VERSION ""

NS_ :

BS_:

BU_: VMCU VGGSECUSystem TECU OBDScanT2 HMIIOM EMS ECUspare2 ECUspare1 DACU CIOM BBM

BO_ 2634019608 Debug17_TECU_BB2: 8 TECU
 SG_ Debug_17_TECU : 0|64@1+ (1,0) [0|0] "" Vector__XXX

BO_ 2634019352 Debug16_TECU_BB2: 8 TECU
 SG_ Debug_16_TECU : 0|64@1+ (1,0) [0|0] "" Vector__XXX

BO_ 2634018584 Debug15_TECU_BB2: 8 TECU
 SG_ Debug_15_TECU : 0|64@1+ (1,0) [0|0] "" Vector__XXX

BO_ 2634018328 Debug14_TECU_BB2: 8 TECU
 SG_ Debug_14_TECU : 0|64@1+ (1,0) [0|0] "" Vector__XXX

BO_ 2634018072 Debug13_TECU_BB2: 8 TECU
 SG_ Debug_13_TECU : 0|64@1+ (1,0) [0|0] "" Vector__XXX

BO_ 2634017816 Debug12_TECU_BB2: 8 TECU
 SG_ Debug_12_TECU : 0|64@1+ (1,0) [0|0] "" Vector__XXX

BO_ 2634017560 Debug11_TECU_BB2: 8 TECU
 SG_ Debug_11_TECU : 0|64@1+ (1,0) [0|0] "" Vector__XXX

BO_ 2634021712 Debug11_DACU_BB2: 8 DACU
 SG_ Debug_11_DACU : 0|64@1+ (1,0) [0|0] "" Vector__XXX

BO_ 2634017304 Debug10_TECU_BB2: 8 TECU
 SG_ Debug_10_TECU : 0|64@1+ (1,0) [0|0] "" Vector__XXX

BO_ 2634021456 Debug10_DACU_BB2: 8 DACU
 SG_ Debug_10_DACU : 0|64@1+ (1,0) [0|0] "" Vector__XXX

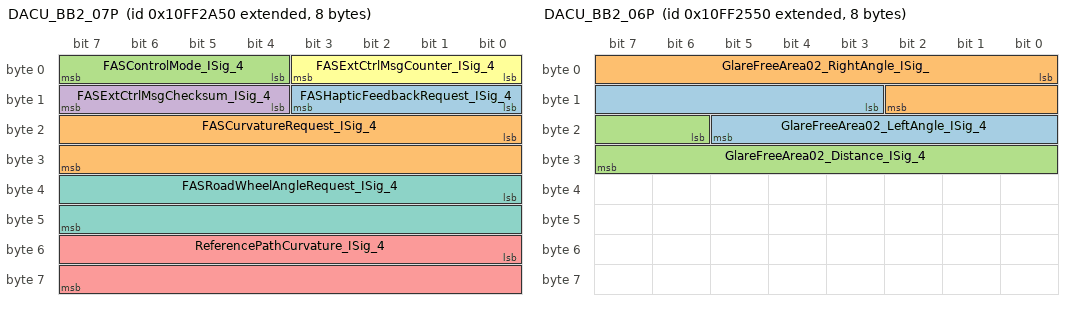
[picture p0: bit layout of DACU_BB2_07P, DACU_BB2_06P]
BO_ 2432641616 DACU_BB2_07P: 8 DACU
 SG_ FASHapticFeedbackRequest_ISig_4 : 8|4@1+ (1,0) [0|0] ""  VMCU
 SG_ FASCurvatureRequest_ISig_4 : 16|16@1+ (7.62939E-006,-0.2472) [-0.2472|0.25279207365] "per_meter"  VMCU
 SG_ FASControlMode_ISig_4 : 4|4@1+ (0.1,0) [0|1.5] ""  VMCU
 SG_ FASExtCtrlMsgChecksum_ISig_4 : 12|4@1+ (1,0) [0|0] ""  VMCU
 SG_ ReferencePathCurvature_ISig_4 : 48|16@1+ (7.62939E-006,-0.2472) [-0.2472|0.25279207365] "per_meter"  VMCU
 SG_ FASExtCtrlMsgCounter_ISig_4 : 0|4@1+ (1,0) [0|0] ""  VMCU
 SG_ FASRoadWheelAngleRequest_ISig_4 : 32|16@1+ (5E-005,-1.6) [-1.6|1.67675] "rad"  VMCU

BO_ 2432640336 DACU_BB2_06P: 8 DACU
 SG_ GlareFreeArea02_LeftAngle_ISig_4 : 11|11@1+ (0.0494,-31.65) [-31.65|69.4718] "deg"  VMCU
 SG_ GlareFreeArea02_RightAngle_ISig_ : 0|11@1+ (0.0494,-31.65) [-31.65|69.4718] "deg"  VMCU
 SG_ GlareFreeArea02_Distance_ISig_4 : 22|10@1+ (0.5,0) [0|511.5] "m"  VMCU

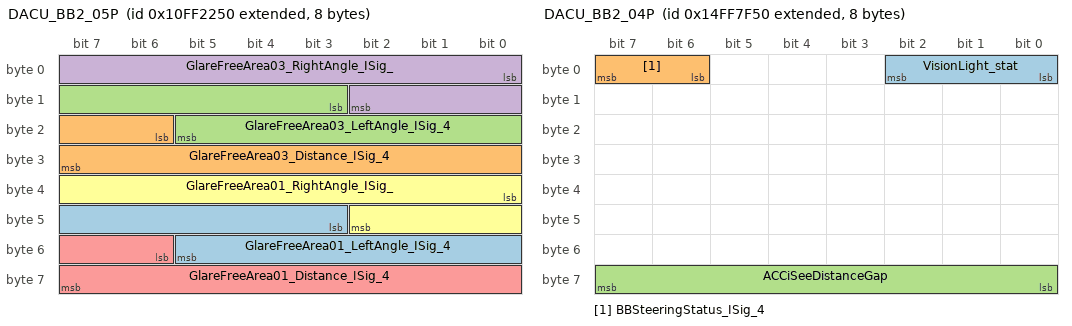
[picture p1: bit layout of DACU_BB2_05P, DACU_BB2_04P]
BO_ 2432639568 DACU_BB2_05P: 8 DACU
 SG_ GlareFreeArea01_LeftAngle_ISig_4 : 43|11@1+ (0.0494,-31.65) [-31.65|69.4718] "deg"  VMCU
 SG_ GlareFreeArea03_Distance_ISig_4 : 22|10@1+ (0.5,0) [0|511.5] "m"  VMCU
 SG_ GlareFreeArea03_LeftAngle_ISig_4 : 11|11@1+ (0.0494,-31.65) [-31.65|69.4718] "deg"  VMCU
 SG_ GlareFreeArea03_RightAngle_ISig_ : 0|11@1+ (0.0494,-31.65) [-31.65|69.4718] "deg"  VMCU
 SG_ GlareFreeArea01_Distance_ISig_4 : 54|10@1+ (0.5,0) [0|511.5] "m"  VMCU
 SG_ GlareFreeArea01_RightAngle_ISig_ : 32|11@1+ (0.0494,-31.65) [-31.65|69.4718] "deg"  VMCU

BO_ 2499772240 DACU_BB2_04P: 8 DACU
 SG_ VisionLight_stat : 0|3@1+ (1,0) [0|0] ""  VMCU
 SG_ BBSteeringStatus_ISig_4 : 6|2@1+ (1,0) [0|0] ""  BBM
 SG_ ACCiSeeDistanceGap : 56|8@1+ (1,-127) [-127|128] "m"  TECU

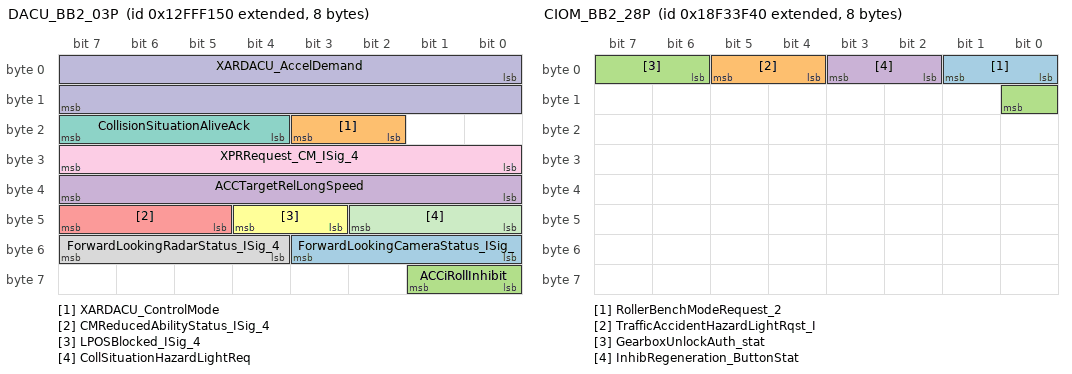
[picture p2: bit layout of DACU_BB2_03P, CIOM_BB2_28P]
BO_ 2466246992 DACU_BB2_03P: 8 DACU
 SG_ ForwardLookingCameraStatus_ISig_ : 48|4@1+ (1,0) [0|0] ""  HMIIOM
 SG_ XARDACU_ControlMode : 18|2@1+ (1,0) [0|0] ""  EMS,TECU
 SG_ ACCiRollInhibit : 56|2@1+ (1,0) [0|0] ""  TECU
 SG_ ACCTargetRelLongSpeed : 32|8@1+ (1,-125) [-125|130] "Km_per_h"  HMIIOM
 SG_ CMReducedAbilityStatus_ISig_4 : 45|3@1+ (1,0) [0|0] ""  HMIIOM
 SG_ LPOSBlocked_ISig_4 : 43|2@1+ (1,0) [0|0] ""  HMIIOM
 SG_ CollisionSituationAliveAck : 20|4@1+ (1,0) [0|15] "Count"  VMCU
 SG_ ForwardLookingRadarStatus_ISig_4 : 52|4@1+ (1,0) [0|0] ""  HMIIOM
 SG_ XPRRequest_CM_ISig_4 : 24|8@1+ (1,0) [0|255] "NotApplicable"  VMCU
 SG_ XARDACU_AccelDemand : 0|16@1+ (0.00048828125,-15.687) [-15.687|16.31251171875] "m_per_s_squared"  EMS,TECU
 SG_ CollSituationHazardLightReq : 40|3@1+ (1,0) [0|0] ""  VMCU

BO_ 2432690512 DACU_BB2_02P: 8 DACU
 SG_ PathDeviationDriverAlert_ISig_4 : 24|3@1+ (1,0) [0|0] ""  HMIIOM,VMCU
 SG_ CM_DisengageDrivelineRequest : 51|2@1+ (1,0) [0|0] ""  TECU
 SG_ ACCBrakeRequestStatus : 30|2@1+ (1,0) [0|0] ""  VMCU
 SG_ FrontalCollisionDriverAlert_ISig : 19|3@1+ (1,0) [0|0] ""  HMIIOM,VMCU
 SG_ ACCBrakeCapacityWarning_ISig_4 : 38|2@1+ (1,0) [0|0] ""  HMIIOM
 SG_ ACC_SGOFaultCondStat_SeatBelt_IS : 59|1@1+ (1,0) [0|0] ""  HMIIOM
 SG_ CM_Status_ISig_4 : 43|3@1+ (1,0) [0|0] ""  CIOM,VMCU,HMIIOM
 SG_ DASApplicationStatus_ISig_4 : 40|3@1+ (1,0) [0|0] ""  HMIIOM,VMCU,CIOM
 SG_ ACC_Status_ISig_4 : 16|3@1+ (1,0) [0|0] ""  VMCU,HMIIOM,TECU
 SG_ LKSApplicationStatus_ISig_4 : 27|3@1+ (1,0) [0|0] ""  CIOM,VMCU,HMIIOM
 SG_ LCSSystemStatus : 48|3@1+ (1,0) [0|0] ""  HMIIOM,CIOM
 SG_ ACC_SGOFaultCondStat_SigStat_ISi : 60|1@1+ (1,0) [0|0] ""  HMIIOM
 SG_ ACC_SGOFaultCondStat_Target_ISig : 58|1@1+ (1,0) [0|0] ""  HMIIOM
 SG_ FCW_Status_ISig_4 : 46|2@1+ (1,0) [0|0] ""  HMIIOM,CIOM,VMCU
 SG_ DriverImpairedDriverAlert_ISig_4 : 32|3@1+ (1,0) [0|0] ""  HMIIOM,VMCU
 SG_ DriverVigilanceLevel_ISig_4 : 35|3@1+ (1,0) [0|0] ""  HMIIOM,VMCU
 SG_ ACCForwardVehicleSpeed_ISig_4 : 8|8@1+ (1,0) [0|255] "Km_per_h"  TECU,HMIIOM
 SG_ ACC_SGOFaultCondStat_Door_ISig_4 : 57|1@1+ (1,0) [0|0] ""  HMIIOM
 SG_ ACCTargetDetected_ISig_4 : 22|2@1+ (1,0) [0|0] ""  HMIIOM
 SG_ ACCForwardVehicleDistance_ISig_4 : 0|8@1+ (1,0) [0|255] "m"  TECU,HMIIOM
 SG_ LKSCorrectiveSteeringStatus : 61|3@1+ (1,0) [0|0] ""  CIOM,HMIIOM
 SG_ ACC_SGOFaultCondStat_Other_ISig_ : 55|1@1+ (1,0) [0|0] ""  HMIIOM
 SG_ LCSSoundSettingStatus : 53|2@1+ (1,0) [0|0] ""  HMIIOM
 SG_ ACC_SGOFaultCondStat_Speed_ISig_ : 56|1@1+ (1,0) [0|0] ""  HMIIOM

BO_ 2499750528 CIOM_BB2_30S_FCM: 8 TECU
 SG_ CIOM_BB2_30S_FCS : 0|64@1+ (1,0) [0|0] ""  CIOM

BO_ 2499750527 CIOM_BB2_30S: 16 CIOM
 SG_ EncryptedGBUnlockAuth_stat : 0|128@1+ (1,0) [0|0] ""  TECU

BO_ 2432685120 CIOM_BB2_29P: 8 CIOM
 SG_ LKSCSEnableSwitch_rqst : 0|2@1+ (1,0) [0|0] ""  DACU

BO_ 2566078272 CIOM_BB2_28P: 8 CIOM
 SG_ RollerBenchModeRequest_2 : 0|2@1+ (1,0) [0|0] ""  HMIIOM
 SG_ TrafficAccidentHazardLightRqst_I : 4|2@1+ (1,0) [0|0] ""  VMCU
 SG_ GearboxUnlockAuth_stat : 6|3@1+ (1,0) [0|0] ""  TECU
 SG_ InhibRegeneration_ButtonStat : 2|2@1+ (1,0) [0|0] ""  HMIIOM

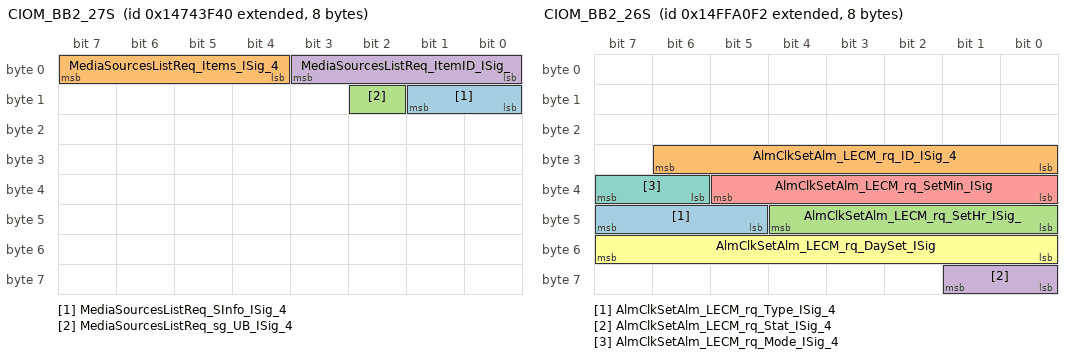
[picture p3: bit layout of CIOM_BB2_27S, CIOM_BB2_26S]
BO_ 2490646336 CIOM_BB2_27S: 8 CIOM
 SG_ MediaSourcesListReq_SInfo_ISig_4 : 8|2@1+ (1,0) [0|0] ""  HMIIOM
 SG_ MediaSourcesListReq_Items_ISig_4 : 4|4@1+ (1,0) [0|0] ""  HMIIOM
 SG_ MediaSourcesListReq_sg_UB_ISig_4 : 10|1@1+ (1,0) [0|0] ""  HMIIOM
 SG_ MediaSourcesListReq_ItemID_ISig_ : 0|4@1+ (1,0) [0|0] ""  HMIIOM

BO_ 2499780850 CIOM_BB2_26S: 8 CIOM
 SG_ AlmClkSetAlm_LECM_rq_Type_ISig_4 : 45|3@1+ (1,0) [0|0] ""  HMIIOM
 SG_ AlmClkSetAlm_LECM_rq_ID_ISig_4 : 24|7@1+ (1,0) [0|0] ""  HMIIOM
 SG_ AlmClkSetAlm_LECM_rq_SetHr_ISig_ : 40|5@1+ (1,0) [0|31] "h"  HMIIOM
 SG_ AlmClkSetAlm_LECM_rq_Stat_ISig_4 : 56|2@1+ (1,0) [0|0] ""  HMIIOM
 SG_ AlmClkSetAlm_LECM_rq_SetMin_ISig : 32|6@1+ (1,0) [0|63] "min"  HMIIOM
 SG_ AlmClkSetAlm_LECM_rq_DaySet_ISig : 48|8@1+ (1,0) [0|255] ""  HMIIOM
 SG_ AlmClkSetAlm_LECM_rq_Mode_ISig_4 : 38|2@1+ (1,0) [0|0] ""  HMIIOM

BO_ 2482978624 CIOM_BB2_25P: 8 CIOM
 SG_ TipperTailGateRequest_UB_ISig_4 : 23|1@1+ (1,0) [0|0] ""  BBM
 SG_ LoadDistributionRequested_UB_ISi : 36|1@1+ (1,0) [0|0] ""  VMCU
 SG_ TipperUpDownRequest_ISig_4 : 17|3@1+ (1,0) [0|0] ""  BBM
 SG_ TipperTarpaulinRequest_UB_ISig_4 : 27|1@1+ (1,0) [0|0] ""  BBM
 SG_ LoadDistributionRequested_ISig_4 : 28|4@1+ (1,0) [0|0] ""  VMCU
 SG_ TipperShakerRequest_UB_ISig_4 : 21|1@1+ (1,0) [0|0] ""  BBM
 SG_ TailLiftMotionRequest_UB_ISig_4 : 20|1@1+ (1,0) [0|0] ""  BBM
 SG_ TipperTailGateRequest_ISig_4 : 8|3@1+ (1,0) [0|0] ""  BBM
 SG_ TipperTippingBodySelection_ISig_ : 6|2@1+ (1,0) [0|0] ""  BBM
 SG_ TipperEmergencyStop_ISig_4 : 0|2@1+ (1,0) [0|0] ""  BBM
 SG_ TipperTippingBodySelection_UB_IS : 26|1@1+ (1,0) [0|0] ""  BBM
 SG_ ExtraBbWrcWatchdog_ISig_4 : 2|2@1+ (1,0) [0|0] ""  BBM
 SG_ TipperEmergencyStop_UB_ISig_4 : 25|1@1+ (1,0) [0|0] ""  BBM
 SG_ AutoFrontWheelDriveDrvReq : 37|2@1+ (1,0) [0|0] ""  VMCU
 SG_ FrontalCollisionAccidentStatus_I : 39|2@1+ (1,0) [0|0] ""  DACU
 SG_ ShortStopHeater_cmd_ISig_4 : 34|2@1+ (1,0) [0|0] ""  VMCU
 SG_ TipperUpDownRequest_UB_ISig_4 : 24|1@1+ (1,0) [0|0] ""  BBM
 SG_ TailLiftMotionRequest_ISig_4 : 14|3@1+ (1,0) [0|0] ""  BBM
 SG_ TipperShakerRequest_ISig_4 : 4|2@1+ (1,0) [0|0] ""  BBM
 SG_ TipperTarpaulinRequest_ISig_4 : 11|3@1+ (1,0) [0|0] ""  BBM
 SG_ ExtraHeating_status_ISig_4 : 32|2@1+ (1,0) [0|0] ""  HMIIOM
 SG_ ExtraBbWrcWatchdog_UB_ISig_4 : 22|1@1+ (1,0) [0|0] ""  BBM

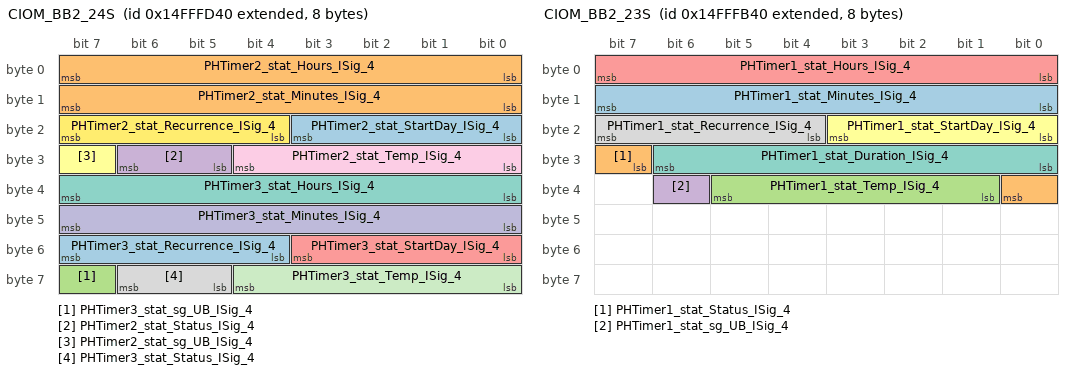
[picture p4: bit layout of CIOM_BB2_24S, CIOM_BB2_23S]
BO_ 2499804480 CIOM_BB2_24S: 8 CIOM
 SG_ PHTimer3_stat_Recurrence_ISig_4 : 52|4@1+ (1,0) [0|0] ""  HMIIOM
 SG_ PHTimer2_stat_Hours_ISig_4 : 0|8@1+ (1,0) [0|255] "h"  HMIIOM
 SG_ PHTimer3_stat_sg_UB_ISig_4 : 63|1@1+ (1,0) [0|0] ""  HMIIOM
 SG_ PHTimer2_stat_Status_ISig_4 : 29|2@1+ (1,0) [0|0] ""  HMIIOM
 SG_ PHTimer3_stat_StartDay_ISig_4 : 48|4@1+ (1,0) [0|0] ""  HMIIOM
 SG_ PHTimer2_stat_sg_UB_ISig_4 : 31|1@1+ (1,0) [0|0] ""  HMIIOM
 SG_ PHTimer3_stat_Hours_ISig_4 : 32|8@1+ (1,0) [0|255] "h"  HMIIOM
 SG_ PHTimer3_stat_Status_ISig_4 : 61|2@1+ (1,0) [0|0] ""  HMIIOM
 SG_ PHTimer2_stat_Temp_ISig_4 : 24|5@1+ (1,0) [0|0] ""  HMIIOM
 SG_ PHTimer3_stat_Minutes_ISig_4 : 40|8@1+ (1,0) [0|255] "min"  HMIIOM
 SG_ PHTimer3_stat_Temp_ISig_4 : 56|5@1+ (1,0) [0|0] ""  HMIIOM
 SG_ PHTimer2_stat_Recurrence_ISig_4 : 20|4@1+ (1,0) [0|0] ""  HMIIOM
 SG_ PHTimer2_stat_StartDay_ISig_4 : 16|4@1+ (1,0) [0|0] ""  HMIIOM
 SG_ PHTimer2_stat_Minutes_ISig_4 : 8|8@1+ (1,0) [0|255] "min"  HMIIOM

BO_ 2499803968 CIOM_BB2_23S: 8 CIOM
 SG_ PHTimer1_stat_Minutes_ISig_4 : 8|8@1+ (1,0) [0|255] "min"  HMIIOM
 SG_ PHTimer1_stat_Status_ISig_4 : 31|2@1+ (1,0) [0|0] ""  HMIIOM
 SG_ PHTimer1_stat_Temp_ISig_4 : 33|5@1+ (1,0) [0|0] ""  HMIIOM
 SG_ PHTimer1_stat_sg_UB_ISig_4 : 38|1@1+ (1,0) [0|0] ""  HMIIOM
 SG_ PHTimer1_stat_Hours_ISig_4 : 0|8@1+ (1,0) [0|255] "h"  HMIIOM
 SG_ PHTimer1_stat_StartDay_ISig_4 : 16|4@1+ (1,0) [0|0] ""  HMIIOM
 SG_ PHTimer1_stat_Duration_ISig_4 : 24|7@1+ (1,0) [0|127] "min"  HMIIOM
 SG_ PHTimer1_stat_Recurrence_ISig_4 : 20|4@1+ (1,0) [0|0] ""  HMIIOM

BO_ 2499801342 CIOM_BB2_22S_FCM: 8 HMIIOM
 SG_ CIOM_BB2_22S_FCS : 0|64@1+ (1,0) [0|1] ""  CIOM

BO_ 2499801341 CIOM_BB2_22S: 10 CIOM
 SG_ EngineTimer_stat_Timer3StartDay_ : 20|4@1+ (1,0) [0|0] ""  HMIIOM
 SG_ EngineTimer_stat_Timer3_Status_I : 76|2@1+ (1,0) [0|0] ""  HMIIOM
 SG_ EngineTimer_stat_Timer3Minutes_I : 56|8@1+ (1,0) [0|255] "min"  HMIIOM
 SG_ EngineTimer_stat_Timer3Hours_ISi : 32|8@1+ (1,0) [0|255] "h"  HMIIOM
 SG_ EngineTimer_stat_Timer3Recurr_IS : 8|4@1+ (1,0) [0|0] ""  HMIIOM
 SG_ EngineTimer_stat_Timer1Hours_ISi : 40|8@1+ (1,0) [0|255] "h"  HMIIOM
 SG_ EngineTimer_stat_Timer2Hours_ISi : 48|8@1+ (1,0) [0|255] "h"  HMIIOM
 SG_ EngineTimer_stat_sg_UB_ISig_4 : 78|1@1+ (1,0) [0|0] ""  HMIIOM
 SG_ EngineTimer_stat_Timer2StartDay_ : 16|4@1+ (1,0) [0|0] ""  HMIIOM
 SG_ EngineTimer_stat_Timer1Recurr_IS : 0|4@1+ (1,0) [0|0] ""  HMIIOM
 SG_ EngineTimer_stat_Timer2Recurr_IS : 4|4@1+ (1,0) [0|0] ""  HMIIOM
 SG_ EngineTimer_stat_Timer1Minutes_I : 24|8@1+ (1,0) [0|255] "min"  HMIIOM
 SG_ EngineTimer_stat_Timer1StartDay_ : 12|4@1+ (1,0) [0|0] ""  HMIIOM
 SG_ EngineTimer_stat_Timer2_Status_I : 74|2@1+ (1,0) [0|0] ""  HMIIOM
 SG_ EngineTimer_stat_Timer2Minutes_I : 64|8@1+ (1,0) [0|255] "min"  HMIIOM
 SG_ EngineTimer_stat_Timer1_Status_I : 72|2@1+ (1,0) [0|0] ""  HMIIOM

BO_ 2516513011 CIOM_BB2_21S: 8 CIOM
 SG_ DynamicCode_value : 0|32@1+ (1,0) [0|4294967295] "NotApplicable"  HMIIOM

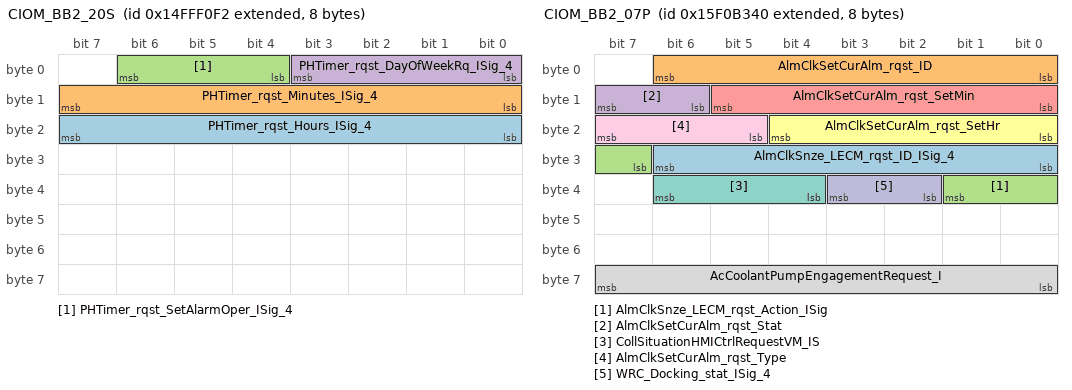
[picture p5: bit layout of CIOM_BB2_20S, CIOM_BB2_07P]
BO_ 2499801330 CIOM_BB2_20S: 8 CIOM
 SG_ PHTimer_rqst_Hours_ISig_4 : 16|8@1+ (1,0) [0|255] "h"  HMIIOM
 SG_ PHTimer_rqst_Minutes_ISig_4 : 8|8@1+ (1,0) [0|255] "min"  HMIIOM
 SG_ PHTimer_rqst_SetAlarmOper_ISig_4 : 4|3@1+ (1,0) [0|0] ""  HMIIOM
 SG_ PHTimer_rqst_DayOfWeekRq_ISig_4 : 0|4@1+ (1,0) [0|0] ""  HMIIOM

BO_ 2499764033 CIOM_BB2_13S_FCM: 8 EMS
 SG_ CIOM_BB2_13S_FCS : 0|64@1+ (1,0) [0|0] ""  CIOM

BO_ 2499764032 CIOM_BB2_13S: 16 CIOM
 SG_ EngineStartAuth_stat : 0|128@1+ (1,0) [0|0] ""  EMS

BO_ 2499747649 CIOM_BB2_12S_FCM: 8 VMCU
 SG_ CIOM_BB2_12S_FCS : 0|64@1+ (1,0) [0|0] ""  CIOM

BO_ 2499747648 CIOM_BB2_12S: 16 CIOM
 SG_ KeyAuthEncrypted_stat : 0|128@1+ (1,0) [0|0] ""  VMCU

BO_ 2498741568 CIOM_BB2_11P: 8 CIOM
 SG_ WindscreenDefrostInd_cmd_ISig_4 : 0|1@1+ (1,0) [0|0] ""  HMIIOM
 SG_ ACCoolingFanSpeedRequest : 32|16@1+ (1,0) [0|65535] "rpm"  EMS
 SG_ AutoMode_IndicationCmd_ISig_4 : 1|1@1+ (1,0) [0|0] ""  HMIIOM
 SG_ CabTilt_rqst : 4|2@1+ (1,0) [0|0] ""  VMCU
 SG_ ACdisplayIndication_Cmd_ISig_4 : 53|3@1+ (1,0) [0|0] ""  HMIIOM
 SG_ TemperatureRqstIndication_cmd_IS : 48|5@1+ (1,0) [0|0] ""  HMIIOM
 SG_ Pto3CabRequest : 6|2@1+ (1,0) [0|0] ""  BBM,VMCU
 SG_ Pto4CabRequest : 16|2@1+ (1,0) [0|0] ""  VMCU,BBM
 SG_ ACCoolingFanSpeedRequest_UB : 61|1@1+ (1,0) [0|0] ""  EMS
 SG_ SRSAirbagStatus_ISig_4 : 8|2@1+ (1,0) [0|0] ""  HMIIOM,VMCU
 SG_ Area_9level_Indication_cmd_ISig_ : 18|4@1+ (1,0) [0|0] ""  HMIIOM
 SG_ AutoDefogIndication_Cmd_ISig_4 : 27|3@1+ (1,0) [0|0] ""  HMIIOM
 SG_ FrontLidAjar_Stat : 30|2@1+ (1,0) [0|0] ""  VMCU
 SG_ ParkingHeaterCleaning_Rqst_ISig_ : 22|2@1+ (1,0) [0|0] ""  HMIIOM
 SG_ Pto2CabRequest : 12|2@1+ (1,0) [0|0] ""  BBM,VMCU
 SG_ AutoBlowerLevelIndication_Cmd_IS : 24|3@1+ (1,0) [0|0] ""  HMIIOM
 SG_ SeatSwivelWarning_rqst : 14|2@1+ (1,0) [0|0] ""  HMIIOM
 SG_ AQSmodeIndication_Cmd_ISig_4 : 2|2@1+ (1,0) [0|0] ""  HMIIOM
 SG_ TemporaryRSLDriverRequest : 59|2@1+ (1,0) [0|0] ""  VMCU
 SG_ Pto1CabRequest : 10|2@1+ (1,0) [0|0] ""  VMCU,BBM

BO_ 2483023936 CIOM_BB2_10P: 8 CIOM
 SG_ LCS_EnableSwitch_rqst : 40|2@1+ (1,0) [0|0] ""  DACU
 SG_ PH_Activation_cmd_ISig_4 : 33|3@1+ (1,0) [0|0] ""  HMIIOM
 SG_ EscCrossCountryActivation_rqst : 52|2@1+ (1,0) [0|0] ""  VMCU
 SG_ StaticCornerLightMode : 54|2@1+ (1,0) [0|0] ""  VMCU
 SG_ SplitBoxDifflockActvnDrvrRqst_IS : 48|2@1+ (1,0) [0|0] ""  HMIIOM,EMS,VMCU,TECU
 SG_ ConstructionSwitch_stat : 50|2@1+ (1,0) [0|0] ""  TECU,HMIIOM
 SG_ ATCFrontWheelDriveRequest : 61|2@1+ (1,0) [0|0] ""  HMIIOM
 SG_ EscCabActionRequest : 8|3@1+ (1,0) [0|0] ""  VMCU
 SG_ AdjustRequestForIdle : 58|3@1+ (1,0) [0|0] ""  VMCU
 SG_ SCL_LogicPowerOutput_stat : 36|2@1+ (1,0) [0|0] ""  VMCU
 SG_ PinCode_validity_time : 0|8@1+ (1,1) [1|256] "h"  HMIIOM
 SG_ StatTrailerBrakeSwitchStatus : 14|2@1+ (1,0) [0|0] ""  VMCU
 SG_ SplitBoxDifflockActvnDrvrRqst_UB : 32|1@1+ (1,0) [0|0] ""  EMS,TECU,VMCU,HMIIOM
 SG_ RoofHatch_HMI_rqst : 16|3@1+ (1,0) [0|0] ""  VMCU
 SG_ EscCabEnable : 38|2@1+ (1,0) [0|0] ""  HMIIOM,VMCU
 SG_ ExtraSideMarkers_Rqst : 19|2@1+ (1,0) [0|0] ""  VMCU
 SG_ LevelingThumbwheel_stat : 24|5@1+ (1,0) [0|0] ""  VMCU
 SG_ MemoDisplayIndication_Cmd_ISig_4 : 11|3@1+ (1,0) [0|0] ""  HMIIOM
 SG_ FCW_Enable : 42|2@1+ (1,0) [0|0] ""  DACU
 SG_ DASActivation_rqst : 44|2@1+ (1,0) [0|0] ""  DACU
 SG_ DriverSeatBeltSwitch_ISig_4 : 22|2@1+ (1,0) [0|0] ""  VMCU,DACU,BBM,HMIIOM
 SG_ PinCode_stat : 29|3@1+ (1,0) [0|0] ""  HMIIOM
 SG_ WarmUp_Request : 56|2@1+ (1,0) [0|0] ""  EMS
 SG_ LKSEnableSwitch_rqst : 46|2@1+ (1,0) [0|0] ""  DACU

BO_ 2515579712 CIOM_BB2_07P: 8 CIOM
 SG_ AlmClkSnze_LECM_rqst_ID_ISig_4 : 24|7@1+ (1,0) [0|0] ""  HMIIOM
 SG_ AlmClkSetCurAlm_rqst_ID : 0|7@1+ (1,0) [0|0] ""  HMIIOM
 SG_ AlmClkSnze_LECM_rqst_Action_ISig : 31|3@1+ (1,0) [0|0] ""  HMIIOM
 SG_ AlmClkSetCurAlm_rqst_Stat : 14|2@1+ (1,0) [0|0] ""  HMIIOM
 SG_ AlmClkSetCurAlm_rqst_SetMin : 8|6@1+ (1,0) [0|63] "min"  HMIIOM
 SG_ AlmClkSetCurAlm_rqst_SetHr : 16|5@1+ (1,0) [0|31] "h"  HMIIOM
 SG_ CollSituationHMICtrlRequestVM_IS : 36|3@1+ (1,0) [0|0] ""  HMIIOM
 SG_ AcCoolantPumpEngagementRequest_I : 56|8@1+ (0.4,0) [0|102] "Percent"  EMS
 SG_ AlmClkSetCurAlm_rqst_Type : 21|3@1+ (1,0) [0|0] ""  HMIIOM
 SG_ WRC_Docking_stat_ISig_4 : 34|2@1+ (1,0) [0|0] ""  HMIIOM

BO_ 2482995008 CIOM_BB2_06P: 8 CIOM
 SG_ LiftAxle1DirectControl_UB_ISig_4 : 59|1@1+ (1,0) [0|0] ""  VMCU
 SG_ Regeneration2PosSwitchStatus : 54|2@1+ (1,0) [0|0] ""  HMIIOM
 SG_ WRCEngineStopRequest_ISig_4 : 38|2@1+ (1,0) [0|0] ""  BBM
 SG_ LiftAxle1DirectControl_ISig_4 : 56|3@1+ (1,0) [0|0] ""  VMCU
 SG_ PanicAlarmFromKeyfob_rqst : 2|2@1+ (1,0) [0|0] ""  VMCU
 SG_ InhibRegenerationSwitch_stat : 42|2@1+ (1,0) [0|0] ""  HMIIOM
 SG_ ParkingClimate_IndicationCmd_ISi : 51|3@1+ (1,0) [0|0] ""  HMIIOM
 SG_ DriverDoorAjar_stat_ISig_4 : 27|3@1+ (1,0) [0|0] ""  HMIIOM
 SG_ WRCEngineStartRequest_ISig_4 : 36|2@1+ (1,0) [0|0] ""  BBM
 SG_ RegenerationPushButtonStatus_ISi : 60|2@1+ (1,0) [0|0] ""  HMIIOM
 SG_ RegenerationSwitchStatus_ISig_4 : 48|3@1+ (1,0) [0|0] ""  HMIIOM
 SG_ DoorLock_stat_ISig_4 : 8|4@1+ (1,0) [0|0] ""  BBM,HMIIOM
 SG_ WRCEngineStartRequest_UB_ISig_4 : 40|1@1+ (1,0) [0|0] ""  BBM
 SG_ LuggageAjar_stat_ISig_4 : 32|3@1+ (1,0) [0|0] ""  HMIIOM
 SG_ AlarmStatus_stat_ISig_4 : 44|4@1+ (1,0) [0|0] ""  HMIIOM
 SG_ AlarmTriggeringCause_stat_ISig_4 : 12|4@1+ (1,0) [0|0] ""  HMIIOM
 SG_ DoorsAjar_stat_UB_ISig_4 : 35|1@1+ (1,0) [0|0] ""  DACU,VMCU,HMIIOM,BBM
 SG_ DoorsAjar_stat_ISig_4 : 16|3@1+ (1,0) [0|0] ""  HMIIOM,VMCU,DACU,BBM
 SG_ WRCEngineStopRequest_UB_ISig_4 : 41|1@1+ (1,0) [0|0] ""  BBM
 SG_ DoorAutoFunction_rqst : 22|2@1+ (1,0) [0|0] ""  VMCU

CM_ SG_ 2466246992 XARDACU_AccelDemand "65024 - 65279 Error ; 65280 - 65535 Not available";
CM_ SG_ 2432690512 ACCForwardVehicleSpeed_ISig_4 "254 Error ; 255 Not available";
CM_ SG_ 2432690512 ACCForwardVehicleDistance_ISig_4 "254 Error ; 255 Not Available";
CM_ SG_ 2499780850 AlmClkSetAlm_LECM_rq_SetHr_ISig_ "30 Error ; 31 Not Available";
CM_ SG_ 2499780850 AlmClkSetAlm_LECM_rq_SetMin_ISig "62 Error ; 63 Not Available";
CM_ SG_ 2499804480 PHTimer2_stat_Hours_ISig_4 "254 Error ; 255 Not available";
CM_ SG_ 2499804480 PHTimer3_stat_Hours_ISig_4 "254 Error ; 255 Not available";
CM_ SG_ 2499804480 PHTimer3_stat_Minutes_ISig_4 "254 Error ; 255 Not available";
CM_ SG_ 2499804480 PHTimer2_stat_Minutes_ISig_4 "254 Error ; 255 Not available";
CM_ SG_ 2499803968 PHTimer1_stat_Minutes_ISig_4 "254 Error ; 255 Not available";
CM_ SG_ 2499803968 PHTimer1_stat_Hours_ISig_4 "254 Error ; 255 Not available";
CM_ SG_ 2499803968 PHTimer1_stat_Duration_ISig_4 "126 Error ; 127 Not available";
CM_ SG_ 2499801341 EngineTimer_stat_Timer3Minutes_I "254 Error ; 255 Not available";
CM_ SG_ 2499801341 EngineTimer_stat_Timer3Hours_ISi "254 Error ; 255 Not available";
CM_ SG_ 2499801341 EngineTimer_stat_Timer1Hours_ISi "254 Error ; 255 Not available";
CM_ SG_ 2499801341 EngineTimer_stat_Timer2Hours_ISi "254 Error ; 255 Not available";
CM_ SG_ 2499801341 EngineTimer_stat_Timer1Minutes_I "254 Error ; 255 Not available";
CM_ SG_ 2499801341 EngineTimer_stat_Timer2Minutes_I "254 Error ; 255 Not available";
CM_ SG_ 2499801330 PHTimer_rqst_Hours_ISig_4 "254 Error ; 255 Not available";
CM_ SG_ 2499801330 PHTimer_rqst_Minutes_ISig_4 "254 Error ; 255 Not available";
CM_ SG_ 2498741568 ACCoolingFanSpeedRequest "65024 - 65279 Error ; 65280 - 65535 Not available";
BA_DEF_ BO_  "GenMsgStartDelayTime" INT 0 0;
BA_DEF_ BO_  "GenMsgDelayTime" INT 0 0;
BA_DEF_ BO_  "GenMsgCycleTime" INT 0 0;
BA_DEF_ BO_  "GenMsgSendType" ENUM  "Cyclic","NotUsed","NotUsed","NotUsed","NotUsed","NotUsed","NotUsed","IfActive","NoMsgSendType","NotUsed";
BA_DEF_ SG_  "GenSigStartValue" INT 0 0;
BA_DEF_ SG_  "GenSigCycleTimeActive" INT 0 0;
BA_DEF_ SG_  "GenSigCycleTime" INT 0 0;
BA_DEF_ SG_  "GenSigSendType" ENUM  "Cyclic","OnWrite","OnWriteWithRepetition","OnChange","OnChangeWithRepetition","IfActive","IfActiveWithRepetition","NoSigSendType","NotUsed","NotUsed","NotUsed","NotUsed","NotUsed";
BA_DEF_ BO_  "VFrameFormat" ENUM  "StandardCAN","ExtendedCAN","reserved","J1939PG";
BA_DEF_ SG_  "SigType" ENUM  "Default","Range","RangeSigned","ASCII","Discrete","Control","ReferencePGN","DTC","StringDelimiter","StringLength","StringLengthControl";
BA_DEF_ SG_  "SeToolVersion_SIGNAL" STRING ;
BA_DEF_ SG_  "SeToolUniqueID_SIGNAL" STRING ;
BA_DEF_ SG_  "SeToolOwnerSigGroup_SIGNAL" STRING ;
BA_DEF_ SG_  "SeToolOwnerSigGroupID_SIGNAL" STRING ;
BA_DEF_ SG_  "SeToolName_SIGNAL" STRING ;
BA_DEF_ SG_  "SeToolItemID_SIGNAL" STRING ;
BA_DEF_ SG_  "SeToolAncestorID_SIGNAL" STRING ;
BA_DEF_ SG_  "Platform_VMCU1_Sig" ENUM  "No","Yes";
BA_DEF_ BO_  "NmAsrMessage" ENUM  "No","Yes";
BA_DEF_ SG_  "NeedsUpdateBit" ENUM  "No","Yes";
BA_DEF_ SG_  "MmAnSignal" ENUM  "No","Yes";
BA_DEF_ SG_  "GenSigMaxLatency" INT 0 65535;
BA_DEF_ SG_  "GenSigILSupport" ENUM  "Yes","No";
BA_DEF_ BO_  "GenMsgRequestable" INT 0 1;
BA_DEF_ BO_  "GenMsgILSupport" ENUM  "No","Yes";
BA_DEF_ BO_  "DiagUUDTResponse" ENUM  "No","Yes";
BA_DEF_ BO_  "DiagState" ENUM  "No","Yes";
BA_DEF_ BO_  "DiagResponse" ENUM  "No","Yes";
BA_DEF_ BO_  "DiagRequest" ENUM  "No","Yes";
BA_DEF_ BO_  "DiagConnection" HEX 0 65535;
BA_DEF_ BO_  "CanTpSTmin" INT 0 255;
BA_DEF_ BO_  "CanTpFcFrameId" HEX 0 2147483647;
BA_DEF_ BO_  "CanTpBs" INT 0 255;
BA_DEF_ SG_  "SystemSignalLongSymbol" STRING ;
BA_DEF_REL_ BU_SG_REL_  "GenSigTimeoutTime" INT 0 65535;
BA_DEF_REL_ BU_SG_REL_  "GenSigFirstTimeoutTime" INT 0 65535;
BA_DEF_DEF_  "GenMsgStartDelayTime" 0;
BA_DEF_DEF_  "GenMsgDelayTime" 0;
BA_DEF_DEF_  "GenMsgCycleTime" 0;
BA_DEF_DEF_  "GenMsgSendType" "Cyclic";
BA_DEF_DEF_  "GenSigStartValue" 0;
BA_DEF_DEF_  "GenSigCycleTimeActive" 0;
BA_DEF_DEF_  "GenSigCycleTime" 0;
BA_DEF_DEF_  "GenSigSendType" "Cyclic";
BA_DEF_DEF_  "VFrameFormat" "ExtendedCAN";
BA_DEF_DEF_  "SigType" "Default";
BA_DEF_DEF_  "SeToolVersion_SIGNAL" "";
BA_DEF_DEF_  "SeToolUniqueID_SIGNAL" "";
BA_DEF_DEF_  "SeToolOwnerSigGroup_SIGNAL" "";
BA_DEF_DEF_  "SeToolOwnerSigGroupID_SIGNAL" "";
BA_DEF_DEF_  "SeToolName_SIGNAL" "";
BA_DEF_DEF_  "SeToolItemID_SIGNAL" "";
BA_DEF_DEF_  "SeToolAncestorID_SIGNAL" "";
BA_DEF_DEF_  "Platform_VMCU1_Sig" "No";
BA_DEF_DEF_  "NmAsrMessage" "No";
BA_DEF_DEF_  "NeedsUpdateBit" "No";
BA_DEF_DEF_  "MmAnSignal" "No";
BA_DEF_DEF_  "GenSigMaxLatency" 0;
BA_DEF_DEF_  "GenSigILSupport" "Yes";
BA_DEF_DEF_  "GenMsgRequestable" 1;
BA_DEF_DEF_  "GenMsgILSupport" "Yes";
BA_DEF_DEF_  "DiagUUDTResponse" "No";
BA_DEF_DEF_  "DiagState" "No";
BA_DEF_DEF_  "DiagResponse" "No";
BA_DEF_DEF_  "DiagRequest" "No";
BA_DEF_DEF_  "DiagConnection" 0;
BA_DEF_DEF_  "CanTpSTmin" 0;
BA_DEF_DEF_  "CanTpFcFrameId" 2147483647;
BA_DEF_DEF_  "CanTpBs" 255;
BA_DEF_DEF_REL_ "GenSigTimeoutTime" 0;
BA_DEF_DEF_REL_ "GenSigFirstTimeoutTime" 0;
BA_DEF_DEF_  "SystemSignalLongSymbol" "";
BA_ "GenMsgSendType" BO_ 2634019608 8;
BA_ "GenMsgDelayTime" BO_ 2634019608 195;
BA_ "GenMsgStartDelayTime" BO_ 2634019608 50;
BA_ "GenMsgSendType" BO_ 2634019352 8;
BA_ "GenMsgDelayTime" BO_ 2634019352 195;
BA_ "GenMsgStartDelayTime" BO_ 2634019352 50;
BA_ "GenMsgSendType" BO_ 2634018584 8;
BA_ "GenMsgDelayTime" BO_ 2634018584 195;
BA_ "GenMsgStartDelayTime" BO_ 2634018584 50;
BA_ "GenMsgSendType" BO_ 2634018328 8;
BA_ "GenMsgDelayTime" BO_ 2634018328 195;
BA_ "GenMsgStartDelayTime" BO_ 2634018328 50;
BA_ "GenMsgSendType" BO_ 2634018072 8;
BA_ "GenMsgDelayTime" BO_ 2634018072 195;
BA_ "GenMsgStartDelayTime" BO_ 2634018072 50;
BA_ "GenMsgSendType" BO_ 2634017816 8;
BA_ "GenMsgDelayTime" BO_ 2634017816 195;
BA_ "GenMsgStartDelayTime" BO_ 2634017816 50;
BA_ "GenMsgSendType" BO_ 2634017560 8;
BA_ "GenMsgDelayTime" BO_ 2634017560 195;
BA_ "GenMsgStartDelayTime" BO_ 2634017560 50;
BA_ "GenMsgSendType" BO_ 2634021712 8;
BA_ "GenMsgDelayTime" BO_ 2634021712 20;
BA_ "GenMsgStartDelayTime" BO_ 2634021712 50;
BA_ "GenMsgSendType" BO_ 2634017304 8;
BA_ "GenMsgDelayTime" BO_ 2634017304 15;
BA_ "GenMsgStartDelayTime" BO_ 2634017304 50;
BA_ "GenMsgSendType" BO_ 2634021456 8;
BA_ "GenMsgDelayTime" BO_ 2634021456 20;
BA_ "GenMsgStartDelayTime" BO_ 2634021456 50;
BA_ "GenMsgCycleTime" BO_ 2432641616 20;
BA_ "GenMsgStartDelayTime" BO_ 2432641616 50;
BA_ "GenMsgCycleTime" BO_ 2432640336 20;
BA_ "GenMsgStartDelayTime" BO_ 2432640336 10;
BA_ "GenMsgCycleTime" BO_ 2432639568 20;
BA_ "GenMsgStartDelayTime" BO_ 2432639568 10;
BA_ "GenMsgCycleTime" BO_ 2499772240 100;
BA_ "GenMsgStartDelayTime" BO_ 2499772240 15;
BA_ "GenMsgCycleTime" BO_ 2466246992 40;
BA_ "GenMsgStartDelayTime" BO_ 2466246992 5;
BA_ "GenMsgCycleTime" BO_ 2432690512 20;
BA_ "GenMsgILSupport" BO_ 2499750528 0;
BA_ "GenMsgSendType" BO_ 2499750528 8;
BA_ "CanTpFcFrameId" BO_ 2499750527 352266880;
BA_ "GenMsgSendType" BO_ 2499750527 8;
BA_ "GenMsgDelayTime" BO_ 2499750527 20;
BA_ "GenMsgStartDelayTime" BO_ 2499750527 50;
BA_ "GenMsgCycleTime" BO_ 2432685120 40;
BA_ "GenMsgStartDelayTime" BO_ 2432685120 50;
BA_ "GenMsgCycleTime" BO_ 2566078272 100;
BA_ "GenMsgStartDelayTime" BO_ 2566078272 50;
BA_ "GenMsgSendType" BO_ 2490646336 8;
BA_ "GenMsgDelayTime" BO_ 2490646336 50;
BA_ "GenMsgSendType" BO_ 2499780850 8;
BA_ "GenMsgDelayTime" BO_ 2499780850 75;
BA_ "GenMsgCycleTime" BO_ 2482978624 50;
BA_ "GenMsgStartDelayTime" BO_ 2482978624 50;
BA_ "GenMsgSendType" BO_ 2499804480 8;
BA_ "GenMsgDelayTime" BO_ 2499804480 50;
BA_ "GenMsgSendType" BO_ 2499803968 8;
BA_ "GenMsgDelayTime" BO_ 2499803968 50;
BA_ "GenMsgILSupport" BO_ 2499801342 0;
BA_ "GenMsgSendType" BO_ 2499801342 8;
BA_ "CanTpFcFrameId" BO_ 2499801341 352317694;
BA_ "GenMsgSendType" BO_ 2499801341 8;
BA_ "GenMsgDelayTime" BO_ 2499801341 50;
BA_ "GenMsgSendType" BO_ 2516513011 8;
BA_ "GenMsgDelayTime" BO_ 2516513011 100;
BA_ "GenMsgStartDelayTime" BO_ 2516513011 15;
BA_ "GenMsgSendType" BO_ 2499801330 8;
BA_ "GenMsgDelayTime" BO_ 2499801330 75;
BA_ "GenMsgILSupport" BO_ 2499764033 0;
BA_ "GenMsgSendType" BO_ 2499764033 8;
BA_ "CanTpFcFrameId" BO_ 2499764032 352280385;
BA_ "GenMsgSendType" BO_ 2499764032 8;
BA_ "GenMsgDelayTime" BO_ 2499764032 20;
BA_ "GenMsgILSupport" BO_ 2499747649 0;
BA_ "GenMsgSendType" BO_ 2499747649 8;
BA_ "CanTpFcFrameId" BO_ 2499747648 352264001;
BA_ "GenMsgSendType" BO_ 2499747648 8;
BA_ "GenMsgDelayTime" BO_ 2499747648 20;
BA_ "GenMsgCycleTime" BO_ 2498741568 95;
BA_ "GenMsgStartDelayTime" BO_ 2498741568 40;
BA_ "GenMsgCycleTime" BO_ 2483023936 55;
BA_ "GenMsgStartDelayTime" BO_ 2483023936 10;
BA_ "GenMsgCycleTime" BO_ 2515579712 100;
BA_ "GenMsgStartDelayTime" BO_ 2515579712 15;
BA_ "GenMsgCycleTime" BO_ 2482995008 50;
BA_ "GenMsgStartDelayTime" BO_ 2482995008 25;
BA_ "GenSigSendType" SG_ 2634019608 Debug_17_TECU 1;
BA_ "Platform_VMCU1_Sig" SG_ 2634019608 Debug_17_TECU 1;
BA_ "GenSigSendType" SG_ 2634019352 Debug_16_TECU 1;
BA_ "Platform_VMCU1_Sig" SG_ 2634019352 Debug_16_TECU 1;
BA_ "GenSigSendType" SG_ 2634018584 Debug_15_TECU 1;
BA_ "Platform_VMCU1_Sig" SG_ 2634018584 Debug_15_TECU 1;
BA_ "GenSigSendType" SG_ 2634018328 Debug_14_TECU 1;
BA_ "Platform_VMCU1_Sig" SG_ 2634018328 Debug_14_TECU 1;
BA_ "GenSigSendType" SG_ 2634018072 Debug_13_TECU 1;
BA_ "GenSigMaxLatency" SG_ 2634018072 Debug_13_TECU 55;
BA_ "Platform_VMCU1_Sig" SG_ 2634018072 Debug_13_TECU 1;
BA_ "GenSigSendType" SG_ 2634017816 Debug_12_TECU 1;
BA_ "GenSigMaxLatency" SG_ 2634017816 Debug_12_TECU 55;
BA_ "Platform_VMCU1_Sig" SG_ 2634017816 Debug_12_TECU 1;
BA_ "GenSigSendType" SG_ 2634017560 Debug_11_TECU 1;
BA_ "GenSigMaxLatency" SG_ 2634017560 Debug_11_TECU 55;
BA_ "Platform_VMCU1_Sig" SG_ 2634017560 Debug_11_TECU 1;
BA_ "GenSigSendType" SG_ 2634021712 Debug_11_DACU 1;
BA_ "GenSigCycleTime" SG_ 2634021712 Debug_11_DACU 100;
BA_ "GenSigCycleTimeActive" SG_ 2634021712 Debug_11_DACU 100;
BA_ "Platform_VMCU1_Sig" SG_ 2634021712 Debug_11_DACU 1;
BA_ "GenSigSendType" SG_ 2634017304 Debug_10_TECU 1;
BA_ "GenSigMaxLatency" SG_ 2634017304 Debug_10_TECU 55;
BA_ "Platform_VMCU1_Sig" SG_ 2634017304 Debug_10_TECU 1;
BA_ "GenSigSendType" SG_ 2634021456 Debug_10_DACU 1;
BA_ "GenSigMaxLatency" SG_ 2634021456 Debug_10_DACU 25;
BA_ "Platform_VMCU1_Sig" SG_ 2634021456 Debug_10_DACU 1;
BA_ "GenSigCycleTime" SG_ 2432641616 FASHapticFeedbackRequest_ISig_4 100;
BA_ "GenSigCycleTimeActive" SG_ 2432641616 FASHapticFeedbackRequest_ISig_4 100;
BA_ "GenSigStartValue" SG_ 2432641616 FASHapticFeedbackRequest_ISig_4 15;
BA_ "GenSigMaxLatency" SG_ 2432641616 FASHapticFeedbackRequest_ISig_4 25;
BA_ "GenSigCycleTime" SG_ 2432641616 FASCurvatureRequest_ISig_4 100;
BA_ "GenSigCycleTimeActive" SG_ 2432641616 FASCurvatureRequest_ISig_4 100;
BA_ "GenSigStartValue" SG_ 2432641616 FASCurvatureRequest_ISig_4 65535;
BA_ "GenSigMaxLatency" SG_ 2432641616 FASCurvatureRequest_ISig_4 25;
BA_ "GenSigCycleTime" SG_ 2432641616 FASControlMode_ISig_4 100;
BA_ "GenSigCycleTimeActive" SG_ 2432641616 FASControlMode_ISig_4 100;
BA_ "GenSigStartValue" SG_ 2432641616 FASControlMode_ISig_4 15;
BA_ "GenSigMaxLatency" SG_ 2432641616 FASControlMode_ISig_4 25;
BA_ "GenSigCycleTime" SG_ 2432641616 FASExtCtrlMsgChecksum_ISig_4 100;
BA_ "GenSigCycleTimeActive" SG_ 2432641616 FASExtCtrlMsgChecksum_ISig_4 100;
BA_ "GenSigMaxLatency" SG_ 2432641616 FASExtCtrlMsgChecksum_ISig_4 25;
BA_ "GenSigCycleTime" SG_ 2432641616 ReferencePathCurvature_ISig_4 100;
BA_ "GenSigCycleTimeActive" SG_ 2432641616 ReferencePathCurvature_ISig_4 100;
BA_ "GenSigStartValue" SG_ 2432641616 ReferencePathCurvature_ISig_4 65535;
BA_ "GenSigMaxLatency" SG_ 2432641616 ReferencePathCurvature_ISig_4 25;
BA_ "GenSigCycleTime" SG_ 2432641616 FASExtCtrlMsgCounter_ISig_4 100;
BA_ "GenSigCycleTimeActive" SG_ 2432641616 FASExtCtrlMsgCounter_ISig_4 100;
BA_ "GenSigMaxLatency" SG_ 2432641616 FASExtCtrlMsgCounter_ISig_4 25;
BA_ "GenSigCycleTime" SG_ 2432641616 FASRoadWheelAngleRequest_ISig_4 100;
BA_ "GenSigCycleTimeActive" SG_ 2432641616 FASRoadWheelAngleRequest_ISig_4 100;
BA_ "GenSigStartValue" SG_ 2432641616 FASRoadWheelAngleRequest_ISig_4 65535;
BA_ "GenSigMaxLatency" SG_ 2432641616 FASRoadWheelAngleRequest_ISig_4 25;
BA_ "GenSigCycleTime" SG_ 2432640336 GlareFreeArea02_LeftAngle_ISig_4 100;
BA_ "GenSigCycleTimeActive" SG_ 2432640336 GlareFreeArea02_LeftAngle_ISig_4 100;
BA_ "GenSigStartValue" SG_ 2432640336 GlareFreeArea02_LeftAngle_ISig_4 2047;
BA_ "GenSigMaxLatency" SG_ 2432640336 GlareFreeArea02_LeftAngle_ISig_4 26;
BA_ "Platform_VMCU1_Sig" SG_ 2432640336 GlareFreeArea02_LeftAngle_ISig_4 1;
BA_ "GenSigCycleTime" SG_ 2432640336 GlareFreeArea02_RightAngle_ISig_ 100;
BA_ "GenSigCycleTimeActive" SG_ 2432640336 GlareFreeArea02_RightAngle_ISig_ 100;
BA_ "GenSigStartValue" SG_ 2432640336 GlareFreeArea02_RightAngle_ISig_ 2047;
BA_ "GenSigMaxLatency" SG_ 2432640336 GlareFreeArea02_RightAngle_ISig_ 26;
BA_ "Platform_VMCU1_Sig" SG_ 2432640336 GlareFreeArea02_RightAngle_ISig_ 1;
BA_ "SystemSignalLongSymbol" SG_ 2432640336 GlareFreeArea02_RightAngle_ISig_ "GlareFreeArea02_RightAngle_ISig_4";
BA_ "GenSigCycleTime" SG_ 2432640336 GlareFreeArea02_Distance_ISig_4 100;
BA_ "GenSigCycleTimeActive" SG_ 2432640336 GlareFreeArea02_Distance_ISig_4 100;
BA_ "GenSigStartValue" SG_ 2432640336 GlareFreeArea02_Distance_ISig_4 1023;
BA_ "GenSigMaxLatency" SG_ 2432640336 GlareFreeArea02_Distance_ISig_4 26;
BA_ "Platform_VMCU1_Sig" SG_ 2432640336 GlareFreeArea02_Distance_ISig_4 1;
BA_ "GenSigCycleTime" SG_ 2432639568 GlareFreeArea01_LeftAngle_ISig_4 100;
BA_ "GenSigCycleTimeActive" SG_ 2432639568 GlareFreeArea01_LeftAngle_ISig_4 100;
BA_ "GenSigStartValue" SG_ 2432639568 GlareFreeArea01_LeftAngle_ISig_4 2047;
BA_ "GenSigMaxLatency" SG_ 2432639568 GlareFreeArea01_LeftAngle_ISig_4 25;
BA_ "Platform_VMCU1_Sig" SG_ 2432639568 GlareFreeArea01_LeftAngle_ISig_4 1;
BA_ "GenSigCycleTime" SG_ 2432639568 GlareFreeArea03_Distance_ISig_4 100;
BA_ "GenSigCycleTimeActive" SG_ 2432639568 GlareFreeArea03_Distance_ISig_4 100;
BA_ "GenSigStartValue" SG_ 2432639568 GlareFreeArea03_Distance_ISig_4 1023;
BA_ "GenSigMaxLatency" SG_ 2432639568 GlareFreeArea03_Distance_ISig_4 25;
BA_ "Platform_VMCU1_Sig" SG_ 2432639568 GlareFreeArea03_Distance_ISig_4 1;
BA_ "GenSigCycleTime" SG_ 2432639568 GlareFreeArea03_LeftAngle_ISig_4 100;
BA_ "GenSigCycleTimeActive" SG_ 2432639568 GlareFreeArea03_LeftAngle_ISig_4 100;
BA_ "GenSigStartValue" SG_ 2432639568 GlareFreeArea03_LeftAngle_ISig_4 2047;
BA_ "GenSigMaxLatency" SG_ 2432639568 GlareFreeArea03_LeftAngle_ISig_4 25;
BA_ "Platform_VMCU1_Sig" SG_ 2432639568 GlareFreeArea03_LeftAngle_ISig_4 1;
BA_ "GenSigCycleTime" SG_ 2432639568 GlareFreeArea03_RightAngle_ISig_ 100;
BA_ "GenSigCycleTimeActive" SG_ 2432639568 GlareFreeArea03_RightAngle_ISig_ 100;
BA_ "GenSigStartValue" SG_ 2432639568 GlareFreeArea03_RightAngle_ISig_ 2047;
BA_ "GenSigMaxLatency" SG_ 2432639568 GlareFreeArea03_RightAngle_ISig_ 25;
BA_ "Platform_VMCU1_Sig" SG_ 2432639568 GlareFreeArea03_RightAngle_ISig_ 1;
BA_ "SystemSignalLongSymbol" SG_ 2432639568 GlareFreeArea03_RightAngle_ISig_ "GlareFreeArea03_RightAngle_ISig_4";
BA_ "GenSigCycleTime" SG_ 2432639568 GlareFreeArea01_Distance_ISig_4 100;
BA_ "GenSigCycleTimeActive" SG_ 2432639568 GlareFreeArea01_Distance_ISig_4 100;
BA_ "GenSigStartValue" SG_ 2432639568 GlareFreeArea01_Distance_ISig_4 1023;
BA_ "GenSigMaxLatency" SG_ 2432639568 GlareFreeArea01_Distance_ISig_4 25;
BA_ "Platform_VMCU1_Sig" SG_ 2432639568 GlareFreeArea01_Distance_ISig_4 1;
BA_ "GenSigCycleTime" SG_ 2432639568 GlareFreeArea01_RightAngle_ISig_ 100;
BA_ "GenSigCycleTimeActive" SG_ 2432639568 GlareFreeArea01_RightAngle_ISig_ 100;
BA_ "GenSigStartValue" SG_ 2432639568 GlareFreeArea01_RightAngle_ISig_ 2047;
BA_ "GenSigMaxLatency" SG_ 2432639568 GlareFreeArea01_RightAngle_ISig_ 25;
BA_ "Platform_VMCU1_Sig" SG_ 2432639568 GlareFreeArea01_RightAngle_ISig_ 1;
BA_ "SystemSignalLongSymbol" SG_ 2432639568 GlareFreeArea01_RightAngle_ISig_ "GlareFreeArea01_RightAngle_ISig_4";
BA_ "GenSigCycleTime" SG_ 2499772240 VisionLight_stat 100;
BA_ "GenSigCycleTimeActive" SG_ 2499772240 VisionLight_stat 100;
BA_ "GenSigStartValue" SG_ 2499772240 VisionLight_stat 7;
BA_ "Platform_VMCU1_Sig" SG_ 2499772240 VisionLight_stat 1;
BA_ "GenSigCycleTime" SG_ 2499772240 BBSteeringStatus_ISig_4 100;
BA_ "GenSigCycleTimeActive" SG_ 2499772240 BBSteeringStatus_ISig_4 100;
BA_ "GenSigStartValue" SG_ 2499772240 BBSteeringStatus_ISig_4 3;
BA_ "GenSigCycleTime" SG_ 2499772240 ACCiSeeDistanceGap 100;
BA_ "GenSigCycleTimeActive" SG_ 2499772240 ACCiSeeDistanceGap 100;
BA_ "GenSigStartValue" SG_ 2499772240 ACCiSeeDistanceGap 255;
BA_ "Platform_VMCU1_Sig" SG_ 2499772240 ACCiSeeDistanceGap 1;
BA_ "GenSigCycleTime" SG_ 2466246992 ForwardLookingCameraStatus_ISig_ 100;
BA_ "GenSigCycleTimeActive" SG_ 2466246992 ForwardLookingCameraStatus_ISig_ 100;
BA_ "GenSigStartValue" SG_ 2466246992 ForwardLookingCameraStatus_ISig_ 15;
BA_ "GenSigMaxLatency" SG_ 2466246992 ForwardLookingCameraStatus_ISig_ 40;
BA_ "Platform_VMCU1_Sig" SG_ 2466246992 ForwardLookingCameraStatus_ISig_ 1;
BA_ "SystemSignalLongSymbol" SG_ 2466246992 ForwardLookingCameraStatus_ISig_ "ForwardLookingCameraStatus_ISig_4";
BA_ "GenSigCycleTime" SG_ 2466246992 XARDACU_ControlMode 100;
BA_ "GenSigCycleTimeActive" SG_ 2466246992 XARDACU_ControlMode 100;
BA_ "GenSigStartValue" SG_ 2466246992 XARDACU_ControlMode 3;
BA_ "GenSigMaxLatency" SG_ 2466246992 XARDACU_ControlMode 50;
BA_ "Platform_VMCU1_Sig" SG_ 2466246992 XARDACU_ControlMode 1;
BA_ "SeToolAncestorID_SIGNAL" SG_ 2466246992 XARDACU_ControlMode "x0000001D0425403E";
BA_ "SeToolItemID_SIGNAL" SG_ 2466246992 XARDACU_ControlMode "x0000001D0425403E";
BA_ "SeToolName_SIGNAL" SG_ 2466246992 XARDACU_ControlMode "ControlMode";
BA_ "SeToolOwnerSigGroupID_SIGNAL" SG_ 2466246992 XARDACU_ControlMode "x0000001D043FB722";
BA_ "SeToolOwnerSigGroup_SIGNAL" SG_ 2466246992 XARDACU_ControlMode "XARDACU";
BA_ "SeToolVersion_SIGNAL" SG_ 2466246992 XARDACU_ControlMode "1";
BA_ "GenSigCycleTime" SG_ 2466246992 ACCiRollInhibit 100;
BA_ "GenSigCycleTimeActive" SG_ 2466246992 ACCiRollInhibit 100;
BA_ "GenSigStartValue" SG_ 2466246992 ACCiRollInhibit 3;
BA_ "Platform_VMCU1_Sig" SG_ 2466246992 ACCiRollInhibit 1;
BA_ "GenSigCycleTime" SG_ 2466246992 ACCTargetRelLongSpeed 100;
BA_ "GenSigCycleTimeActive" SG_ 2466246992 ACCTargetRelLongSpeed 100;
BA_ "GenSigStartValue" SG_ 2466246992 ACCTargetRelLongSpeed 255;
BA_ "Platform_VMCU1_Sig" SG_ 2466246992 ACCTargetRelLongSpeed 1;
BA_ "GenSigCycleTime" SG_ 2466246992 CMReducedAbilityStatus_ISig_4 100;
BA_ "GenSigCycleTimeActive" SG_ 2466246992 CMReducedAbilityStatus_ISig_4 100;
BA_ "GenSigStartValue" SG_ 2466246992 CMReducedAbilityStatus_ISig_4 7;
BA_ "Platform_VMCU1_Sig" SG_ 2466246992 CMReducedAbilityStatus_ISig_4 1;
BA_ "GenSigCycleTime" SG_ 2466246992 LPOSBlocked_ISig_4 100;
BA_ "GenSigCycleTimeActive" SG_ 2466246992 LPOSBlocked_ISig_4 100;
BA_ "GenSigStartValue" SG_ 2466246992 LPOSBlocked_ISig_4 3;
BA_ "Platform_VMCU1_Sig" SG_ 2466246992 LPOSBlocked_ISig_4 1;
BA_ "GenSigCycleTime" SG_ 2466246992 CollisionSituationAliveAck 100;
BA_ "GenSigCycleTimeActive" SG_ 2466246992 CollisionSituationAliveAck 100;
BA_ "GenSigStartValue" SG_ 2466246992 CollisionSituationAliveAck 15;
BA_ "Platform_VMCU1_Sig" SG_ 2466246992 CollisionSituationAliveAck 1;
BA_ "GenSigCycleTime" SG_ 2466246992 ForwardLookingRadarStatus_ISig_4 100;
BA_ "GenSigCycleTimeActive" SG_ 2466246992 ForwardLookingRadarStatus_ISig_4 100;
BA_ "GenSigStartValue" SG_ 2466246992 ForwardLookingRadarStatus_ISig_4 15;
BA_ "GenSigMaxLatency" SG_ 2466246992 ForwardLookingRadarStatus_ISig_4 40;
BA_ "Platform_VMCU1_Sig" SG_ 2466246992 ForwardLookingRadarStatus_ISig_4 1;
BA_ "GenSigCycleTime" SG_ 2466246992 XPRRequest_CM_ISig_4 100;
BA_ "GenSigCycleTimeActive" SG_ 2466246992 XPRRequest_CM_ISig_4 100;
BA_ "GenSigStartValue" SG_ 2466246992 XPRRequest_CM_ISig_4 255;
BA_ "Platform_VMCU1_Sig" SG_ 2466246992 XPRRequest_CM_ISig_4 1;
BA_ "GenSigCycleTime" SG_ 2466246992 XARDACU_AccelDemand 100;
BA_ "GenSigCycleTimeActive" SG_ 2466246992 XARDACU_AccelDemand 100;
BA_ "GenSigStartValue" SG_ 2466246992 XARDACU_AccelDemand 65535;
BA_ "GenSigMaxLatency" SG_ 2466246992 XARDACU_AccelDemand 50;
BA_ "Platform_VMCU1_Sig" SG_ 2466246992 XARDACU_AccelDemand 1;
BA_ "SeToolAncestorID_SIGNAL" SG_ 2466246992 XARDACU_AccelDemand "x0000001D04254042";
BA_ "SeToolItemID_SIGNAL" SG_ 2466246992 XARDACU_AccelDemand "x0000001D04254042";
BA_ "SeToolName_SIGNAL" SG_ 2466246992 XARDACU_AccelDemand "AccelDemand";
BA_ "SeToolOwnerSigGroupID_SIGNAL" SG_ 2466246992 XARDACU_AccelDemand "x0000001D043FB722";
BA_ "SeToolOwnerSigGroup_SIGNAL" SG_ 2466246992 XARDACU_AccelDemand "XARDACU";
BA_ "SeToolVersion_SIGNAL" SG_ 2466246992 XARDACU_AccelDemand "1";
BA_ "GenSigCycleTime" SG_ 2466246992 CollSituationHazardLightReq 100;
BA_ "GenSigCycleTimeActive" SG_ 2466246992 CollSituationHazardLightReq 100;
BA_ "GenSigStartValue" SG_ 2466246992 CollSituationHazardLightReq 7;
BA_ "Platform_VMCU1_Sig" SG_ 2466246992 CollSituationHazardLightReq 1;
BA_ "GenSigCycleTime" SG_ 2432690512 PathDeviationDriverAlert_ISig_4 100;
BA_ "GenSigCycleTimeActive" SG_ 2432690512 PathDeviationDriverAlert_ISig_4 100;
BA_ "GenSigStartValue" SG_ 2432690512 PathDeviationDriverAlert_ISig_4 7;
BA_ "GenSigMaxLatency" SG_ 2432690512 PathDeviationDriverAlert_ISig_4 48;
BA_ "Platform_VMCU1_Sig" SG_ 2432690512 PathDeviationDriverAlert_ISig_4 1;
BA_ "SeToolAncestorID_SIGNAL" SG_ 2432690512 PathDeviationDriverAlert_ISig_4 "x0000001D04168B9E";
BA_ "SeToolItemID_SIGNAL" SG_ 2432690512 PathDeviationDriverAlert_ISig_4 "x0000001D043EF492";
BA_ "SeToolName_SIGNAL" SG_ 2432690512 PathDeviationDriverAlert_ISig_4 "LKSDepartureWarningStatus";
BA_ "SeToolVersion_SIGNAL" SG_ 2432690512 PathDeviationDriverAlert_ISig_4 "2";
BA_ "GenSigCycleTime" SG_ 2432690512 CM_DisengageDrivelineRequest 100;
BA_ "GenSigCycleTimeActive" SG_ 2432690512 CM_DisengageDrivelineRequest 100;
BA_ "GenSigStartValue" SG_ 2432690512 CM_DisengageDrivelineRequest 3;
BA_ "GenSigMaxLatency" SG_ 2432690512 CM_DisengageDrivelineRequest 48;
BA_ "Platform_VMCU1_Sig" SG_ 2432690512 CM_DisengageDrivelineRequest 1;
BA_ "SeToolAncestorID_SIGNAL" SG_ 2432690512 CM_DisengageDrivelineRequest "x0000001D0417E893";
BA_ "SeToolItemID_SIGNAL" SG_ 2432690512 CM_DisengageDrivelineRequest "x0000001D0435A0FF";
BA_ "SeToolName_SIGNAL" SG_ 2432690512 CM_DisengageDrivelineRequest "CM_DisengageDrivelineRequest";
BA_ "SeToolVersion_SIGNAL" SG_ 2432690512 CM_DisengageDrivelineRequest "2";
BA_ "GenSigCycleTime" SG_ 2432690512 ACCBrakeRequestStatus 100;
BA_ "GenSigCycleTimeActive" SG_ 2432690512 ACCBrakeRequestStatus 100;
BA_ "GenSigStartValue" SG_ 2432690512 ACCBrakeRequestStatus 3;
BA_ "GenSigMaxLatency" SG_ 2432690512 ACCBrakeRequestStatus 48;
BA_ "Platform_VMCU1_Sig" SG_ 2432690512 ACCBrakeRequestStatus 1;
BA_ "GenSigCycleTime" SG_ 2432690512 FrontalCollisionDriverAlert_ISig 100;
BA_ "GenSigCycleTimeActive" SG_ 2432690512 FrontalCollisionDriverAlert_ISig 100;
BA_ "GenSigStartValue" SG_ 2432690512 FrontalCollisionDriverAlert_ISig 7;
BA_ "GenSigMaxLatency" SG_ 2432690512 FrontalCollisionDriverAlert_ISig 48;
BA_ "Platform_VMCU1_Sig" SG_ 2432690512 FrontalCollisionDriverAlert_ISig 1;
BA_ "SeToolAncestorID_SIGNAL" SG_ 2432690512 FrontalCollisionDriverAlert_ISig "x0000001D0416642E";
BA_ "SeToolItemID_SIGNAL" SG_ 2432690512 FrontalCollisionDriverAlert_ISig "x0000001D0428BE70";
BA_ "SeToolName_SIGNAL" SG_ 2432690512 FrontalCollisionDriverAlert_ISig "FCW_Warning";
BA_ "SeToolVersion_SIGNAL" SG_ 2432690512 FrontalCollisionDriverAlert_ISig "2";
BA_ "SystemSignalLongSymbol" SG_ 2432690512 FrontalCollisionDriverAlert_ISig "FrontalCollisionDriverAlert_ISig_4";
BA_ "GenSigCycleTime" SG_ 2432690512 ACCBrakeCapacityWarning_ISig_4 100;
BA_ "GenSigCycleTimeActive" SG_ 2432690512 ACCBrakeCapacityWarning_ISig_4 100;
BA_ "GenSigStartValue" SG_ 2432690512 ACCBrakeCapacityWarning_ISig_4 3;
BA_ "GenSigMaxLatency" SG_ 2432690512 ACCBrakeCapacityWarning_ISig_4 48;
BA_ "Platform_VMCU1_Sig" SG_ 2432690512 ACCBrakeCapacityWarning_ISig_4 1;
BA_ "SeToolAncestorID_SIGNAL" SG_ 2432690512 ACCBrakeCapacityWarning_ISig_4 "x0000001D041471DD";
BA_ "SeToolItemID_SIGNAL" SG_ 2432690512 ACCBrakeCapacityWarning_ISig_4 "x0000001D041471DD";
BA_ "SeToolName_SIGNAL" SG_ 2432690512 ACCBrakeCapacityWarning_ISig_4 "ACCBrakeCapacityWarning";
BA_ "SeToolVersion_SIGNAL" SG_ 2432690512 ACCBrakeCapacityWarning_ISig_4 "1";
BA_ "GenSigCycleTime" SG_ 2432690512 ACC_SGOFaultCondStat_SeatBelt_IS 100;
BA_ "GenSigCycleTimeActive" SG_ 2432690512 ACC_SGOFaultCondStat_SeatBelt_IS 100;
BA_ "Platform_VMCU1_Sig" SG_ 2432690512 ACC_SGOFaultCondStat_SeatBelt_IS 1;
BA_ "SystemSignalLongSymbol" SG_ 2432690512 ACC_SGOFaultCondStat_SeatBelt_IS "ACC_SGOFaultCondStat_SeatBelt_ISig_4";
BA_ "GenSigCycleTime" SG_ 2432690512 CM_Status_ISig_4 100;
BA_ "GenSigCycleTimeActive" SG_ 2432690512 CM_Status_ISig_4 100;
BA_ "GenSigStartValue" SG_ 2432690512 CM_Status_ISig_4 7;
BA_ "GenSigMaxLatency" SG_ 2432690512 CM_Status_ISig_4 48;
BA_ "Platform_VMCU1_Sig" SG_ 2432690512 CM_Status_ISig_4 1;
BA_ "SeToolAncestorID_SIGNAL" SG_ 2432690512 CM_Status_ISig_4 "x0000001D0417D4DA";
BA_ "SeToolItemID_SIGNAL" SG_ 2432690512 CM_Status_ISig_4 "x0000001D0428BE35";
BA_ "SeToolName_SIGNAL" SG_ 2432690512 CM_Status_ISig_4 "CM_Status";
BA_ "SeToolVersion_SIGNAL" SG_ 2432690512 CM_Status_ISig_4 "2";
BA_ "GenSigCycleTime" SG_ 2432690512 DASApplicationStatus_ISig_4 100;
BA_ "GenSigCycleTimeActive" SG_ 2432690512 DASApplicationStatus_ISig_4 100;
BA_ "GenSigStartValue" SG_ 2432690512 DASApplicationStatus_ISig_4 7;
BA_ "GenSigMaxLatency" SG_ 2432690512 DASApplicationStatus_ISig_4 48;
BA_ "Platform_VMCU1_Sig" SG_ 2432690512 DASApplicationStatus_ISig_4 1;
BA_ "SeToolAncestorID_SIGNAL" SG_ 2432690512 DASApplicationStatus_ISig_4 "x0000001D04169A83";
BA_ "SeToolItemID_SIGNAL" SG_ 2432690512 DASApplicationStatus_ISig_4 "x0000001D04253A46";
BA_ "SeToolName_SIGNAL" SG_ 2432690512 DASApplicationStatus_ISig_4 "DASSystemStatus";
BA_ "SeToolVersion_SIGNAL" SG_ 2432690512 DASApplicationStatus_ISig_4 "2";
BA_ "GenSigCycleTime" SG_ 2432690512 ACC_Status_ISig_4 100;
BA_ "GenSigCycleTimeActive" SG_ 2432690512 ACC_Status_ISig_4 100;
BA_ "GenSigStartValue" SG_ 2432690512 ACC_Status_ISig_4 7;
BA_ "GenSigMaxLatency" SG_ 2432690512 ACC_Status_ISig_4 48;
BA_ "Platform_VMCU1_Sig" SG_ 2432690512 ACC_Status_ISig_4 1;
BA_ "SeToolAncestorID_SIGNAL" SG_ 2432690512 ACC_Status_ISig_4 "x0000001D041F8BDE";
BA_ "SeToolItemID_SIGNAL" SG_ 2432690512 ACC_Status_ISig_4 "x0000001D0427537B";
BA_ "SeToolName_SIGNAL" SG_ 2432690512 ACC_Status_ISig_4 "ACC_Status";
BA_ "SeToolVersion_SIGNAL" SG_ 2432690512 ACC_Status_ISig_4 "2";
BA_ "GenSigCycleTime" SG_ 2432690512 LKSApplicationStatus_ISig_4 100;
BA_ "GenSigCycleTimeActive" SG_ 2432690512 LKSApplicationStatus_ISig_4 100;
BA_ "GenSigStartValue" SG_ 2432690512 LKSApplicationStatus_ISig_4 7;
BA_ "GenSigMaxLatency" SG_ 2432690512 LKSApplicationStatus_ISig_4 48;
BA_ "Platform_VMCU1_Sig" SG_ 2432690512 LKSApplicationStatus_ISig_4 1;
BA_ "SeToolAncestorID_SIGNAL" SG_ 2432690512 LKSApplicationStatus_ISig_4 "x0000001D04168BAE";
BA_ "SeToolItemID_SIGNAL" SG_ 2432690512 LKSApplicationStatus_ISig_4 "x0000001D043BCC5C";
BA_ "SeToolName_SIGNAL" SG_ 2432690512 LKSApplicationStatus_ISig_4 "LKSStatus";
BA_ "SeToolVersion_SIGNAL" SG_ 2432690512 LKSApplicationStatus_ISig_4 "3";
BA_ "GenSigCycleTime" SG_ 2432690512 LCSSystemStatus 100;
BA_ "GenSigCycleTimeActive" SG_ 2432690512 LCSSystemStatus 100;
BA_ "GenSigStartValue" SG_ 2432690512 LCSSystemStatus 7;
BA_ "GenSigMaxLatency" SG_ 2432690512 LCSSystemStatus 48;
BA_ "Platform_VMCU1_Sig" SG_ 2432690512 LCSSystemStatus 1;
BA_ "SeToolAncestorID_SIGNAL" SG_ 2432690512 LCSSystemStatus "x0000001D043A89E4";
BA_ "SeToolItemID_SIGNAL" SG_ 2432690512 LCSSystemStatus "x0000001D043A89E4";
BA_ "SeToolName_SIGNAL" SG_ 2432690512 LCSSystemStatus "LCSSystemStatus";
BA_ "SeToolVersion_SIGNAL" SG_ 2432690512 LCSSystemStatus "1";
BA_ "GenSigCycleTime" SG_ 2432690512 ACC_SGOFaultCondStat_SigStat_ISi 100;
BA_ "GenSigCycleTimeActive" SG_ 2432690512 ACC_SGOFaultCondStat_SigStat_ISi 100;
BA_ "Platform_VMCU1_Sig" SG_ 2432690512 ACC_SGOFaultCondStat_SigStat_ISi 1;
BA_ "SystemSignalLongSymbol" SG_ 2432690512 ACC_SGOFaultCondStat_SigStat_ISi "ACC_SGOFaultCondStat_SigStat_ISig_4";
BA_ "GenSigCycleTime" SG_ 2432690512 ACC_SGOFaultCondStat_Target_ISig 100;
BA_ "GenSigCycleTimeActive" SG_ 2432690512 ACC_SGOFaultCondStat_Target_ISig 100;
BA_ "Platform_VMCU1_Sig" SG_ 2432690512 ACC_SGOFaultCondStat_Target_ISig 1;
BA_ "SystemSignalLongSymbol" SG_ 2432690512 ACC_SGOFaultCondStat_Target_ISig "ACC_SGOFaultCondStat_Target_ISig_4";
BA_ "GenSigCycleTime" SG_ 2432690512 FCW_Status_ISig_4 100;
BA_ "GenSigCycleTimeActive" SG_ 2432690512 FCW_Status_ISig_4 100;
BA_ "GenSigStartValue" SG_ 2432690512 FCW_Status_ISig_4 3;
BA_ "GenSigMaxLatency" SG_ 2432690512 FCW_Status_ISig_4 48;
BA_ "Platform_VMCU1_Sig" SG_ 2432690512 FCW_Status_ISig_4 1;
BA_ "SeToolAncestorID_SIGNAL" SG_ 2432690512 FCW_Status_ISig_4 "x0000001D04166451";
BA_ "SeToolItemID_SIGNAL" SG_ 2432690512 FCW_Status_ISig_4 "x0000001D04166451";
BA_ "SeToolName_SIGNAL" SG_ 2432690512 FCW_Status_ISig_4 "FCW_Status";
BA_ "SeToolVersion_SIGNAL" SG_ 2432690512 FCW_Status_ISig_4 "1";
BA_ "GenSigCycleTime" SG_ 2432690512 DriverImpairedDriverAlert_ISig_4 100;
BA_ "GenSigCycleTimeActive" SG_ 2432690512 DriverImpairedDriverAlert_ISig_4 100;
BA_ "GenSigStartValue" SG_ 2432690512 DriverImpairedDriverAlert_ISig_4 7;
BA_ "GenSigMaxLatency" SG_ 2432690512 DriverImpairedDriverAlert_ISig_4 48;
BA_ "Platform_VMCU1_Sig" SG_ 2432690512 DriverImpairedDriverAlert_ISig_4 1;
BA_ "SeToolAncestorID_SIGNAL" SG_ 2432690512 DriverImpairedDriverAlert_ISig_4 "x0000001D04169AB3";
BA_ "SeToolItemID_SIGNAL" SG_ 2432690512 DriverImpairedDriverAlert_ISig_4 "x0000001D04169AB3";
BA_ "SeToolName_SIGNAL" SG_ 2432690512 DriverImpairedDriverAlert_ISig_4 "DASImpairmentWarningStatus";
BA_ "SeToolVersion_SIGNAL" SG_ 2432690512 DriverImpairedDriverAlert_ISig_4 "1";
BA_ "GenSigCycleTime" SG_ 2432690512 DriverVigilanceLevel_ISig_4 100;
BA_ "GenSigCycleTimeActive" SG_ 2432690512 DriverVigilanceLevel_ISig_4 100;
BA_ "GenSigStartValue" SG_ 2432690512 DriverVigilanceLevel_ISig_4 7;
BA_ "GenSigMaxLatency" SG_ 2432690512 DriverVigilanceLevel_ISig_4 48;
BA_ "Platform_VMCU1_Sig" SG_ 2432690512 DriverVigilanceLevel_ISig_4 1;
BA_ "SeToolAncestorID_SIGNAL" SG_ 2432690512 DriverVigilanceLevel_ISig_4 "x0000001D04169ABA";
BA_ "SeToolItemID_SIGNAL" SG_ 2432690512 DriverVigilanceLevel_ISig_4 "x0000001D043EBF2F";
BA_ "SeToolName_SIGNAL" SG_ 2432690512 DriverVigilanceLevel_ISig_4 "DASVigilanceLevelStatus";
BA_ "SeToolVersion_SIGNAL" SG_ 2432690512 DriverVigilanceLevel_ISig_4 "2";
BA_ "GenSigCycleTime" SG_ 2432690512 ACCForwardVehicleSpeed_ISig_4 100;
BA_ "GenSigCycleTimeActive" SG_ 2432690512 ACCForwardVehicleSpeed_ISig_4 100;
BA_ "GenSigStartValue" SG_ 2432690512 ACCForwardVehicleSpeed_ISig_4 255;
BA_ "GenSigMaxLatency" SG_ 2432690512 ACCForwardVehicleSpeed_ISig_4 48;
BA_ "Platform_VMCU1_Sig" SG_ 2432690512 ACCForwardVehicleSpeed_ISig_4 1;
BA_ "SeToolAncestorID_SIGNAL" SG_ 2432690512 ACCForwardVehicleSpeed_ISig_4 "x0000001D04147192";
BA_ "SeToolItemID_SIGNAL" SG_ 2432690512 ACCForwardVehicleSpeed_ISig_4 "x0000001D04147192";
BA_ "SeToolName_SIGNAL" SG_ 2432690512 ACCForwardVehicleSpeed_ISig_4 "ACCForwardVehicleSpeed";
BA_ "SeToolVersion_SIGNAL" SG_ 2432690512 ACCForwardVehicleSpeed_ISig_4 "1";
BA_ "GenSigCycleTime" SG_ 2432690512 ACC_SGOFaultCondStat_Door_ISig_4 100;
BA_ "GenSigCycleTimeActive" SG_ 2432690512 ACC_SGOFaultCondStat_Door_ISig_4 100;
BA_ "Platform_VMCU1_Sig" SG_ 2432690512 ACC_SGOFaultCondStat_Door_ISig_4 1;
BA_ "GenSigCycleTime" SG_ 2432690512 ACCTargetDetected_ISig_4 100;
BA_ "GenSigCycleTimeActive" SG_ 2432690512 ACCTargetDetected_ISig_4 100;
BA_ "GenSigStartValue" SG_ 2432690512 ACCTargetDetected_ISig_4 3;
BA_ "GenSigMaxLatency" SG_ 2432690512 ACCTargetDetected_ISig_4 48;
BA_ "Platform_VMCU1_Sig" SG_ 2432690512 ACCTargetDetected_ISig_4 1;
BA_ "SeToolAncestorID_SIGNAL" SG_ 2432690512 ACCTargetDetected_ISig_4 "x0000001D04146FC9";
BA_ "SeToolItemID_SIGNAL" SG_ 2432690512 ACCTargetDetected_ISig_4 "x0000001D04146FC9";
BA_ "SeToolName_SIGNAL" SG_ 2432690512 ACCTargetDetected_ISig_4 "ACCTargetDetected";
BA_ "SeToolVersion_SIGNAL" SG_ 2432690512 ACCTargetDetected_ISig_4 "1";
BA_ "GenSigCycleTime" SG_ 2432690512 ACCForwardVehicleDistance_ISig_4 100;
BA_ "GenSigCycleTimeActive" SG_ 2432690512 ACCForwardVehicleDistance_ISig_4 100;
BA_ "GenSigStartValue" SG_ 2432690512 ACCForwardVehicleDistance_ISig_4 255;
BA_ "GenSigMaxLatency" SG_ 2432690512 ACCForwardVehicleDistance_ISig_4 48;
BA_ "Platform_VMCU1_Sig" SG_ 2432690512 ACCForwardVehicleDistance_ISig_4 1;
BA_ "SeToolAncestorID_SIGNAL" SG_ 2432690512 ACCForwardVehicleDistance_ISig_4 "x0000001D04147189";
BA_ "SeToolItemID_SIGNAL" SG_ 2432690512 ACCForwardVehicleDistance_ISig_4 "x0000001D04147189";
BA_ "SeToolName_SIGNAL" SG_ 2432690512 ACCForwardVehicleDistance_ISig_4 "ACCForwardVehicleDistance";
BA_ "SeToolVersion_SIGNAL" SG_ 2432690512 ACCForwardVehicleDistance_ISig_4 "1";
BA_ "GenSigCycleTime" SG_ 2432690512 LKSCorrectiveSteeringStatus 100;
BA_ "GenSigCycleTimeActive" SG_ 2432690512 LKSCorrectiveSteeringStatus 100;
BA_ "GenSigStartValue" SG_ 2432690512 LKSCorrectiveSteeringStatus 7;
BA_ "GenSigMaxLatency" SG_ 2432690512 LKSCorrectiveSteeringStatus 48;
BA_ "GenSigCycleTime" SG_ 2432690512 ACC_SGOFaultCondStat_Other_ISig_ 100;
BA_ "GenSigCycleTimeActive" SG_ 2432690512 ACC_SGOFaultCondStat_Other_ISig_ 100;
BA_ "Platform_VMCU1_Sig" SG_ 2432690512 ACC_SGOFaultCondStat_Other_ISig_ 1;
BA_ "SystemSignalLongSymbol" SG_ 2432690512 ACC_SGOFaultCondStat_Other_ISig_ "ACC_SGOFaultCondStat_Other_ISig_4";
BA_ "GenSigCycleTime" SG_ 2432690512 LCSSoundSettingStatus 100;
BA_ "GenSigCycleTimeActive" SG_ 2432690512 LCSSoundSettingStatus 100;
BA_ "GenSigStartValue" SG_ 2432690512 LCSSoundSettingStatus 3;
BA_ "Platform_VMCU1_Sig" SG_ 2432690512 LCSSoundSettingStatus 1;
BA_ "GenSigCycleTime" SG_ 2432690512 ACC_SGOFaultCondStat_Speed_ISig_ 100;
BA_ "GenSigCycleTimeActive" SG_ 2432690512 ACC_SGOFaultCondStat_Speed_ISig_ 100;
BA_ "Platform_VMCU1_Sig" SG_ 2432690512 ACC_SGOFaultCondStat_Speed_ISig_ 1;
BA_ "SystemSignalLongSymbol" SG_ 2432690512 ACC_SGOFaultCondStat_Speed_ISig_ "ACC_SGOFaultCondStat_Speed_ISig_4";
BA_ "GenSigSendType" SG_ 2499750528 CIOM_BB2_30S_FCS 7;
BA_ "GenSigSendType" SG_ 2499750527 EncryptedGBUnlockAuth_stat 1;
BA_ "GenSigMaxLatency" SG_ 2499750527 EncryptedGBUnlockAuth_stat 100;
BA_ "GenSigCycleTime" SG_ 2432685120 LKSCSEnableSwitch_rqst 100;
BA_ "GenSigCycleTimeActive" SG_ 2432685120 LKSCSEnableSwitch_rqst 100;
BA_ "GenSigStartValue" SG_ 2432685120 LKSCSEnableSwitch_rqst 3;
BA_ "GenSigMaxLatency" SG_ 2432685120 LKSCSEnableSwitch_rqst 48;
BA_ "GenSigCycleTime" SG_ 2566078272 RollerBenchModeRequest_2 100;
BA_ "GenSigCycleTimeActive" SG_ 2566078272 RollerBenchModeRequest_2 100;
BA_ "GenSigStartValue" SG_ 2566078272 RollerBenchModeRequest_2 3;
BA_ "GenSigMaxLatency" SG_ 2566078272 RollerBenchModeRequest_2 101;
BA_ "Platform_VMCU1_Sig" SG_ 2566078272 RollerBenchModeRequest_2 1;
BA_ "GenSigCycleTime" SG_ 2566078272 TrafficAccidentHazardLightRqst_I 100;
BA_ "GenSigCycleTimeActive" SG_ 2566078272 TrafficAccidentHazardLightRqst_I 100;
BA_ "GenSigStartValue" SG_ 2566078272 TrafficAccidentHazardLightRqst_I 3;
BA_ "SystemSignalLongSymbol" SG_ 2566078272 TrafficAccidentHazardLightRqst_I "TrafficAccidentHazardLightRqst_ISig_4";
BA_ "GenSigCycleTime" SG_ 2566078272 GearboxUnlockAuth_stat 100;
BA_ "GenSigCycleTimeActive" SG_ 2566078272 GearboxUnlockAuth_stat 100;
BA_ "GenSigStartValue" SG_ 2566078272 GearboxUnlockAuth_stat 7;
BA_ "GenSigCycleTime" SG_ 2566078272 InhibRegeneration_ButtonStat 100;
BA_ "GenSigCycleTimeActive" SG_ 2566078272 InhibRegeneration_ButtonStat 100;
BA_ "GenSigStartValue" SG_ 2566078272 InhibRegeneration_ButtonStat 3;
BA_ "GenSigMaxLatency" SG_ 2566078272 InhibRegeneration_ButtonStat 101;
BA_ "Platform_VMCU1_Sig" SG_ 2566078272 InhibRegeneration_ButtonStat 1;
BA_ "GenSigSendType" SG_ 2490646336 MediaSourcesListReq_SInfo_ISig_4 1;
BA_ "GenSigStartValue" SG_ 2490646336 MediaSourcesListReq_SInfo_ISig_4 3;
BA_ "GenSigMaxLatency" SG_ 2490646336 MediaSourcesListReq_SInfo_ISig_4 50;
BA_ "NeedsUpdateBit" SG_ 2490646336 MediaSourcesListReq_SInfo_ISig_4 1;
BA_ "Platform_VMCU1_Sig" SG_ 2490646336 MediaSourcesListReq_SInfo_ISig_4 1;
BA_ "GenSigSendType" SG_ 2490646336 MediaSourcesListReq_Items_ISig_4 1;
BA_ "GenSigMaxLatency" SG_ 2490646336 MediaSourcesListReq_Items_ISig_4 50;
BA_ "NeedsUpdateBit" SG_ 2490646336 MediaSourcesListReq_Items_ISig_4 1;
BA_ "Platform_VMCU1_Sig" SG_ 2490646336 MediaSourcesListReq_Items_ISig_4 1;
BA_ "GenSigSendType" SG_ 2490646336 MediaSourcesListReq_sg_UB_ISig_4 7;
BA_ "Platform_VMCU1_Sig" SG_ 2490646336 MediaSourcesListReq_sg_UB_ISig_4 1;
BA_ "GenSigSendType" SG_ 2490646336 MediaSourcesListReq_ItemID_ISig_ 1;
BA_ "GenSigMaxLatency" SG_ 2490646336 MediaSourcesListReq_ItemID_ISig_ 50;
BA_ "NeedsUpdateBit" SG_ 2490646336 MediaSourcesListReq_ItemID_ISig_ 1;
BA_ "Platform_VMCU1_Sig" SG_ 2490646336 MediaSourcesListReq_ItemID_ISig_ 1;
BA_ "SystemSignalLongSymbol" SG_ 2490646336 MediaSourcesListReq_ItemID_ISig_ "MediaSourcesListReq_ItemID_ISig_4";
BA_ "GenSigSendType" SG_ 2499780850 AlmClkSetAlm_LECM_rq_Type_ISig_4 1;
BA_ "GenSigStartValue" SG_ 2499780850 AlmClkSetAlm_LECM_rq_Type_ISig_4 7;
BA_ "GenSigMaxLatency" SG_ 2499780850 AlmClkSetAlm_LECM_rq_Type_ISig_4 126;
BA_ "Platform_VMCU1_Sig" SG_ 2499780850 AlmClkSetAlm_LECM_rq_Type_ISig_4 1;
BA_ "GenSigSendType" SG_ 2499780850 AlmClkSetAlm_LECM_rq_ID_ISig_4 1;
BA_ "GenSigStartValue" SG_ 2499780850 AlmClkSetAlm_LECM_rq_ID_ISig_4 127;
BA_ "GenSigMaxLatency" SG_ 2499780850 AlmClkSetAlm_LECM_rq_ID_ISig_4 126;
BA_ "Platform_VMCU1_Sig" SG_ 2499780850 AlmClkSetAlm_LECM_rq_ID_ISig_4 1;
BA_ "GenSigSendType" SG_ 2499780850 AlmClkSetAlm_LECM_rq_SetHr_ISig_ 1;
BA_ "GenSigStartValue" SG_ 2499780850 AlmClkSetAlm_LECM_rq_SetHr_ISig_ 31;
BA_ "GenSigMaxLatency" SG_ 2499780850 AlmClkSetAlm_LECM_rq_SetHr_ISig_ 126;
BA_ "Platform_VMCU1_Sig" SG_ 2499780850 AlmClkSetAlm_LECM_rq_SetHr_ISig_ 1;
BA_ "SystemSignalLongSymbol" SG_ 2499780850 AlmClkSetAlm_LECM_rq_SetHr_ISig_ "AlmClkSetAlm_LECM_rq_SetHr_ISig_4";
BA_ "GenSigSendType" SG_ 2499780850 AlmClkSetAlm_LECM_rq_Stat_ISig_4 1;
BA_ "GenSigMaxLatency" SG_ 2499780850 AlmClkSetAlm_LECM_rq_Stat_ISig_4 126;
BA_ "Platform_VMCU1_Sig" SG_ 2499780850 AlmClkSetAlm_LECM_rq_Stat_ISig_4 1;
BA_ "GenSigSendType" SG_ 2499780850 AlmClkSetAlm_LECM_rq_SetMin_ISig 1;
BA_ "GenSigStartValue" SG_ 2499780850 AlmClkSetAlm_LECM_rq_SetMin_ISig 63;
BA_ "GenSigMaxLatency" SG_ 2499780850 AlmClkSetAlm_LECM_rq_SetMin_ISig 126;
BA_ "Platform_VMCU1_Sig" SG_ 2499780850 AlmClkSetAlm_LECM_rq_SetMin_ISig 1;
BA_ "SystemSignalLongSymbol" SG_ 2499780850 AlmClkSetAlm_LECM_rq_SetMin_ISig "AlmClkSetAlm_LECM_rq_SetMin_ISig_4";
BA_ "GenSigSendType" SG_ 2499780850 AlmClkSetAlm_LECM_rq_DaySet_ISig 1;
BA_ "GenSigMaxLatency" SG_ 2499780850 AlmClkSetAlm_LECM_rq_DaySet_ISig 126;
BA_ "Platform_VMCU1_Sig" SG_ 2499780850 AlmClkSetAlm_LECM_rq_DaySet_ISig 1;
BA_ "SystemSignalLongSymbol" SG_ 2499780850 AlmClkSetAlm_LECM_rq_DaySet_ISig "AlmClkSetAlm_LECM_rq_DaySet_ISig_4";
BA_ "GenSigSendType" SG_ 2499780850 AlmClkSetAlm_LECM_rq_Mode_ISig_4 1;
BA_ "GenSigMaxLatency" SG_ 2499780850 AlmClkSetAlm_LECM_rq_Mode_ISig_4 126;
BA_ "Platform_VMCU1_Sig" SG_ 2499780850 AlmClkSetAlm_LECM_rq_Mode_ISig_4 1;
BA_ "GenSigSendType" SG_ 2482978624 TipperTailGateRequest_UB_ISig_4 7;
BA_ "Platform_VMCU1_Sig" SG_ 2482978624 TipperTailGateRequest_UB_ISig_4 1;
BA_ "GenSigSendType" SG_ 2482978624 LoadDistributionRequested_UB_ISi 7;
BA_ "Platform_VMCU1_Sig" SG_ 2482978624 LoadDistributionRequested_UB_ISi 1;
BA_ "SystemSignalLongSymbol" SG_ 2482978624 LoadDistributionRequested_UB_ISi "LoadDistributionRequested_UB_ISig_4";
BA_ "GenSigCycleTime" SG_ 2482978624 TipperUpDownRequest_ISig_4 100;
BA_ "GenSigCycleTimeActive" SG_ 2482978624 TipperUpDownRequest_ISig_4 100;
BA_ "GenSigStartValue" SG_ 2482978624 TipperUpDownRequest_ISig_4 7;
BA_ "GenSigMaxLatency" SG_ 2482978624 TipperUpDownRequest_ISig_4 75;
BA_ "NeedsUpdateBit" SG_ 2482978624 TipperUpDownRequest_ISig_4 1;
BA_ "Platform_VMCU1_Sig" SG_ 2482978624 TipperUpDownRequest_ISig_4 1;
BA_ "GenSigSendType" SG_ 2482978624 TipperTarpaulinRequest_UB_ISig_4 7;
BA_ "Platform_VMCU1_Sig" SG_ 2482978624 TipperTarpaulinRequest_UB_ISig_4 1;
BA_ "GenSigCycleTime" SG_ 2482978624 LoadDistributionRequested_ISig_4 100;
BA_ "GenSigCycleTimeActive" SG_ 2482978624 LoadDistributionRequested_ISig_4 100;
BA_ "GenSigStartValue" SG_ 2482978624 LoadDistributionRequested_ISig_4 15;
BA_ "NeedsUpdateBit" SG_ 2482978624 LoadDistributionRequested_ISig_4 1;
BA_ "Platform_VMCU1_Sig" SG_ 2482978624 LoadDistributionRequested_ISig_4 1;
BA_ "GenSigSendType" SG_ 2482978624 TipperShakerRequest_UB_ISig_4 7;
BA_ "Platform_VMCU1_Sig" SG_ 2482978624 TipperShakerRequest_UB_ISig_4 1;
BA_ "GenSigSendType" SG_ 2482978624 TailLiftMotionRequest_UB_ISig_4 7;
BA_ "Platform_VMCU1_Sig" SG_ 2482978624 TailLiftMotionRequest_UB_ISig_4 1;
BA_ "GenSigCycleTime" SG_ 2482978624 TipperTailGateRequest_ISig_4 100;
BA_ "GenSigCycleTimeActive" SG_ 2482978624 TipperTailGateRequest_ISig_4 100;
BA_ "GenSigStartValue" SG_ 2482978624 TipperTailGateRequest_ISig_4 7;
BA_ "GenSigMaxLatency" SG_ 2482978624 TipperTailGateRequest_ISig_4 75;
BA_ "NeedsUpdateBit" SG_ 2482978624 TipperTailGateRequest_ISig_4 1;
BA_ "Platform_VMCU1_Sig" SG_ 2482978624 TipperTailGateRequest_ISig_4 1;
BA_ "GenSigCycleTime" SG_ 2482978624 TipperTippingBodySelection_ISig_ 100;
BA_ "GenSigCycleTimeActive" SG_ 2482978624 TipperTippingBodySelection_ISig_ 100;
BA_ "GenSigStartValue" SG_ 2482978624 TipperTippingBodySelection_ISig_ 3;
BA_ "GenSigMaxLatency" SG_ 2482978624 TipperTippingBodySelection_ISig_ 75;
BA_ "NeedsUpdateBit" SG_ 2482978624 TipperTippingBodySelection_ISig_ 1;
BA_ "Platform_VMCU1_Sig" SG_ 2482978624 TipperTippingBodySelection_ISig_ 1;
BA_ "SystemSignalLongSymbol" SG_ 2482978624 TipperTippingBodySelection_ISig_ "TipperTippingBodySelection_ISig_4";
BA_ "GenSigCycleTime" SG_ 2482978624 TipperEmergencyStop_ISig_4 100;
BA_ "GenSigCycleTimeActive" SG_ 2482978624 TipperEmergencyStop_ISig_4 100;
BA_ "GenSigStartValue" SG_ 2482978624 TipperEmergencyStop_ISig_4 3;
BA_ "GenSigMaxLatency" SG_ 2482978624 TipperEmergencyStop_ISig_4 75;
BA_ "NeedsUpdateBit" SG_ 2482978624 TipperEmergencyStop_ISig_4 1;
BA_ "Platform_VMCU1_Sig" SG_ 2482978624 TipperEmergencyStop_ISig_4 1;
BA_ "GenSigSendType" SG_ 2482978624 TipperTippingBodySelection_UB_IS 7;
BA_ "Platform_VMCU1_Sig" SG_ 2482978624 TipperTippingBodySelection_UB_IS 1;
BA_ "SystemSignalLongSymbol" SG_ 2482978624 TipperTippingBodySelection_UB_IS "TipperTippingBodySelection_UB_ISig_4";
BA_ "GenSigCycleTime" SG_ 2482978624 ExtraBbWrcWatchdog_ISig_4 100;
BA_ "GenSigCycleTimeActive" SG_ 2482978624 ExtraBbWrcWatchdog_ISig_4 100;
BA_ "GenSigStartValue" SG_ 2482978624 ExtraBbWrcWatchdog_ISig_4 3;
BA_ "GenSigMaxLatency" SG_ 2482978624 ExtraBbWrcWatchdog_ISig_4 75;
BA_ "NeedsUpdateBit" SG_ 2482978624 ExtraBbWrcWatchdog_ISig_4 1;
BA_ "Platform_VMCU1_Sig" SG_ 2482978624 ExtraBbWrcWatchdog_ISig_4 1;
BA_ "GenSigSendType" SG_ 2482978624 TipperEmergencyStop_UB_ISig_4 7;
BA_ "Platform_VMCU1_Sig" SG_ 2482978624 TipperEmergencyStop_UB_ISig_4 1;
BA_ "GenSigCycleTime" SG_ 2482978624 AutoFrontWheelDriveDrvReq 100;
BA_ "GenSigCycleTimeActive" SG_ 2482978624 AutoFrontWheelDriveDrvReq 100;
BA_ "GenSigStartValue" SG_ 2482978624 AutoFrontWheelDriveDrvReq 3;
BA_ "Platform_VMCU1_Sig" SG_ 2482978624 AutoFrontWheelDriveDrvReq 1;
BA_ "GenSigCycleTime" SG_ 2482978624 FrontalCollisionAccidentStatus_I 100;
BA_ "GenSigCycleTimeActive" SG_ 2482978624 FrontalCollisionAccidentStatus_I 100;
BA_ "GenSigStartValue" SG_ 2482978624 FrontalCollisionAccidentStatus_I 3;
BA_ "SystemSignalLongSymbol" SG_ 2482978624 FrontalCollisionAccidentStatus_I "FrontalCollisionAccidentStatus_ISig_4";
BA_ "GenSigCycleTime" SG_ 2482978624 ShortStopHeater_cmd_ISig_4 100;
BA_ "GenSigCycleTimeActive" SG_ 2482978624 ShortStopHeater_cmd_ISig_4 100;
BA_ "GenSigStartValue" SG_ 2482978624 ShortStopHeater_cmd_ISig_4 3;
BA_ "Platform_VMCU1_Sig" SG_ 2482978624 ShortStopHeater_cmd_ISig_4 1;
BA_ "GenSigSendType" SG_ 2482978624 TipperUpDownRequest_UB_ISig_4 7;
BA_ "Platform_VMCU1_Sig" SG_ 2482978624 TipperUpDownRequest_UB_ISig_4 1;
BA_ "GenSigCycleTime" SG_ 2482978624 TailLiftMotionRequest_ISig_4 100;
BA_ "GenSigCycleTimeActive" SG_ 2482978624 TailLiftMotionRequest_ISig_4 100;
BA_ "GenSigStartValue" SG_ 2482978624 TailLiftMotionRequest_ISig_4 7;
BA_ "GenSigMaxLatency" SG_ 2482978624 TailLiftMotionRequest_ISig_4 75;
BA_ "NeedsUpdateBit" SG_ 2482978624 TailLiftMotionRequest_ISig_4 1;
BA_ "Platform_VMCU1_Sig" SG_ 2482978624 TailLiftMotionRequest_ISig_4 1;
BA_ "GenSigCycleTime" SG_ 2482978624 TipperShakerRequest_ISig_4 100;
BA_ "GenSigCycleTimeActive" SG_ 2482978624 TipperShakerRequest_ISig_4 100;
BA_ "GenSigStartValue" SG_ 2482978624 TipperShakerRequest_ISig_4 3;
BA_ "GenSigMaxLatency" SG_ 2482978624 TipperShakerRequest_ISig_4 75;
BA_ "NeedsUpdateBit" SG_ 2482978624 TipperShakerRequest_ISig_4 1;
BA_ "Platform_VMCU1_Sig" SG_ 2482978624 TipperShakerRequest_ISig_4 1;
BA_ "GenSigCycleTime" SG_ 2482978624 TipperTarpaulinRequest_ISig_4 100;
BA_ "GenSigCycleTimeActive" SG_ 2482978624 TipperTarpaulinRequest_ISig_4 100;
BA_ "GenSigStartValue" SG_ 2482978624 TipperTarpaulinRequest_ISig_4 7;
BA_ "GenSigMaxLatency" SG_ 2482978624 TipperTarpaulinRequest_ISig_4 75;
BA_ "NeedsUpdateBit" SG_ 2482978624 TipperTarpaulinRequest_ISig_4 1;
BA_ "Platform_VMCU1_Sig" SG_ 2482978624 TipperTarpaulinRequest_ISig_4 1;
BA_ "GenSigCycleTime" SG_ 2482978624 ExtraHeating_status_ISig_4 100;
BA_ "GenSigCycleTimeActive" SG_ 2482978624 ExtraHeating_status_ISig_4 100;
BA_ "GenSigStartValue" SG_ 2482978624 ExtraHeating_status_ISig_4 3;
BA_ "Platform_VMCU1_Sig" SG_ 2482978624 ExtraHeating_status_ISig_4 1;
BA_ "GenSigSendType" SG_ 2482978624 ExtraBbWrcWatchdog_UB_ISig_4 7;
BA_ "Platform_VMCU1_Sig" SG_ 2482978624 ExtraBbWrcWatchdog_UB_ISig_4 1;
BA_ "GenSigSendType" SG_ 2499804480 PHTimer3_stat_Recurrence_ISig_4 1;
BA_ "GenSigCycleTime" SG_ 2499804480 PHTimer3_stat_Recurrence_ISig_4 100;
BA_ "GenSigCycleTimeActive" SG_ 2499804480 PHTimer3_stat_Recurrence_ISig_4 100;
BA_ "GenSigStartValue" SG_ 2499804480 PHTimer3_stat_Recurrence_ISig_4 15;
BA_ "NeedsUpdateBit" SG_ 2499804480 PHTimer3_stat_Recurrence_ISig_4 1;
BA_ "Platform_VMCU1_Sig" SG_ 2499804480 PHTimer3_stat_Recurrence_ISig_4 1;
BA_ "GenSigSendType" SG_ 2499804480 PHTimer2_stat_Hours_ISig_4 1;
BA_ "GenSigCycleTime" SG_ 2499804480 PHTimer2_stat_Hours_ISig_4 100;
BA_ "GenSigCycleTimeActive" SG_ 2499804480 PHTimer2_stat_Hours_ISig_4 100;
BA_ "GenSigStartValue" SG_ 2499804480 PHTimer2_stat_Hours_ISig_4 255;
BA_ "NeedsUpdateBit" SG_ 2499804480 PHTimer2_stat_Hours_ISig_4 1;
BA_ "Platform_VMCU1_Sig" SG_ 2499804480 PHTimer2_stat_Hours_ISig_4 1;
BA_ "GenSigSendType" SG_ 2499804480 PHTimer3_stat_sg_UB_ISig_4 7;
BA_ "GenSigCycleTime" SG_ 2499804480 PHTimer3_stat_sg_UB_ISig_4 100;
BA_ "GenSigCycleTimeActive" SG_ 2499804480 PHTimer3_stat_sg_UB_ISig_4 100;
BA_ "Platform_VMCU1_Sig" SG_ 2499804480 PHTimer3_stat_sg_UB_ISig_4 1;
BA_ "GenSigSendType" SG_ 2499804480 PHTimer2_stat_Status_ISig_4 1;
BA_ "GenSigCycleTime" SG_ 2499804480 PHTimer2_stat_Status_ISig_4 100;
BA_ "GenSigCycleTimeActive" SG_ 2499804480 PHTimer2_stat_Status_ISig_4 100;
BA_ "GenSigStartValue" SG_ 2499804480 PHTimer2_stat_Status_ISig_4 3;
BA_ "NeedsUpdateBit" SG_ 2499804480 PHTimer2_stat_Status_ISig_4 1;
BA_ "Platform_VMCU1_Sig" SG_ 2499804480 PHTimer2_stat_Status_ISig_4 1;
BA_ "GenSigSendType" SG_ 2499804480 PHTimer3_stat_StartDay_ISig_4 1;
BA_ "GenSigCycleTime" SG_ 2499804480 PHTimer3_stat_StartDay_ISig_4 100;
BA_ "GenSigCycleTimeActive" SG_ 2499804480 PHTimer3_stat_StartDay_ISig_4 100;
BA_ "GenSigStartValue" SG_ 2499804480 PHTimer3_stat_StartDay_ISig_4 15;
BA_ "NeedsUpdateBit" SG_ 2499804480 PHTimer3_stat_StartDay_ISig_4 1;
BA_ "Platform_VMCU1_Sig" SG_ 2499804480 PHTimer3_stat_StartDay_ISig_4 1;
BA_ "GenSigSendType" SG_ 2499804480 PHTimer2_stat_sg_UB_ISig_4 7;
BA_ "GenSigCycleTime" SG_ 2499804480 PHTimer2_stat_sg_UB_ISig_4 100;
BA_ "GenSigCycleTimeActive" SG_ 2499804480 PHTimer2_stat_sg_UB_ISig_4 100;
BA_ "Platform_VMCU1_Sig" SG_ 2499804480 PHTimer2_stat_sg_UB_ISig_4 1;
BA_ "GenSigSendType" SG_ 2499804480 PHTimer3_stat_Hours_ISig_4 1;
BA_ "GenSigCycleTime" SG_ 2499804480 PHTimer3_stat_Hours_ISig_4 100;
BA_ "GenSigCycleTimeActive" SG_ 2499804480 PHTimer3_stat_Hours_ISig_4 100;
BA_ "GenSigStartValue" SG_ 2499804480 PHTimer3_stat_Hours_ISig_4 255;
BA_ "NeedsUpdateBit" SG_ 2499804480 PHTimer3_stat_Hours_ISig_4 1;
BA_ "Platform_VMCU1_Sig" SG_ 2499804480 PHTimer3_stat_Hours_ISig_4 1;
BA_ "GenSigSendType" SG_ 2499804480 PHTimer3_stat_Status_ISig_4 1;
BA_ "GenSigCycleTime" SG_ 2499804480 PHTimer3_stat_Status_ISig_4 100;
BA_ "GenSigCycleTimeActive" SG_ 2499804480 PHTimer3_stat_Status_ISig_4 100;
BA_ "GenSigStartValue" SG_ 2499804480 PHTimer3_stat_Status_ISig_4 3;
BA_ "NeedsUpdateBit" SG_ 2499804480 PHTimer3_stat_Status_ISig_4 1;
BA_ "Platform_VMCU1_Sig" SG_ 2499804480 PHTimer3_stat_Status_ISig_4 1;
BA_ "GenSigSendType" SG_ 2499804480 PHTimer2_stat_Temp_ISig_4 1;
BA_ "GenSigCycleTime" SG_ 2499804480 PHTimer2_stat_Temp_ISig_4 100;
BA_ "GenSigCycleTimeActive" SG_ 2499804480 PHTimer2_stat_Temp_ISig_4 100;
BA_ "GenSigStartValue" SG_ 2499804480 PHTimer2_stat_Temp_ISig_4 31;
BA_ "NeedsUpdateBit" SG_ 2499804480 PHTimer2_stat_Temp_ISig_4 1;
BA_ "Platform_VMCU1_Sig" SG_ 2499804480 PHTimer2_stat_Temp_ISig_4 1;
BA_ "GenSigSendType" SG_ 2499804480 PHTimer3_stat_Minutes_ISig_4 1;
BA_ "GenSigCycleTime" SG_ 2499804480 PHTimer3_stat_Minutes_ISig_4 100;
BA_ "GenSigCycleTimeActive" SG_ 2499804480 PHTimer3_stat_Minutes_ISig_4 100;
BA_ "GenSigStartValue" SG_ 2499804480 PHTimer3_stat_Minutes_ISig_4 255;
BA_ "NeedsUpdateBit" SG_ 2499804480 PHTimer3_stat_Minutes_ISig_4 1;
BA_ "Platform_VMCU1_Sig" SG_ 2499804480 PHTimer3_stat_Minutes_ISig_4 1;
BA_ "GenSigSendType" SG_ 2499804480 PHTimer3_stat_Temp_ISig_4 1;
BA_ "GenSigCycleTime" SG_ 2499804480 PHTimer3_stat_Temp_ISig_4 100;
BA_ "GenSigCycleTimeActive" SG_ 2499804480 PHTimer3_stat_Temp_ISig_4 100;
BA_ "GenSigStartValue" SG_ 2499804480 PHTimer3_stat_Temp_ISig_4 31;
BA_ "NeedsUpdateBit" SG_ 2499804480 PHTimer3_stat_Temp_ISig_4 1;
BA_ "Platform_VMCU1_Sig" SG_ 2499804480 PHTimer3_stat_Temp_ISig_4 1;
BA_ "GenSigSendType" SG_ 2499804480 PHTimer2_stat_Recurrence_ISig_4 1;
BA_ "GenSigCycleTime" SG_ 2499804480 PHTimer2_stat_Recurrence_ISig_4 100;
BA_ "GenSigCycleTimeActive" SG_ 2499804480 PHTimer2_stat_Recurrence_ISig_4 100;
BA_ "GenSigStartValue" SG_ 2499804480 PHTimer2_stat_Recurrence_ISig_4 15;
BA_ "NeedsUpdateBit" SG_ 2499804480 PHTimer2_stat_Recurrence_ISig_4 1;
BA_ "Platform_VMCU1_Sig" SG_ 2499804480 PHTimer2_stat_Recurrence_ISig_4 1;
BA_ "GenSigSendType" SG_ 2499804480 PHTimer2_stat_StartDay_ISig_4 1;
BA_ "GenSigCycleTime" SG_ 2499804480 PHTimer2_stat_StartDay_ISig_4 100;
BA_ "GenSigCycleTimeActive" SG_ 2499804480 PHTimer2_stat_StartDay_ISig_4 100;
BA_ "GenSigStartValue" SG_ 2499804480 PHTimer2_stat_StartDay_ISig_4 15;
BA_ "NeedsUpdateBit" SG_ 2499804480 PHTimer2_stat_StartDay_ISig_4 1;
BA_ "Platform_VMCU1_Sig" SG_ 2499804480 PHTimer2_stat_StartDay_ISig_4 1;
BA_ "GenSigSendType" SG_ 2499804480 PHTimer2_stat_Minutes_ISig_4 1;
BA_ "GenSigCycleTime" SG_ 2499804480 PHTimer2_stat_Minutes_ISig_4 100;
BA_ "GenSigCycleTimeActive" SG_ 2499804480 PHTimer2_stat_Minutes_ISig_4 100;
BA_ "GenSigStartValue" SG_ 2499804480 PHTimer2_stat_Minutes_ISig_4 255;
BA_ "NeedsUpdateBit" SG_ 2499804480 PHTimer2_stat_Minutes_ISig_4 1;
BA_ "Platform_VMCU1_Sig" SG_ 2499804480 PHTimer2_stat_Minutes_ISig_4 1;
BA_ "GenSigSendType" SG_ 2499803968 PHTimer1_stat_Minutes_ISig_4 1;
BA_ "GenSigCycleTime" SG_ 2499803968 PHTimer1_stat_Minutes_ISig_4 100;
BA_ "GenSigCycleTimeActive" SG_ 2499803968 PHTimer1_stat_Minutes_ISig_4 100;
BA_ "GenSigStartValue" SG_ 2499803968 PHTimer1_stat_Minutes_ISig_4 255;
BA_ "NeedsUpdateBit" SG_ 2499803968 PHTimer1_stat_Minutes_ISig_4 1;
BA_ "Platform_VMCU1_Sig" SG_ 2499803968 PHTimer1_stat_Minutes_ISig_4 1;
BA_ "GenSigSendType" SG_ 2499803968 PHTimer1_stat_Status_ISig_4 1;
BA_ "GenSigCycleTime" SG_ 2499803968 PHTimer1_stat_Status_ISig_4 100;
BA_ "GenSigCycleTimeActive" SG_ 2499803968 PHTimer1_stat_Status_ISig_4 100;
BA_ "GenSigStartValue" SG_ 2499803968 PHTimer1_stat_Status_ISig_4 3;
BA_ "NeedsUpdateBit" SG_ 2499803968 PHTimer1_stat_Status_ISig_4 1;
BA_ "Platform_VMCU1_Sig" SG_ 2499803968 PHTimer1_stat_Status_ISig_4 1;
BA_ "GenSigSendType" SG_ 2499803968 PHTimer1_stat_Temp_ISig_4 1;
BA_ "GenSigCycleTime" SG_ 2499803968 PHTimer1_stat_Temp_ISig_4 100;
BA_ "GenSigCycleTimeActive" SG_ 2499803968 PHTimer1_stat_Temp_ISig_4 100;
BA_ "GenSigStartValue" SG_ 2499803968 PHTimer1_stat_Temp_ISig_4 31;
BA_ "NeedsUpdateBit" SG_ 2499803968 PHTimer1_stat_Temp_ISig_4 1;
BA_ "Platform_VMCU1_Sig" SG_ 2499803968 PHTimer1_stat_Temp_ISig_4 1;
BA_ "GenSigSendType" SG_ 2499803968 PHTimer1_stat_sg_UB_ISig_4 7;
BA_ "GenSigCycleTime" SG_ 2499803968 PHTimer1_stat_sg_UB_ISig_4 100;
BA_ "GenSigCycleTimeActive" SG_ 2499803968 PHTimer1_stat_sg_UB_ISig_4 100;
BA_ "Platform_VMCU1_Sig" SG_ 2499803968 PHTimer1_stat_sg_UB_ISig_4 1;
BA_ "GenSigSendType" SG_ 2499803968 PHTimer1_stat_Hours_ISig_4 1;
BA_ "GenSigCycleTime" SG_ 2499803968 PHTimer1_stat_Hours_ISig_4 100;
BA_ "GenSigCycleTimeActive" SG_ 2499803968 PHTimer1_stat_Hours_ISig_4 100;
BA_ "GenSigStartValue" SG_ 2499803968 PHTimer1_stat_Hours_ISig_4 255;
BA_ "NeedsUpdateBit" SG_ 2499803968 PHTimer1_stat_Hours_ISig_4 1;
BA_ "Platform_VMCU1_Sig" SG_ 2499803968 PHTimer1_stat_Hours_ISig_4 1;
BA_ "GenSigSendType" SG_ 2499803968 PHTimer1_stat_StartDay_ISig_4 1;
BA_ "GenSigCycleTime" SG_ 2499803968 PHTimer1_stat_StartDay_ISig_4 100;
BA_ "GenSigCycleTimeActive" SG_ 2499803968 PHTimer1_stat_StartDay_ISig_4 100;
BA_ "GenSigStartValue" SG_ 2499803968 PHTimer1_stat_StartDay_ISig_4 15;
BA_ "NeedsUpdateBit" SG_ 2499803968 PHTimer1_stat_StartDay_ISig_4 1;
BA_ "Platform_VMCU1_Sig" SG_ 2499803968 PHTimer1_stat_StartDay_ISig_4 1;
BA_ "GenSigSendType" SG_ 2499803968 PHTimer1_stat_Duration_ISig_4 1;
BA_ "GenSigCycleTime" SG_ 2499803968 PHTimer1_stat_Duration_ISig_4 100;
BA_ "GenSigCycleTimeActive" SG_ 2499803968 PHTimer1_stat_Duration_ISig_4 100;
BA_ "GenSigStartValue" SG_ 2499803968 PHTimer1_stat_Duration_ISig_4 127;
BA_ "NeedsUpdateBit" SG_ 2499803968 PHTimer1_stat_Duration_ISig_4 1;
BA_ "Platform_VMCU1_Sig" SG_ 2499803968 PHTimer1_stat_Duration_ISig_4 1;
BA_ "GenSigSendType" SG_ 2499803968 PHTimer1_stat_Recurrence_ISig_4 1;
BA_ "GenSigCycleTime" SG_ 2499803968 PHTimer1_stat_Recurrence_ISig_4 100;
BA_ "GenSigCycleTimeActive" SG_ 2499803968 PHTimer1_stat_Recurrence_ISig_4 100;
BA_ "GenSigStartValue" SG_ 2499803968 PHTimer1_stat_Recurrence_ISig_4 15;
BA_ "NeedsUpdateBit" SG_ 2499803968 PHTimer1_stat_Recurrence_ISig_4 1;
BA_ "Platform_VMCU1_Sig" SG_ 2499803968 PHTimer1_stat_Recurrence_ISig_4 1;
BA_ "GenSigSendType" SG_ 2499801342 CIOM_BB2_22S_FCS 7;
BA_ "Platform_VMCU1_Sig" SG_ 2499801342 CIOM_BB2_22S_FCS 1;
BA_ "GenSigSendType" SG_ 2499801341 EngineTimer_stat_Timer3StartDay_ 1;
BA_ "GenSigCycleTime" SG_ 2499801341 EngineTimer_stat_Timer3StartDay_ 100;
BA_ "GenSigCycleTimeActive" SG_ 2499801341 EngineTimer_stat_Timer3StartDay_ 100;
BA_ "GenSigStartValue" SG_ 2499801341 EngineTimer_stat_Timer3StartDay_ 15;
BA_ "NeedsUpdateBit" SG_ 2499801341 EngineTimer_stat_Timer3StartDay_ 1;
BA_ "Platform_VMCU1_Sig" SG_ 2499801341 EngineTimer_stat_Timer3StartDay_ 1;
BA_ "SystemSignalLongSymbol" SG_ 2499801341 EngineTimer_stat_Timer3StartDay_ "EngineTimer_stat_Timer3StartDay_ISig_4";
BA_ "GenSigSendType" SG_ 2499801341 EngineTimer_stat_Timer3_Status_I 1;
BA_ "GenSigCycleTime" SG_ 2499801341 EngineTimer_stat_Timer3_Status_I 100;
BA_ "GenSigCycleTimeActive" SG_ 2499801341 EngineTimer_stat_Timer3_Status_I 100;
BA_ "GenSigStartValue" SG_ 2499801341 EngineTimer_stat_Timer3_Status_I 3;
BA_ "NeedsUpdateBit" SG_ 2499801341 EngineTimer_stat_Timer3_Status_I 1;
BA_ "Platform_VMCU1_Sig" SG_ 2499801341 EngineTimer_stat_Timer3_Status_I 1;
BA_ "SystemSignalLongSymbol" SG_ 2499801341 EngineTimer_stat_Timer3_Status_I "EngineTimer_stat_Timer3_Status_ISig_4";
BA_ "GenSigSendType" SG_ 2499801341 EngineTimer_stat_Timer3Minutes_I 1;
BA_ "GenSigCycleTime" SG_ 2499801341 EngineTimer_stat_Timer3Minutes_I 100;
BA_ "GenSigCycleTimeActive" SG_ 2499801341 EngineTimer_stat_Timer3Minutes_I 100;
BA_ "GenSigStartValue" SG_ 2499801341 EngineTimer_stat_Timer3Minutes_I 255;
BA_ "NeedsUpdateBit" SG_ 2499801341 EngineTimer_stat_Timer3Minutes_I 1;
BA_ "Platform_VMCU1_Sig" SG_ 2499801341 EngineTimer_stat_Timer3Minutes_I 1;
BA_ "SystemSignalLongSymbol" SG_ 2499801341 EngineTimer_stat_Timer3Minutes_I "EngineTimer_stat_Timer3Minutes_ISig_4";
BA_ "GenSigSendType" SG_ 2499801341 EngineTimer_stat_Timer3Hours_ISi 1;
BA_ "GenSigCycleTime" SG_ 2499801341 EngineTimer_stat_Timer3Hours_ISi 100;
BA_ "GenSigCycleTimeActive" SG_ 2499801341 EngineTimer_stat_Timer3Hours_ISi 100;
BA_ "GenSigStartValue" SG_ 2499801341 EngineTimer_stat_Timer3Hours_ISi 255;
BA_ "NeedsUpdateBit" SG_ 2499801341 EngineTimer_stat_Timer3Hours_ISi 1;
BA_ "Platform_VMCU1_Sig" SG_ 2499801341 EngineTimer_stat_Timer3Hours_ISi 1;
BA_ "SystemSignalLongSymbol" SG_ 2499801341 EngineTimer_stat_Timer3Hours_ISi "EngineTimer_stat_Timer3Hours_ISig_4";
BA_ "GenSigSendType" SG_ 2499801341 EngineTimer_stat_Timer3Recurr_IS 1;
BA_ "GenSigCycleTime" SG_ 2499801341 EngineTimer_stat_Timer3Recurr_IS 100;
BA_ "GenSigCycleTimeActive" SG_ 2499801341 EngineTimer_stat_Timer3Recurr_IS 100;
BA_ "GenSigStartValue" SG_ 2499801341 EngineTimer_stat_Timer3Recurr_IS 15;
BA_ "NeedsUpdateBit" SG_ 2499801341 EngineTimer_stat_Timer3Recurr_IS 1;
BA_ "Platform_VMCU1_Sig" SG_ 2499801341 EngineTimer_stat_Timer3Recurr_IS 1;
BA_ "SystemSignalLongSymbol" SG_ 2499801341 EngineTimer_stat_Timer3Recurr_IS "EngineTimer_stat_Timer3Recurr_ISig_4";
BA_ "GenSigSendType" SG_ 2499801341 EngineTimer_stat_Timer1Hours_ISi 1;
BA_ "GenSigCycleTime" SG_ 2499801341 EngineTimer_stat_Timer1Hours_ISi 100;
BA_ "GenSigCycleTimeActive" SG_ 2499801341 EngineTimer_stat_Timer1Hours_ISi 100;
BA_ "GenSigStartValue" SG_ 2499801341 EngineTimer_stat_Timer1Hours_ISi 255;
BA_ "NeedsUpdateBit" SG_ 2499801341 EngineTimer_stat_Timer1Hours_ISi 1;
BA_ "Platform_VMCU1_Sig" SG_ 2499801341 EngineTimer_stat_Timer1Hours_ISi 1;
BA_ "SystemSignalLongSymbol" SG_ 2499801341 EngineTimer_stat_Timer1Hours_ISi "EngineTimer_stat_Timer1Hours_ISig_4";
BA_ "GenSigSendType" SG_ 2499801341 EngineTimer_stat_Timer2Hours_ISi 1;
BA_ "GenSigCycleTime" SG_ 2499801341 EngineTimer_stat_Timer2Hours_ISi 100;
BA_ "GenSigCycleTimeActive" SG_ 2499801341 EngineTimer_stat_Timer2Hours_ISi 100;
BA_ "GenSigStartValue" SG_ 2499801341 EngineTimer_stat_Timer2Hours_ISi 255;
BA_ "NeedsUpdateBit" SG_ 2499801341 EngineTimer_stat_Timer2Hours_ISi 1;
BA_ "Platform_VMCU1_Sig" SG_ 2499801341 EngineTimer_stat_Timer2Hours_ISi 1;
BA_ "SystemSignalLongSymbol" SG_ 2499801341 EngineTimer_stat_Timer2Hours_ISi "EngineTimer_stat_Timer2Hours_ISig_4";
BA_ "GenSigSendType" SG_ 2499801341 EngineTimer_stat_sg_UB_ISig_4 7;
BA_ "Platform_VMCU1_Sig" SG_ 2499801341 EngineTimer_stat_sg_UB_ISig_4 1;
BA_ "GenSigSendType" SG_ 2499801341 EngineTimer_stat_Timer2StartDay_ 1;
BA_ "GenSigCycleTime" SG_ 2499801341 EngineTimer_stat_Timer2StartDay_ 100;
BA_ "GenSigCycleTimeActive" SG_ 2499801341 EngineTimer_stat_Timer2StartDay_ 100;
BA_ "GenSigStartValue" SG_ 2499801341 EngineTimer_stat_Timer2StartDay_ 15;
BA_ "NeedsUpdateBit" SG_ 2499801341 EngineTimer_stat_Timer2StartDay_ 1;
BA_ "Platform_VMCU1_Sig" SG_ 2499801341 EngineTimer_stat_Timer2StartDay_ 1;
BA_ "SystemSignalLongSymbol" SG_ 2499801341 EngineTimer_stat_Timer2StartDay_ "EngineTimer_stat_Timer2StartDay_ISig_4";
BA_ "GenSigSendType" SG_ 2499801341 EngineTimer_stat_Timer1Recurr_IS 1;
BA_ "GenSigCycleTime" SG_ 2499801341 EngineTimer_stat_Timer1Recurr_IS 100;
BA_ "GenSigCycleTimeActive" SG_ 2499801341 EngineTimer_stat_Timer1Recurr_IS 100;
BA_ "GenSigStartValue" SG_ 2499801341 EngineTimer_stat_Timer1Recurr_IS 15;
BA_ "NeedsUpdateBit" SG_ 2499801341 EngineTimer_stat_Timer1Recurr_IS 1;
BA_ "Platform_VMCU1_Sig" SG_ 2499801341 EngineTimer_stat_Timer1Recurr_IS 1;
BA_ "SystemSignalLongSymbol" SG_ 2499801341 EngineTimer_stat_Timer1Recurr_IS "EngineTimer_stat_Timer1Recurr_ISig_4";
BA_ "GenSigSendType" SG_ 2499801341 EngineTimer_stat_Timer2Recurr_IS 1;
BA_ "GenSigCycleTime" SG_ 2499801341 EngineTimer_stat_Timer2Recurr_IS 100;
BA_ "GenSigCycleTimeActive" SG_ 2499801341 EngineTimer_stat_Timer2Recurr_IS 100;
BA_ "GenSigStartValue" SG_ 2499801341 EngineTimer_stat_Timer2Recurr_IS 15;
BA_ "NeedsUpdateBit" SG_ 2499801341 EngineTimer_stat_Timer2Recurr_IS 1;
BA_ "Platform_VMCU1_Sig" SG_ 2499801341 EngineTimer_stat_Timer2Recurr_IS 1;
BA_ "SystemSignalLongSymbol" SG_ 2499801341 EngineTimer_stat_Timer2Recurr_IS "EngineTimer_stat_Timer2Recurr_ISig_4";
BA_ "GenSigSendType" SG_ 2499801341 EngineTimer_stat_Timer1Minutes_I 1;
BA_ "GenSigCycleTime" SG_ 2499801341 EngineTimer_stat_Timer1Minutes_I 100;
BA_ "GenSigCycleTimeActive" SG_ 2499801341 EngineTimer_stat_Timer1Minutes_I 100;
BA_ "GenSigStartValue" SG_ 2499801341 EngineTimer_stat_Timer1Minutes_I 255;
BA_ "NeedsUpdateBit" SG_ 2499801341 EngineTimer_stat_Timer1Minutes_I 1;
BA_ "Platform_VMCU1_Sig" SG_ 2499801341 EngineTimer_stat_Timer1Minutes_I 1;
BA_ "SystemSignalLongSymbol" SG_ 2499801341 EngineTimer_stat_Timer1Minutes_I "EngineTimer_stat_Timer1Minutes_ISig_4";
BA_ "GenSigSendType" SG_ 2499801341 EngineTimer_stat_Timer1StartDay_ 1;
BA_ "GenSigCycleTime" SG_ 2499801341 EngineTimer_stat_Timer1StartDay_ 100;
BA_ "GenSigCycleTimeActive" SG_ 2499801341 EngineTimer_stat_Timer1StartDay_ 100;
BA_ "GenSigStartValue" SG_ 2499801341 EngineTimer_stat_Timer1StartDay_ 15;
BA_ "NeedsUpdateBit" SG_ 2499801341 EngineTimer_stat_Timer1StartDay_ 1;
BA_ "Platform_VMCU1_Sig" SG_ 2499801341 EngineTimer_stat_Timer1StartDay_ 1;
BA_ "SystemSignalLongSymbol" SG_ 2499801341 EngineTimer_stat_Timer1StartDay_ "EngineTimer_stat_Timer1StartDay_ISig_4";
BA_ "GenSigSendType" SG_ 2499801341 EngineTimer_stat_Timer2_Status_I 1;
BA_ "GenSigCycleTime" SG_ 2499801341 EngineTimer_stat_Timer2_Status_I 100;
BA_ "GenSigCycleTimeActive" SG_ 2499801341 EngineTimer_stat_Timer2_Status_I 100;
BA_ "GenSigStartValue" SG_ 2499801341 EngineTimer_stat_Timer2_Status_I 3;
BA_ "NeedsUpdateBit" SG_ 2499801341 EngineTimer_stat_Timer2_Status_I 1;
BA_ "Platform_VMCU1_Sig" SG_ 2499801341 EngineTimer_stat_Timer2_Status_I 1;
BA_ "SystemSignalLongSymbol" SG_ 2499801341 EngineTimer_stat_Timer2_Status_I "EngineTimer_stat_Timer2_Status_ISig_4";
BA_ "GenSigSendType" SG_ 2499801341 EngineTimer_stat_Timer2Minutes_I 1;
BA_ "GenSigCycleTime" SG_ 2499801341 EngineTimer_stat_Timer2Minutes_I 100;
BA_ "GenSigCycleTimeActive" SG_ 2499801341 EngineTimer_stat_Timer2Minutes_I 100;
BA_ "GenSigStartValue" SG_ 2499801341 EngineTimer_stat_Timer2Minutes_I 255;
BA_ "NeedsUpdateBit" SG_ 2499801341 EngineTimer_stat_Timer2Minutes_I 1;
BA_ "Platform_VMCU1_Sig" SG_ 2499801341 EngineTimer_stat_Timer2Minutes_I 1;
BA_ "SystemSignalLongSymbol" SG_ 2499801341 EngineTimer_stat_Timer2Minutes_I "EngineTimer_stat_Timer2Minutes_ISig_4";
BA_ "GenSigSendType" SG_ 2499801341 EngineTimer_stat_Timer1_Status_I 1;
BA_ "GenSigCycleTime" SG_ 2499801341 EngineTimer_stat_Timer1_Status_I 100;
BA_ "GenSigCycleTimeActive" SG_ 2499801341 EngineTimer_stat_Timer1_Status_I 100;
BA_ "GenSigStartValue" SG_ 2499801341 EngineTimer_stat_Timer1_Status_I 3;
BA_ "NeedsUpdateBit" SG_ 2499801341 EngineTimer_stat_Timer1_Status_I 1;
BA_ "Platform_VMCU1_Sig" SG_ 2499801341 EngineTimer_stat_Timer1_Status_I 1;
BA_ "SystemSignalLongSymbol" SG_ 2499801341 EngineTimer_stat_Timer1_Status_I "EngineTimer_stat_Timer1_Status_ISig_4";
BA_ "GenSigSendType" SG_ 2516513011 DynamicCode_value 1;
BA_ "GenSigStartValue" SG_ 2516513011 DynamicCode_value 4294967295;
BA_ "Platform_VMCU1_Sig" SG_ 2516513011 DynamicCode_value 1;
BA_ "GenSigSendType" SG_ 2499801330 PHTimer_rqst_Hours_ISig_4 1;
BA_ "GenSigCycleTime" SG_ 2499801330 PHTimer_rqst_Hours_ISig_4 100;
BA_ "GenSigCycleTimeActive" SG_ 2499801330 PHTimer_rqst_Hours_ISig_4 100;
BA_ "GenSigStartValue" SG_ 2499801330 PHTimer_rqst_Hours_ISig_4 255;
BA_ "Platform_VMCU1_Sig" SG_ 2499801330 PHTimer_rqst_Hours_ISig_4 1;
BA_ "GenSigSendType" SG_ 2499801330 PHTimer_rqst_Minutes_ISig_4 1;
BA_ "GenSigCycleTime" SG_ 2499801330 PHTimer_rqst_Minutes_ISig_4 100;
BA_ "GenSigCycleTimeActive" SG_ 2499801330 PHTimer_rqst_Minutes_ISig_4 100;
BA_ "GenSigStartValue" SG_ 2499801330 PHTimer_rqst_Minutes_ISig_4 255;
BA_ "Platform_VMCU1_Sig" SG_ 2499801330 PHTimer_rqst_Minutes_ISig_4 1;
BA_ "GenSigSendType" SG_ 2499801330 PHTimer_rqst_SetAlarmOper_ISig_4 1;
BA_ "GenSigCycleTime" SG_ 2499801330 PHTimer_rqst_SetAlarmOper_ISig_4 100;
BA_ "GenSigCycleTimeActive" SG_ 2499801330 PHTimer_rqst_SetAlarmOper_ISig_4 100;
BA_ "GenSigStartValue" SG_ 2499801330 PHTimer_rqst_SetAlarmOper_ISig_4 7;
BA_ "Platform_VMCU1_Sig" SG_ 2499801330 PHTimer_rqst_SetAlarmOper_ISig_4 1;
BA_ "GenSigSendType" SG_ 2499801330 PHTimer_rqst_DayOfWeekRq_ISig_4 1;
BA_ "GenSigCycleTime" SG_ 2499801330 PHTimer_rqst_DayOfWeekRq_ISig_4 100;
BA_ "GenSigCycleTimeActive" SG_ 2499801330 PHTimer_rqst_DayOfWeekRq_ISig_4 100;
BA_ "GenSigStartValue" SG_ 2499801330 PHTimer_rqst_DayOfWeekRq_ISig_4 15;
BA_ "Platform_VMCU1_Sig" SG_ 2499801330 PHTimer_rqst_DayOfWeekRq_ISig_4 1;
BA_ "GenSigSendType" SG_ 2499764033 CIOM_BB2_13S_FCS 7;
BA_ "Platform_VMCU1_Sig" SG_ 2499764033 CIOM_BB2_13S_FCS 1;
BA_ "GenSigSendType" SG_ 2499764032 EngineStartAuth_stat 1;
BA_ "GenSigMaxLatency" SG_ 2499764032 EngineStartAuth_stat 100;
BA_ "Platform_VMCU1_Sig" SG_ 2499764032 EngineStartAuth_stat 1;
BA_ "GenSigSendType" SG_ 2499747649 CIOM_BB2_12S_FCS 7;
BA_ "Platform_VMCU1_Sig" SG_ 2499747649 CIOM_BB2_12S_FCS 1;
BA_ "GenSigSendType" SG_ 2499747648 KeyAuthEncrypted_stat 1;
BA_ "GenSigMaxLatency" SG_ 2499747648 KeyAuthEncrypted_stat 100;
BA_ "Platform_VMCU1_Sig" SG_ 2499747648 KeyAuthEncrypted_stat 1;
BA_ "GenSigCycleTime" SG_ 2498741568 WindscreenDefrostInd_cmd_ISig_4 100;
BA_ "GenSigCycleTimeActive" SG_ 2498741568 WindscreenDefrostInd_cmd_ISig_4 100;
BA_ "GenSigMaxLatency" SG_ 2498741568 WindscreenDefrostInd_cmd_ISig_4 110;
BA_ "Platform_VMCU1_Sig" SG_ 2498741568 WindscreenDefrostInd_cmd_ISig_4 1;
BA_ "SeToolAncestorID_SIGNAL" SG_ 2498741568 WindscreenDefrostInd_cmd_ISig_4 "x0000001D04405ABB";
BA_ "SeToolItemID_SIGNAL" SG_ 2498741568 WindscreenDefrostInd_cmd_ISig_4 "x0000001D04405ABB";
BA_ "SeToolName_SIGNAL" SG_ 2498741568 WindscreenDefrostInd_cmd_ISig_4 "WindscreenDefrost_IndicationCmd";
BA_ "SeToolVersion_SIGNAL" SG_ 2498741568 WindscreenDefrostInd_cmd_ISig_4 "1";
BA_ "GenSigCycleTime" SG_ 2498741568 ACCoolingFanSpeedRequest 100;
BA_ "GenSigCycleTimeActive" SG_ 2498741568 ACCoolingFanSpeedRequest 100;
BA_ "GenSigStartValue" SG_ 2498741568 ACCoolingFanSpeedRequest 65535;
BA_ "GenSigMaxLatency" SG_ 2498741568 ACCoolingFanSpeedRequest 110;
BA_ "NeedsUpdateBit" SG_ 2498741568 ACCoolingFanSpeedRequest 1;
BA_ "Platform_VMCU1_Sig" SG_ 2498741568 ACCoolingFanSpeedRequest 1;
BA_ "SeToolAncestorID_SIGNAL" SG_ 2498741568 ACCoolingFanSpeedRequest "x0000001D0425B656";
BA_ "SeToolItemID_SIGNAL" SG_ 2498741568 ACCoolingFanSpeedRequest "x0000001D043C814A";
BA_ "SeToolName_SIGNAL" SG_ 2498741568 ACCoolingFanSpeedRequest "ACCoolingFanSpeedRequest";
BA_ "SeToolVersion_SIGNAL" SG_ 2498741568 ACCoolingFanSpeedRequest "2";
BA_ "GenSigCycleTime" SG_ 2498741568 AutoMode_IndicationCmd_ISig_4 100;
BA_ "GenSigCycleTimeActive" SG_ 2498741568 AutoMode_IndicationCmd_ISig_4 100;
BA_ "GenSigMaxLatency" SG_ 2498741568 AutoMode_IndicationCmd_ISig_4 110;
BA_ "Platform_VMCU1_Sig" SG_ 2498741568 AutoMode_IndicationCmd_ISig_4 1;
BA_ "SeToolAncestorID_SIGNAL" SG_ 2498741568 AutoMode_IndicationCmd_ISig_4 "x0000001D04405ABB";
BA_ "SeToolItemID_SIGNAL" SG_ 2498741568 AutoMode_IndicationCmd_ISig_4 "x0000001D04405ABB";
BA_ "SeToolName_SIGNAL" SG_ 2498741568 AutoMode_IndicationCmd_ISig_4 "AutoMode_IndicationCmd";
BA_ "SeToolVersion_SIGNAL" SG_ 2498741568 AutoMode_IndicationCmd_ISig_4 "1";
BA_ "GenSigCycleTime" SG_ 2498741568 CabTilt_rqst 100;
BA_ "GenSigCycleTimeActive" SG_ 2498741568 CabTilt_rqst 100;
BA_ "GenSigStartValue" SG_ 2498741568 CabTilt_rqst 3;
BA_ "GenSigMaxLatency" SG_ 2498741568 CabTilt_rqst 110;
BA_ "Platform_VMCU1_Sig" SG_ 2498741568 CabTilt_rqst 1;
BA_ "SeToolAncestorID_SIGNAL" SG_ 2498741568 CabTilt_rqst "x0000001D0416FC9A";
BA_ "SeToolItemID_SIGNAL" SG_ 2498741568 CabTilt_rqst "x0000001D0416FC9A";
BA_ "SeToolName_SIGNAL" SG_ 2498741568 CabTilt_rqst "CabTilt_rqst";
BA_ "SeToolVersion_SIGNAL" SG_ 2498741568 CabTilt_rqst "1";
BA_ "GenSigCycleTime" SG_ 2498741568 ACdisplayIndication_Cmd_ISig_4 100;
BA_ "GenSigCycleTimeActive" SG_ 2498741568 ACdisplayIndication_Cmd_ISig_4 100;
BA_ "GenSigStartValue" SG_ 2498741568 ACdisplayIndication_Cmd_ISig_4 7;
BA_ "GenSigMaxLatency" SG_ 2498741568 ACdisplayIndication_Cmd_ISig_4 110;
BA_ "Platform_VMCU1_Sig" SG_ 2498741568 ACdisplayIndication_Cmd_ISig_4 1;
BA_ "SeToolAncestorID_SIGNAL" SG_ 2498741568 ACdisplayIndication_Cmd_ISig_4 "x0000001D0441084F";
BA_ "SeToolItemID_SIGNAL" SG_ 2498741568 ACdisplayIndication_Cmd_ISig_4 "x0000001D0441084F";
BA_ "SeToolName_SIGNAL" SG_ 2498741568 ACdisplayIndication_Cmd_ISig_4 "ACmode_Status";
BA_ "SeToolVersion_SIGNAL" SG_ 2498741568 ACdisplayIndication_Cmd_ISig_4 "1";
BA_ "GenSigCycleTime" SG_ 2498741568 TemperatureRqstIndication_cmd_IS 100;
BA_ "GenSigCycleTimeActive" SG_ 2498741568 TemperatureRqstIndication_cmd_IS 100;
BA_ "GenSigStartValue" SG_ 2498741568 TemperatureRqstIndication_cmd_IS 31;
BA_ "GenSigMaxLatency" SG_ 2498741568 TemperatureRqstIndication_cmd_IS 110;
BA_ "Platform_VMCU1_Sig" SG_ 2498741568 TemperatureRqstIndication_cmd_IS 1;
BA_ "SeToolAncestorID_SIGNAL" SG_ 2498741568 TemperatureRqstIndication_cmd_IS "x0000001D04150607";
BA_ "SeToolItemID_SIGNAL" SG_ 2498741568 TemperatureRqstIndication_cmd_IS "x0000001D043FAF4A";
BA_ "SeToolName_SIGNAL" SG_ 2498741568 TemperatureRqstIndication_cmd_IS "TemperatureRqstIndication_cmd ";
BA_ "SeToolVersion_SIGNAL" SG_ 2498741568 TemperatureRqstIndication_cmd_IS "4";
BA_ "SystemSignalLongSymbol" SG_ 2498741568 TemperatureRqstIndication_cmd_IS "TemperatureRqstIndication_cmd_ISig_4";
BA_ "GenSigCycleTime" SG_ 2498741568 Pto3CabRequest 100;
BA_ "GenSigCycleTimeActive" SG_ 2498741568 Pto3CabRequest 100;
BA_ "GenSigStartValue" SG_ 2498741568 Pto3CabRequest 3;
BA_ "GenSigMaxLatency" SG_ 2498741568 Pto3CabRequest 110;
BA_ "Platform_VMCU1_Sig" SG_ 2498741568 Pto3CabRequest 1;
BA_ "SeToolAncestorID_SIGNAL" SG_ 2498741568 Pto3CabRequest "x0000001D0439DD78";
BA_ "SeToolItemID_SIGNAL" SG_ 2498741568 Pto3CabRequest "x0000001D0439DD78";
BA_ "SeToolName_SIGNAL" SG_ 2498741568 Pto3CabRequest "Pto3CabRequest";
BA_ "SeToolVersion_SIGNAL" SG_ 2498741568 Pto3CabRequest "1";
BA_ "GenSigCycleTime" SG_ 2498741568 Pto4CabRequest 100;
BA_ "GenSigCycleTimeActive" SG_ 2498741568 Pto4CabRequest 100;
BA_ "GenSigStartValue" SG_ 2498741568 Pto4CabRequest 3;
BA_ "GenSigMaxLatency" SG_ 2498741568 Pto4CabRequest 110;
BA_ "Platform_VMCU1_Sig" SG_ 2498741568 Pto4CabRequest 1;
BA_ "SeToolAncestorID_SIGNAL" SG_ 2498741568 Pto4CabRequest "x0000001D0439DD7A";
BA_ "SeToolItemID_SIGNAL" SG_ 2498741568 Pto4CabRequest "x0000001D0439DD7A";
BA_ "SeToolName_SIGNAL" SG_ 2498741568 Pto4CabRequest "Pto4CabRequest";
BA_ "SeToolVersion_SIGNAL" SG_ 2498741568 Pto4CabRequest "1";
BA_ "GenSigSendType" SG_ 2498741568 ACCoolingFanSpeedRequest_UB 7;
BA_ "Platform_VMCU1_Sig" SG_ 2498741568 ACCoolingFanSpeedRequest_UB 1;
BA_ "GenSigCycleTime" SG_ 2498741568 SRSAirbagStatus_ISig_4 100;
BA_ "GenSigCycleTimeActive" SG_ 2498741568 SRSAirbagStatus_ISig_4 100;
BA_ "GenSigStartValue" SG_ 2498741568 SRSAirbagStatus_ISig_4 3;
BA_ "GenSigMaxLatency" SG_ 2498741568 SRSAirbagStatus_ISig_4 110;
BA_ "Platform_VMCU1_Sig" SG_ 2498741568 SRSAirbagStatus_ISig_4 1;
BA_ "SeToolAncestorID_SIGNAL" SG_ 2498741568 SRSAirbagStatus_ISig_4 "x0000001D04147207";
BA_ "SeToolItemID_SIGNAL" SG_ 2498741568 SRSAirbagStatus_ISig_4 "x0000001D042F372C";
BA_ "SeToolName_SIGNAL" SG_ 2498741568 SRSAirbagStatus_ISig_4 "SRSAirbagStatus";
BA_ "SeToolVersion_SIGNAL" SG_ 2498741568 SRSAirbagStatus_ISig_4 "2";
BA_ "GenSigCycleTime" SG_ 2498741568 Area_9level_Indication_cmd_ISig_ 100;
BA_ "GenSigCycleTimeActive" SG_ 2498741568 Area_9level_Indication_cmd_ISig_ 100;
BA_ "GenSigStartValue" SG_ 2498741568 Area_9level_Indication_cmd_ISig_ 15;
BA_ "GenSigMaxLatency" SG_ 2498741568 Area_9level_Indication_cmd_ISig_ 110;
BA_ "Platform_VMCU1_Sig" SG_ 2498741568 Area_9level_Indication_cmd_ISig_ 1;
BA_ "SeToolAncestorID_SIGNAL" SG_ 2498741568 Area_9level_Indication_cmd_ISig_ "x0000001D0438D144";
BA_ "SeToolItemID_SIGNAL" SG_ 2498741568 Area_9level_Indication_cmd_ISig_ "x0000001D0438D144";
BA_ "SeToolName_SIGNAL" SG_ 2498741568 Area_9level_Indication_cmd_ISig_ "Area_9level_Indication_cmd";
BA_ "SeToolVersion_SIGNAL" SG_ 2498741568 Area_9level_Indication_cmd_ISig_ "1";
BA_ "SystemSignalLongSymbol" SG_ 2498741568 Area_9level_Indication_cmd_ISig_ "Area_9level_Indication_cmd_ISig_4";
BA_ "GenSigCycleTime" SG_ 2498741568 AutoDefogIndication_Cmd_ISig_4 100;
BA_ "GenSigCycleTimeActive" SG_ 2498741568 AutoDefogIndication_Cmd_ISig_4 100;
BA_ "GenSigStartValue" SG_ 2498741568 AutoDefogIndication_Cmd_ISig_4 7;
BA_ "GenSigMaxLatency" SG_ 2498741568 AutoDefogIndication_Cmd_ISig_4 110;
BA_ "Platform_VMCU1_Sig" SG_ 2498741568 AutoDefogIndication_Cmd_ISig_4 1;
BA_ "SeToolAncestorID_SIGNAL" SG_ 2498741568 AutoDefogIndication_Cmd_ISig_4 "x0000001D0441080E";
BA_ "SeToolItemID_SIGNAL" SG_ 2498741568 AutoDefogIndication_Cmd_ISig_4 "x0000001D0441080E";
BA_ "SeToolName_SIGNAL" SG_ 2498741568 AutoDefogIndication_Cmd_ISig_4 "AutoDefogmode_Status";
BA_ "SeToolVersion_SIGNAL" SG_ 2498741568 AutoDefogIndication_Cmd_ISig_4 "1";
BA_ "GenSigCycleTime" SG_ 2498741568 FrontLidAjar_Stat 100;
BA_ "GenSigCycleTimeActive" SG_ 2498741568 FrontLidAjar_Stat 100;
BA_ "GenSigStartValue" SG_ 2498741568 FrontLidAjar_Stat 3;
BA_ "Platform_VMCU1_Sig" SG_ 2498741568 FrontLidAjar_Stat 1;
BA_ "GenSigCycleTime" SG_ 2498741568 ParkingHeaterCleaning_Rqst_ISig_ 100;
BA_ "GenSigCycleTimeActive" SG_ 2498741568 ParkingHeaterCleaning_Rqst_ISig_ 100;
BA_ "GenSigStartValue" SG_ 2498741568 ParkingHeaterCleaning_Rqst_ISig_ 3;
BA_ "Platform_VMCU1_Sig" SG_ 2498741568 ParkingHeaterCleaning_Rqst_ISig_ 1;
BA_ "SystemSignalLongSymbol" SG_ 2498741568 ParkingHeaterCleaning_Rqst_ISig_ "ParkingHeaterCleaning_Rqst_ISig_4";
BA_ "GenSigCycleTime" SG_ 2498741568 Pto2CabRequest 100;
BA_ "GenSigCycleTimeActive" SG_ 2498741568 Pto2CabRequest 100;
BA_ "GenSigStartValue" SG_ 2498741568 Pto2CabRequest 3;
BA_ "GenSigMaxLatency" SG_ 2498741568 Pto2CabRequest 110;
BA_ "Platform_VMCU1_Sig" SG_ 2498741568 Pto2CabRequest 1;
BA_ "SeToolAncestorID_SIGNAL" SG_ 2498741568 Pto2CabRequest "x0000001D0439DD75";
BA_ "SeToolItemID_SIGNAL" SG_ 2498741568 Pto2CabRequest "x0000001D0439DD75";
BA_ "SeToolName_SIGNAL" SG_ 2498741568 Pto2CabRequest "Pto2CabRequest";
BA_ "SeToolVersion_SIGNAL" SG_ 2498741568 Pto2CabRequest "1";
BA_ "GenSigCycleTime" SG_ 2498741568 AutoBlowerLevelIndication_Cmd_IS 100;
BA_ "GenSigCycleTimeActive" SG_ 2498741568 AutoBlowerLevelIndication_Cmd_IS 100;
BA_ "GenSigStartValue" SG_ 2498741568 AutoBlowerLevelIndication_Cmd_IS 7;
BA_ "GenSigMaxLatency" SG_ 2498741568 AutoBlowerLevelIndication_Cmd_IS 110;
BA_ "Platform_VMCU1_Sig" SG_ 2498741568 AutoBlowerLevelIndication_Cmd_IS 1;
BA_ "SeToolAncestorID_SIGNAL" SG_ 2498741568 AutoBlowerLevelIndication_Cmd_IS "x0000001D044108C4";
BA_ "SeToolItemID_SIGNAL" SG_ 2498741568 AutoBlowerLevelIndication_Cmd_IS "x0000001D044108C4";
BA_ "SeToolName_SIGNAL" SG_ 2498741568 AutoBlowerLevelIndication_Cmd_IS "AutoBlowerLevel_Status";
BA_ "SeToolVersion_SIGNAL" SG_ 2498741568 AutoBlowerLevelIndication_Cmd_IS "1";
BA_ "SystemSignalLongSymbol" SG_ 2498741568 AutoBlowerLevelIndication_Cmd_IS "AutoBlowerLevelIndication_Cmd_ISig_4";
BA_ "GenSigCycleTime" SG_ 2498741568 SeatSwivelWarning_rqst 100;
BA_ "GenSigCycleTimeActive" SG_ 2498741568 SeatSwivelWarning_rqst 100;
BA_ "GenSigStartValue" SG_ 2498741568 SeatSwivelWarning_rqst 3;
BA_ "GenSigMaxLatency" SG_ 2498741568 SeatSwivelWarning_rqst 110;
BA_ "Platform_VMCU1_Sig" SG_ 2498741568 SeatSwivelWarning_rqst 1;
BA_ "SeToolAncestorID_SIGNAL" SG_ 2498741568 SeatSwivelWarning_rqst "x0000001D0418D487";
BA_ "SeToolItemID_SIGNAL" SG_ 2498741568 SeatSwivelWarning_rqst "x0000001D0418D487";
BA_ "SeToolName_SIGNAL" SG_ 2498741568 SeatSwivelWarning_rqst "SeatSwivelWarning_rqst";
BA_ "SeToolVersion_SIGNAL" SG_ 2498741568 SeatSwivelWarning_rqst "1";
BA_ "GenSigCycleTime" SG_ 2498741568 AQSmodeIndication_Cmd_ISig_4 100;
BA_ "GenSigCycleTimeActive" SG_ 2498741568 AQSmodeIndication_Cmd_ISig_4 100;
BA_ "GenSigStartValue" SG_ 2498741568 AQSmodeIndication_Cmd_ISig_4 3;
BA_ "GenSigMaxLatency" SG_ 2498741568 AQSmodeIndication_Cmd_ISig_4 110;
BA_ "Platform_VMCU1_Sig" SG_ 2498741568 AQSmodeIndication_Cmd_ISig_4 1;
BA_ "SeToolAncestorID_SIGNAL" SG_ 2498741568 AQSmodeIndication_Cmd_ISig_4 "x0000001D0441089D";
BA_ "SeToolItemID_SIGNAL" SG_ 2498741568 AQSmodeIndication_Cmd_ISig_4 "x0000001D0441089D";
BA_ "SeToolName_SIGNAL" SG_ 2498741568 AQSmodeIndication_Cmd_ISig_4 "AQSmode_Status";
BA_ "SeToolVersion_SIGNAL" SG_ 2498741568 AQSmodeIndication_Cmd_ISig_4 "1";
BA_ "GenSigCycleTime" SG_ 2498741568 TemporaryRSLDriverRequest 100;
BA_ "GenSigCycleTimeActive" SG_ 2498741568 TemporaryRSLDriverRequest 100;
BA_ "GenSigStartValue" SG_ 2498741568 TemporaryRSLDriverRequest 3;
BA_ "Platform_VMCU1_Sig" SG_ 2498741568 TemporaryRSLDriverRequest 1;
BA_ "GenSigCycleTime" SG_ 2498741568 Pto1CabRequest 100;
BA_ "GenSigCycleTimeActive" SG_ 2498741568 Pto1CabRequest 100;
BA_ "GenSigStartValue" SG_ 2498741568 Pto1CabRequest 3;
BA_ "GenSigMaxLatency" SG_ 2498741568 Pto1CabRequest 110;
BA_ "Platform_VMCU1_Sig" SG_ 2498741568 Pto1CabRequest 1;
BA_ "SeToolAncestorID_SIGNAL" SG_ 2498741568 Pto1CabRequest "x0000001D0439DD73";
BA_ "SeToolItemID_SIGNAL" SG_ 2498741568 Pto1CabRequest "x0000001D0439DD73";
BA_ "SeToolName_SIGNAL" SG_ 2498741568 Pto1CabRequest "Pto1CabRequest";
BA_ "SeToolVersion_SIGNAL" SG_ 2498741568 Pto1CabRequest "1";
BA_ "GenSigCycleTime" SG_ 2483023936 LCS_EnableSwitch_rqst 100;
BA_ "GenSigCycleTimeActive" SG_ 2483023936 LCS_EnableSwitch_rqst 100;
BA_ "GenSigStartValue" SG_ 2483023936 LCS_EnableSwitch_rqst 3;
BA_ "GenSigMaxLatency" SG_ 2483023936 LCS_EnableSwitch_rqst 68;
BA_ "Platform_VMCU1_Sig" SG_ 2483023936 LCS_EnableSwitch_rqst 1;
BA_ "SeToolAncestorID_SIGNAL" SG_ 2483023936 LCS_EnableSwitch_rqst "x0000001D041691AD";
BA_ "SeToolItemID_SIGNAL" SG_ 2483023936 LCS_EnableSwitch_rqst "x0000001D041691AD";
BA_ "SeToolName_SIGNAL" SG_ 2483023936 LCS_EnableSwitch_rqst "LCS_EnableSwitch_rqst";
BA_ "SeToolVersion_SIGNAL" SG_ 2483023936 LCS_EnableSwitch_rqst "1";
BA_ "GenSigCycleTime" SG_ 2483023936 PH_Activation_cmd_ISig_4 100;
BA_ "GenSigCycleTimeActive" SG_ 2483023936 PH_Activation_cmd_ISig_4 100;
BA_ "GenSigStartValue" SG_ 2483023936 PH_Activation_cmd_ISig_4 7;
BA_ "Platform_VMCU1_Sig" SG_ 2483023936 PH_Activation_cmd_ISig_4 1;
BA_ "GenSigCycleTime" SG_ 2483023936 EscCrossCountryActivation_rqst 100;
BA_ "GenSigCycleTimeActive" SG_ 2483023936 EscCrossCountryActivation_rqst 100;
BA_ "GenSigStartValue" SG_ 2483023936 EscCrossCountryActivation_rqst 3;
BA_ "GenSigMaxLatency" SG_ 2483023936 EscCrossCountryActivation_rqst 68;
BA_ "Platform_VMCU1_Sig" SG_ 2483023936 EscCrossCountryActivation_rqst 1;
BA_ "SeToolAncestorID_SIGNAL" SG_ 2483023936 EscCrossCountryActivation_rqst "x0000001D041B2E58";
BA_ "SeToolItemID_SIGNAL" SG_ 2483023936 EscCrossCountryActivation_rqst "x0000001D041B2E58";
BA_ "SeToolName_SIGNAL" SG_ 2483023936 EscCrossCountryActivation_rqst "EscCrossCountryActivationRequest";
BA_ "SeToolVersion_SIGNAL" SG_ 2483023936 EscCrossCountryActivation_rqst "1";
BA_ "GenSigCycleTime" SG_ 2483023936 StaticCornerLightMode 100;
BA_ "GenSigCycleTimeActive" SG_ 2483023936 StaticCornerLightMode 100;
BA_ "GenSigStartValue" SG_ 2483023936 StaticCornerLightMode 3;
BA_ "Platform_VMCU1_Sig" SG_ 2483023936 StaticCornerLightMode 1;
BA_ "GenSigCycleTime" SG_ 2483023936 SplitBoxDifflockActvnDrvrRqst_IS 100;
BA_ "GenSigCycleTimeActive" SG_ 2483023936 SplitBoxDifflockActvnDrvrRqst_IS 100;
BA_ "GenSigStartValue" SG_ 2483023936 SplitBoxDifflockActvnDrvrRqst_IS 3;
BA_ "NeedsUpdateBit" SG_ 2483023936 SplitBoxDifflockActvnDrvrRqst_IS 1;
BA_ "Platform_VMCU1_Sig" SG_ 2483023936 SplitBoxDifflockActvnDrvrRqst_IS 1;
BA_ "SystemSignalLongSymbol" SG_ 2483023936 SplitBoxDifflockActvnDrvrRqst_IS "SplitBoxDifflockActvnDrvrRqst_ISig_4";
BA_ "GenSigCycleTime" SG_ 2483023936 ConstructionSwitch_stat 100;
BA_ "GenSigCycleTimeActive" SG_ 2483023936 ConstructionSwitch_stat 100;
BA_ "GenSigStartValue" SG_ 2483023936 ConstructionSwitch_stat 3;
BA_ "GenSigMaxLatency" SG_ 2483023936 ConstructionSwitch_stat 26;
BA_ "Platform_VMCU1_Sig" SG_ 2483023936 ConstructionSwitch_stat 1;
BA_ "SeToolAncestorID_SIGNAL" SG_ 2483023936 ConstructionSwitch_stat "x0000001D0423C42C";
BA_ "SeToolItemID_SIGNAL" SG_ 2483023936 ConstructionSwitch_stat "x0000001D0423C42C";
BA_ "SeToolName_SIGNAL" SG_ 2483023936 ConstructionSwitch_stat "ConstructionSwitch_stat";
BA_ "SeToolVersion_SIGNAL" SG_ 2483023936 ConstructionSwitch_stat "1";
BA_ "GenSigCycleTime" SG_ 2483023936 ATCFrontWheelDriveRequest 100;
BA_ "GenSigCycleTimeActive" SG_ 2483023936 ATCFrontWheelDriveRequest 100;
BA_ "GenSigStartValue" SG_ 2483023936 ATCFrontWheelDriveRequest 3;
BA_ "GenSigCycleTime" SG_ 2483023936 EscCabActionRequest 100;
BA_ "GenSigCycleTimeActive" SG_ 2483023936 EscCabActionRequest 100;
BA_ "GenSigStartValue" SG_ 2483023936 EscCabActionRequest 7;
BA_ "GenSigMaxLatency" SG_ 2483023936 EscCabActionRequest 68;
BA_ "Platform_VMCU1_Sig" SG_ 2483023936 EscCabActionRequest 1;
BA_ "SeToolAncestorID_SIGNAL" SG_ 2483023936 EscCabActionRequest "x0000001D044050FA";
BA_ "SeToolItemID_SIGNAL" SG_ 2483023936 EscCabActionRequest "x0000001D044050FA";
BA_ "SeToolName_SIGNAL" SG_ 2483023936 EscCabActionRequest "EscCabActionRequest";
BA_ "SeToolVersion_SIGNAL" SG_ 2483023936 EscCabActionRequest "1";
BA_ "GenSigCycleTime" SG_ 2483023936 AdjustRequestForIdle 100;
BA_ "GenSigCycleTimeActive" SG_ 2483023936 AdjustRequestForIdle 100;
BA_ "GenSigStartValue" SG_ 2483023936 AdjustRequestForIdle 7;
BA_ "GenSigCycleTime" SG_ 2483023936 SCL_LogicPowerOutput_stat 100;
BA_ "GenSigCycleTimeActive" SG_ 2483023936 SCL_LogicPowerOutput_stat 100;
BA_ "GenSigStartValue" SG_ 2483023936 SCL_LogicPowerOutput_stat 3;
BA_ "GenSigMaxLatency" SG_ 2483023936 SCL_LogicPowerOutput_stat 68;
BA_ "Platform_VMCU1_Sig" SG_ 2483023936 SCL_LogicPowerOutput_stat 1;
BA_ "SeToolAncestorID_SIGNAL" SG_ 2483023936 SCL_LogicPowerOutput_stat "x0000001D04184530";
BA_ "SeToolItemID_SIGNAL" SG_ 2483023936 SCL_LogicPowerOutput_stat "x0000001D04184530";
BA_ "SeToolName_SIGNAL" SG_ 2483023936 SCL_LogicPowerOutput_stat "SCL_LogicPowerOutput_stat";
BA_ "SeToolVersion_SIGNAL" SG_ 2483023936 SCL_LogicPowerOutput_stat "1";
BA_ "GenSigCycleTime" SG_ 2483023936 PinCode_validity_time 100;
BA_ "GenSigCycleTimeActive" SG_ 2483023936 PinCode_validity_time 100;
BA_ "GenSigStartValue" SG_ 2483023936 PinCode_validity_time 255;
BA_ "Platform_VMCU1_Sig" SG_ 2483023936 PinCode_validity_time 1;
BA_ "GenSigCycleTime" SG_ 2483023936 StatTrailerBrakeSwitchStatus 100;
BA_ "GenSigCycleTimeActive" SG_ 2483023936 StatTrailerBrakeSwitchStatus 100;
BA_ "GenSigStartValue" SG_ 2483023936 StatTrailerBrakeSwitchStatus 3;
BA_ "Platform_VMCU1_Sig" SG_ 2483023936 StatTrailerBrakeSwitchStatus 1;
BA_ "GenSigSendType" SG_ 2483023936 SplitBoxDifflockActvnDrvrRqst_UB 7;
BA_ "Platform_VMCU1_Sig" SG_ 2483023936 SplitBoxDifflockActvnDrvrRqst_UB 1;
BA_ "SystemSignalLongSymbol" SG_ 2483023936 SplitBoxDifflockActvnDrvrRqst_UB "SplitBoxDifflockActvnDrvrRqst_UB_ISig_4";
BA_ "GenSigCycleTime" SG_ 2483023936 RoofHatch_HMI_rqst 100;
BA_ "GenSigCycleTimeActive" SG_ 2483023936 RoofHatch_HMI_rqst 100;
BA_ "GenSigStartValue" SG_ 2483023936 RoofHatch_HMI_rqst 7;
BA_ "Platform_VMCU1_Sig" SG_ 2483023936 RoofHatch_HMI_rqst 1;
BA_ "GenSigCycleTime" SG_ 2483023936 EscCabEnable 100;
BA_ "GenSigCycleTimeActive" SG_ 2483023936 EscCabEnable 100;
BA_ "GenSigStartValue" SG_ 2483023936 EscCabEnable 3;
BA_ "GenSigMaxLatency" SG_ 2483023936 EscCabEnable 68;
BA_ "Platform_VMCU1_Sig" SG_ 2483023936 EscCabEnable 1;
BA_ "SeToolAncestorID_SIGNAL" SG_ 2483023936 EscCabEnable "x0000001D043DFB25";
BA_ "SeToolItemID_SIGNAL" SG_ 2483023936 EscCabEnable "x0000001D043DFB25";
BA_ "SeToolName_SIGNAL" SG_ 2483023936 EscCabEnable "EscCabEnable";
BA_ "SeToolVersion_SIGNAL" SG_ 2483023936 EscCabEnable "1";
BA_ "GenSigCycleTime" SG_ 2483023936 ExtraSideMarkers_Rqst 100;
BA_ "GenSigCycleTimeActive" SG_ 2483023936 ExtraSideMarkers_Rqst 100;
BA_ "GenSigStartValue" SG_ 2483023936 ExtraSideMarkers_Rqst 3;
BA_ "Platform_VMCU1_Sig" SG_ 2483023936 ExtraSideMarkers_Rqst 1;
BA_ "GenSigCycleTime" SG_ 2483023936 LevelingThumbwheel_stat 100;
BA_ "GenSigCycleTimeActive" SG_ 2483023936 LevelingThumbwheel_stat 100;
BA_ "GenSigStartValue" SG_ 2483023936 LevelingThumbwheel_stat 31;
BA_ "Platform_VMCU1_Sig" SG_ 2483023936 LevelingThumbwheel_stat 1;
BA_ "GenSigCycleTime" SG_ 2483023936 MemoDisplayIndication_Cmd_ISig_4 100;
BA_ "GenSigCycleTimeActive" SG_ 2483023936 MemoDisplayIndication_Cmd_ISig_4 100;
BA_ "GenSigStartValue" SG_ 2483023936 MemoDisplayIndication_Cmd_ISig_4 7;
BA_ "GenSigMaxLatency" SG_ 2483023936 MemoDisplayIndication_Cmd_ISig_4 68;
BA_ "Platform_VMCU1_Sig" SG_ 2483023936 MemoDisplayIndication_Cmd_ISig_4 1;
BA_ "SeToolAncestorID_SIGNAL" SG_ 2483023936 MemoDisplayIndication_Cmd_ISig_4 "x0000001D044050F4";
BA_ "SeToolItemID_SIGNAL" SG_ 2483023936 MemoDisplayIndication_Cmd_ISig_4 "x0000001D044050F4";
BA_ "SeToolName_SIGNAL" SG_ 2483023936 MemoDisplayIndication_Cmd_ISig_4 "Memo_Status";
BA_ "SeToolVersion_SIGNAL" SG_ 2483023936 MemoDisplayIndication_Cmd_ISig_4 "1";
BA_ "GenSigCycleTime" SG_ 2483023936 FCW_Enable 100;
BA_ "GenSigCycleTimeActive" SG_ 2483023936 FCW_Enable 100;
BA_ "GenSigStartValue" SG_ 2483023936 FCW_Enable 3;
BA_ "GenSigMaxLatency" SG_ 2483023936 FCW_Enable 68;
BA_ "Platform_VMCU1_Sig" SG_ 2483023936 FCW_Enable 1;
BA_ "SeToolAncestorID_SIGNAL" SG_ 2483023936 FCW_Enable "x0000001D0416642C";
BA_ "SeToolItemID_SIGNAL" SG_ 2483023936 FCW_Enable "x0000001D0416642C";
BA_ "SeToolName_SIGNAL" SG_ 2483023936 FCW_Enable "FCW_Enable";
BA_ "SeToolVersion_SIGNAL" SG_ 2483023936 FCW_Enable "1";
BA_ "GenSigCycleTime" SG_ 2483023936 DASActivation_rqst 100;
BA_ "GenSigCycleTimeActive" SG_ 2483023936 DASActivation_rqst 100;
BA_ "GenSigStartValue" SG_ 2483023936 DASActivation_rqst 3;
BA_ "GenSigMaxLatency" SG_ 2483023936 DASActivation_rqst 68;
BA_ "Platform_VMCU1_Sig" SG_ 2483023936 DASActivation_rqst 1;
BA_ "SeToolAncestorID_SIGNAL" SG_ 2483023936 DASActivation_rqst "x0000001D04169A8A";
BA_ "SeToolItemID_SIGNAL" SG_ 2483023936 DASActivation_rqst "x0000001D04290712";
BA_ "SeToolName_SIGNAL" SG_ 2483023936 DASActivation_rqst "DASActivation_rqst";
BA_ "SeToolVersion_SIGNAL" SG_ 2483023936 DASActivation_rqst "2";
BA_ "GenSigCycleTime" SG_ 2483023936 DriverSeatBeltSwitch_ISig_4 100;
BA_ "GenSigCycleTimeActive" SG_ 2483023936 DriverSeatBeltSwitch_ISig_4 100;
BA_ "GenSigStartValue" SG_ 2483023936 DriverSeatBeltSwitch_ISig_4 3;
BA_ "GenSigMaxLatency" SG_ 2483023936 DriverSeatBeltSwitch_ISig_4 68;
BA_ "Platform_VMCU1_Sig" SG_ 2483023936 DriverSeatBeltSwitch_ISig_4 1;
BA_ "SeToolAncestorID_SIGNAL" SG_ 2483023936 DriverSeatBeltSwitch_ISig_4 "x0000001D0412FE94";
BA_ "SeToolItemID_SIGNAL" SG_ 2483023936 DriverSeatBeltSwitch_ISig_4 "x0000001D0412FE94";
BA_ "SeToolName_SIGNAL" SG_ 2483023936 DriverSeatBeltSwitch_ISig_4 "DriverSeatBeltSwitch";
BA_ "SeToolVersion_SIGNAL" SG_ 2483023936 DriverSeatBeltSwitch_ISig_4 "1";
BA_ "GenSigCycleTime" SG_ 2483023936 PinCode_stat 100;
BA_ "GenSigCycleTimeActive" SG_ 2483023936 PinCode_stat 100;
BA_ "GenSigStartValue" SG_ 2483023936 PinCode_stat 7;
BA_ "Platform_VMCU1_Sig" SG_ 2483023936 PinCode_stat 1;
BA_ "GenSigCycleTime" SG_ 2483023936 WarmUp_Request 100;
BA_ "GenSigCycleTimeActive" SG_ 2483023936 WarmUp_Request 100;
BA_ "GenSigStartValue" SG_ 2483023936 WarmUp_Request 3;
BA_ "Platform_VMCU1_Sig" SG_ 2483023936 WarmUp_Request 1;
BA_ "GenSigCycleTime" SG_ 2483023936 LKSEnableSwitch_rqst 100;
BA_ "GenSigCycleTimeActive" SG_ 2483023936 LKSEnableSwitch_rqst 100;
BA_ "GenSigStartValue" SG_ 2483023936 LKSEnableSwitch_rqst 3;
BA_ "GenSigMaxLatency" SG_ 2483023936 LKSEnableSwitch_rqst 68;
BA_ "Platform_VMCU1_Sig" SG_ 2483023936 LKSEnableSwitch_rqst 1;
BA_ "SeToolAncestorID_SIGNAL" SG_ 2483023936 LKSEnableSwitch_rqst "x0000001D04158E2E";
BA_ "SeToolItemID_SIGNAL" SG_ 2483023936 LKSEnableSwitch_rqst "x0000001D04158E2E";
BA_ "SeToolName_SIGNAL" SG_ 2483023936 LKSEnableSwitch_rqst "LKSEnableSwitch_rqst";
BA_ "SeToolVersion_SIGNAL" SG_ 2483023936 LKSEnableSwitch_rqst "1";
BA_ "GenSigCycleTime" SG_ 2515579712 AlmClkSnze_LECM_rqst_ID_ISig_4 100;
BA_ "GenSigCycleTimeActive" SG_ 2515579712 AlmClkSnze_LECM_rqst_ID_ISig_4 100;
BA_ "GenSigStartValue" SG_ 2515579712 AlmClkSnze_LECM_rqst_ID_ISig_4 127;
BA_ "Platform_VMCU1_Sig" SG_ 2515579712 AlmClkSnze_LECM_rqst_ID_ISig_4 1;
BA_ "GenSigCycleTime" SG_ 2515579712 AlmClkSetCurAlm_rqst_ID 100;
BA_ "GenSigCycleTimeActive" SG_ 2515579712 AlmClkSetCurAlm_rqst_ID 100;
BA_ "GenSigStartValue" SG_ 2515579712 AlmClkSetCurAlm_rqst_ID 127;
BA_ "Platform_VMCU1_Sig" SG_ 2515579712 AlmClkSetCurAlm_rqst_ID 1;
BA_ "GenSigCycleTime" SG_ 2515579712 AlmClkSnze_LECM_rqst_Action_ISig 100;
BA_ "GenSigCycleTimeActive" SG_ 2515579712 AlmClkSnze_LECM_rqst_Action_ISig 100;
BA_ "GenSigStartValue" SG_ 2515579712 AlmClkSnze_LECM_rqst_Action_ISig 7;
BA_ "Platform_VMCU1_Sig" SG_ 2515579712 AlmClkSnze_LECM_rqst_Action_ISig 1;
BA_ "SystemSignalLongSymbol" SG_ 2515579712 AlmClkSnze_LECM_rqst_Action_ISig "AlmClkSnze_LECM_rqst_Action_ISig_4";
BA_ "GenSigCycleTime" SG_ 2515579712 AlmClkSetCurAlm_rqst_Stat 100;
BA_ "GenSigCycleTimeActive" SG_ 2515579712 AlmClkSetCurAlm_rqst_Stat 100;
BA_ "GenSigStartValue" SG_ 2515579712 AlmClkSetCurAlm_rqst_Stat 3;
BA_ "Platform_VMCU1_Sig" SG_ 2515579712 AlmClkSetCurAlm_rqst_Stat 1;
BA_ "GenSigCycleTime" SG_ 2515579712 AlmClkSetCurAlm_rqst_SetMin 100;
BA_ "GenSigCycleTimeActive" SG_ 2515579712 AlmClkSetCurAlm_rqst_SetMin 100;
BA_ "GenSigStartValue" SG_ 2515579712 AlmClkSetCurAlm_rqst_SetMin 63;
BA_ "Platform_VMCU1_Sig" SG_ 2515579712 AlmClkSetCurAlm_rqst_SetMin 1;
BA_ "GenSigCycleTime" SG_ 2515579712 AlmClkSetCurAlm_rqst_SetHr 100;
BA_ "GenSigCycleTimeActive" SG_ 2515579712 AlmClkSetCurAlm_rqst_SetHr 100;
BA_ "GenSigStartValue" SG_ 2515579712 AlmClkSetCurAlm_rqst_SetHr 31;
BA_ "Platform_VMCU1_Sig" SG_ 2515579712 AlmClkSetCurAlm_rqst_SetHr 1;
BA_ "GenSigCycleTime" SG_ 2515579712 CollSituationHMICtrlRequestVM_IS 100;
BA_ "GenSigCycleTimeActive" SG_ 2515579712 CollSituationHMICtrlRequestVM_IS 100;
BA_ "GenSigStartValue" SG_ 2515579712 CollSituationHMICtrlRequestVM_IS 7;
BA_ "Platform_VMCU1_Sig" SG_ 2515579712 CollSituationHMICtrlRequestVM_IS 1;
BA_ "SystemSignalLongSymbol" SG_ 2515579712 CollSituationHMICtrlRequestVM_IS "CollSituationHMICtrlRequestVM_ISig_4";
BA_ "GenSigCycleTime" SG_ 2515579712 AcCoolantPumpEngagementRequest_I 100;
BA_ "GenSigCycleTimeActive" SG_ 2515579712 AcCoolantPumpEngagementRequest_I 100;
BA_ "GenSigStartValue" SG_ 2515579712 AcCoolantPumpEngagementRequest_I 255;
BA_ "Platform_VMCU1_Sig" SG_ 2515579712 AcCoolantPumpEngagementRequest_I 1;
BA_ "SystemSignalLongSymbol" SG_ 2515579712 AcCoolantPumpEngagementRequest_I "AcCoolantPumpEngagementRequest_ISig_4";
BA_ "GenSigCycleTime" SG_ 2515579712 AlmClkSetCurAlm_rqst_Type 100;
BA_ "GenSigCycleTimeActive" SG_ 2515579712 AlmClkSetCurAlm_rqst_Type 100;
BA_ "GenSigStartValue" SG_ 2515579712 AlmClkSetCurAlm_rqst_Type 7;
BA_ "Platform_VMCU1_Sig" SG_ 2515579712 AlmClkSetCurAlm_rqst_Type 1;
BA_ "GenSigCycleTime" SG_ 2515579712 WRC_Docking_stat_ISig_4 100;
BA_ "GenSigCycleTimeActive" SG_ 2515579712 WRC_Docking_stat_ISig_4 100;
BA_ "GenSigStartValue" SG_ 2515579712 WRC_Docking_stat_ISig_4 3;
BA_ "Platform_VMCU1_Sig" SG_ 2515579712 WRC_Docking_stat_ISig_4 1;
BA_ "GenSigSendType" SG_ 2482995008 LiftAxle1DirectControl_UB_ISig_4 7;
BA_ "Platform_VMCU1_Sig" SG_ 2482995008 LiftAxle1DirectControl_UB_ISig_4 1;
BA_ "GenSigCycleTime" SG_ 2482995008 Regeneration2PosSwitchStatus 100;
BA_ "GenSigCycleTimeActive" SG_ 2482995008 Regeneration2PosSwitchStatus 100;
BA_ "GenSigStartValue" SG_ 2482995008 Regeneration2PosSwitchStatus 3;
BA_ "Platform_VMCU1_Sig" SG_ 2482995008 Regeneration2PosSwitchStatus 1;
BA_ "GenSigCycleTime" SG_ 2482995008 WRCEngineStopRequest_ISig_4 100;
BA_ "GenSigCycleTimeActive" SG_ 2482995008 WRCEngineStopRequest_ISig_4 100;
BA_ "GenSigStartValue" SG_ 2482995008 WRCEngineStopRequest_ISig_4 3;
BA_ "GenSigMaxLatency" SG_ 2482995008 WRCEngineStopRequest_ISig_4 28;
BA_ "NeedsUpdateBit" SG_ 2482995008 WRCEngineStopRequest_ISig_4 1;
BA_ "Platform_VMCU1_Sig" SG_ 2482995008 WRCEngineStopRequest_ISig_4 1;
BA_ "GenSigCycleTime" SG_ 2482995008 LiftAxle1DirectControl_ISig_4 100;
BA_ "GenSigCycleTimeActive" SG_ 2482995008 LiftAxle1DirectControl_ISig_4 100;
BA_ "GenSigStartValue" SG_ 2482995008 LiftAxle1DirectControl_ISig_4 7;
BA_ "NeedsUpdateBit" SG_ 2482995008 LiftAxle1DirectControl_ISig_4 1;
BA_ "Platform_VMCU1_Sig" SG_ 2482995008 LiftAxle1DirectControl_ISig_4 1;
BA_ "GenSigCycleTime" SG_ 2482995008 PanicAlarmFromKeyfob_rqst 100;
BA_ "GenSigCycleTimeActive" SG_ 2482995008 PanicAlarmFromKeyfob_rqst 100;
BA_ "GenSigStartValue" SG_ 2482995008 PanicAlarmFromKeyfob_rqst 3;
BA_ "GenSigMaxLatency" SG_ 2482995008 PanicAlarmFromKeyfob_rqst 66;
BA_ "Platform_VMCU1_Sig" SG_ 2482995008 PanicAlarmFromKeyfob_rqst 1;
BA_ "GenSigCycleTime" SG_ 2482995008 InhibRegenerationSwitch_stat 100;
BA_ "GenSigCycleTimeActive" SG_ 2482995008 InhibRegenerationSwitch_stat 100;
BA_ "GenSigStartValue" SG_ 2482995008 InhibRegenerationSwitch_stat 3;
BA_ "Platform_VMCU1_Sig" SG_ 2482995008 InhibRegenerationSwitch_stat 1;
BA_ "GenSigCycleTime" SG_ 2482995008 ParkingClimate_IndicationCmd_ISi 100;
BA_ "GenSigCycleTimeActive" SG_ 2482995008 ParkingClimate_IndicationCmd_ISi 100;
BA_ "GenSigStartValue" SG_ 2482995008 ParkingClimate_IndicationCmd_ISi 7;
BA_ "Platform_VMCU1_Sig" SG_ 2482995008 ParkingClimate_IndicationCmd_ISi 1;
BA_ "SystemSignalLongSymbol" SG_ 2482995008 ParkingClimate_IndicationCmd_ISi "ParkingClimate_IndicationCmd_ISig_4";
BA_ "GenSigCycleTime" SG_ 2482995008 DriverDoorAjar_stat_ISig_4 100;
BA_ "GenSigCycleTimeActive" SG_ 2482995008 DriverDoorAjar_stat_ISig_4 100;
BA_ "GenSigStartValue" SG_ 2482995008 DriverDoorAjar_stat_ISig_4 7;
BA_ "GenSigMaxLatency" SG_ 2482995008 DriverDoorAjar_stat_ISig_4 66;
BA_ "Platform_VMCU1_Sig" SG_ 2482995008 DriverDoorAjar_stat_ISig_4 1;
BA_ "GenSigCycleTime" SG_ 2482995008 WRCEngineStartRequest_ISig_4 100;
BA_ "GenSigCycleTimeActive" SG_ 2482995008 WRCEngineStartRequest_ISig_4 100;
BA_ "GenSigStartValue" SG_ 2482995008 WRCEngineStartRequest_ISig_4 3;
BA_ "GenSigMaxLatency" SG_ 2482995008 WRCEngineStartRequest_ISig_4 28;
BA_ "NeedsUpdateBit" SG_ 2482995008 WRCEngineStartRequest_ISig_4 1;
BA_ "Platform_VMCU1_Sig" SG_ 2482995008 WRCEngineStartRequest_ISig_4 1;
BA_ "GenSigCycleTime" SG_ 2482995008 RegenerationPushButtonStatus_ISi 100;
BA_ "GenSigCycleTimeActive" SG_ 2482995008 RegenerationPushButtonStatus_ISi 100;
BA_ "GenSigStartValue" SG_ 2482995008 RegenerationPushButtonStatus_ISi 3;
BA_ "Platform_VMCU1_Sig" SG_ 2482995008 RegenerationPushButtonStatus_ISi 1;
BA_ "SystemSignalLongSymbol" SG_ 2482995008 RegenerationPushButtonStatus_ISi "RegenerationPushButtonStatus_ISig_4";
BA_ "GenSigCycleTime" SG_ 2482995008 RegenerationSwitchStatus_ISig_4 100;
BA_ "GenSigCycleTimeActive" SG_ 2482995008 RegenerationSwitchStatus_ISig_4 100;
BA_ "GenSigStartValue" SG_ 2482995008 RegenerationSwitchStatus_ISig_4 7;
BA_ "Platform_VMCU1_Sig" SG_ 2482995008 RegenerationSwitchStatus_ISig_4 1;
BA_ "GenSigCycleTime" SG_ 2482995008 DoorLock_stat_ISig_4 100;
BA_ "GenSigCycleTimeActive" SG_ 2482995008 DoorLock_stat_ISig_4 100;
BA_ "GenSigStartValue" SG_ 2482995008 DoorLock_stat_ISig_4 15;
BA_ "GenSigMaxLatency" SG_ 2482995008 DoorLock_stat_ISig_4 66;
BA_ "Platform_VMCU1_Sig" SG_ 2482995008 DoorLock_stat_ISig_4 1;
BA_ "GenSigSendType" SG_ 2482995008 WRCEngineStartRequest_UB_ISig_4 7;
BA_ "Platform_VMCU1_Sig" SG_ 2482995008 WRCEngineStartRequest_UB_ISig_4 1;
BA_ "GenSigCycleTime" SG_ 2482995008 LuggageAjar_stat_ISig_4 100;
BA_ "GenSigCycleTimeActive" SG_ 2482995008 LuggageAjar_stat_ISig_4 100;
BA_ "GenSigStartValue" SG_ 2482995008 LuggageAjar_stat_ISig_4 7;
BA_ "Platform_VMCU1_Sig" SG_ 2482995008 LuggageAjar_stat_ISig_4 1;
BA_ "GenSigCycleTime" SG_ 2482995008 AlarmStatus_stat_ISig_4 100;
BA_ "GenSigCycleTimeActive" SG_ 2482995008 AlarmStatus_stat_ISig_4 100;
BA_ "GenSigStartValue" SG_ 2482995008 AlarmStatus_stat_ISig_4 15;
BA_ "Platform_VMCU1_Sig" SG_ 2482995008 AlarmStatus_stat_ISig_4 1;
BA_ "GenSigCycleTime" SG_ 2482995008 AlarmTriggeringCause_stat_ISig_4 100;
BA_ "GenSigCycleTimeActive" SG_ 2482995008 AlarmTriggeringCause_stat_ISig_4 100;
BA_ "GenSigStartValue" SG_ 2482995008 AlarmTriggeringCause_stat_ISig_4 15;
BA_ "GenSigMaxLatency" SG_ 2482995008 AlarmTriggeringCause_stat_ISig_4 66;
BA_ "Platform_VMCU1_Sig" SG_ 2482995008 AlarmTriggeringCause_stat_ISig_4 1;
BA_ "GenSigSendType" SG_ 2482995008 DoorsAjar_stat_UB_ISig_4 7;
BA_ "Platform_VMCU1_Sig" SG_ 2482995008 DoorsAjar_stat_UB_ISig_4 1;
BA_ "GenSigCycleTime" SG_ 2482995008 DoorsAjar_stat_ISig_4 100;
BA_ "GenSigCycleTimeActive" SG_ 2482995008 DoorsAjar_stat_ISig_4 100;
BA_ "GenSigStartValue" SG_ 2482995008 DoorsAjar_stat_ISig_4 7;
BA_ "GenSigMaxLatency" SG_ 2482995008 DoorsAjar_stat_ISig_4 66;
BA_ "NeedsUpdateBit" SG_ 2482995008 DoorsAjar_stat_ISig_4 1;
BA_ "Platform_VMCU1_Sig" SG_ 2482995008 DoorsAjar_stat_ISig_4 1;
BA_ "GenSigSendType" SG_ 2482995008 WRCEngineStopRequest_UB_ISig_4 7;
BA_ "Platform_VMCU1_Sig" SG_ 2482995008 WRCEngineStopRequest_UB_ISig_4 1;
BA_ "GenSigCycleTime" SG_ 2482995008 DoorAutoFunction_rqst 100;
BA_ "GenSigCycleTimeActive" SG_ 2482995008 DoorAutoFunction_rqst 100;
BA_ "GenSigStartValue" SG_ 2482995008 DoorAutoFunction_rqst 3;
BA_ "GenSigMaxLatency" SG_ 2482995008 DoorAutoFunction_rqst 66;
BA_ "Platform_VMCU1_Sig" SG_ 2482995008 DoorAutoFunction_rqst 1;
BA_REL_ "GenSigFirstTimeoutTime" BU_SG_REL_ VMCU SG_ 2432641616 FASHapticFeedbackRequest_ISig_4 3000;
BA_REL_ "GenSigTimeoutTime" BU_SG_REL_ VMCU SG_ 2432641616 FASHapticFeedbackRequest_ISig_4 80;
BA_REL_ "GenSigFirstTimeoutTime" BU_SG_REL_ VMCU SG_ 2432641616 FASCurvatureRequest_ISig_4 3000;
BA_REL_ "GenSigTimeoutTime" BU_SG_REL_ VMCU SG_ 2432641616 FASCurvatureRequest_ISig_4 80;
BA_REL_ "GenSigFirstTimeoutTime" BU_SG_REL_ VMCU SG_ 2432641616 FASControlMode_ISig_4 3000;
BA_REL_ "GenSigTimeoutTime" BU_SG_REL_ VMCU SG_ 2432641616 FASControlMode_ISig_4 80;
BA_REL_ "GenSigFirstTimeoutTime" BU_SG_REL_ VMCU SG_ 2432641616 FASExtCtrlMsgChecksum_ISig_4 3000;
BA_REL_ "GenSigTimeoutTime" BU_SG_REL_ VMCU SG_ 2432641616 FASExtCtrlMsgChecksum_ISig_4 80;
BA_REL_ "GenSigFirstTimeoutTime" BU_SG_REL_ VMCU SG_ 2432641616 ReferencePathCurvature_ISig_4 3000;
BA_REL_ "GenSigTimeoutTime" BU_SG_REL_ VMCU SG_ 2432641616 ReferencePathCurvature_ISig_4 80;
BA_REL_ "GenSigFirstTimeoutTime" BU_SG_REL_ VMCU SG_ 2432641616 FASExtCtrlMsgCounter_ISig_4 3000;
BA_REL_ "GenSigTimeoutTime" BU_SG_REL_ VMCU SG_ 2432641616 FASExtCtrlMsgCounter_ISig_4 80;
BA_REL_ "GenSigFirstTimeoutTime" BU_SG_REL_ VMCU SG_ 2432641616 FASRoadWheelAngleRequest_ISig_4 3000;
BA_REL_ "GenSigTimeoutTime" BU_SG_REL_ VMCU SG_ 2432641616 FASRoadWheelAngleRequest_ISig_4 80;
BA_REL_ "GenSigFirstTimeoutTime" BU_SG_REL_ VMCU SG_ 2432640336 GlareFreeArea02_LeftAngle_ISig_4 3000;
BA_REL_ "GenSigTimeoutTime" BU_SG_REL_ VMCU SG_ 2432640336 GlareFreeArea02_LeftAngle_ISig_4 120;
BA_REL_ "GenSigFirstTimeoutTime" BU_SG_REL_ VMCU SG_ 2432640336 GlareFreeArea02_RightAngle_ISig_ 3000;
BA_REL_ "GenSigTimeoutTime" BU_SG_REL_ VMCU SG_ 2432640336 GlareFreeArea02_RightAngle_ISig_ 120;
BA_REL_ "GenSigFirstTimeoutTime" BU_SG_REL_ VMCU SG_ 2432640336 GlareFreeArea02_Distance_ISig_4 3000;
BA_REL_ "GenSigTimeoutTime" BU_SG_REL_ VMCU SG_ 2432640336 GlareFreeArea02_Distance_ISig_4 120;
BA_REL_ "GenSigFirstTimeoutTime" BU_SG_REL_ VMCU SG_ 2432639568 GlareFreeArea01_LeftAngle_ISig_4 3000;
BA_REL_ "GenSigTimeoutTime" BU_SG_REL_ VMCU SG_ 2432639568 GlareFreeArea01_LeftAngle_ISig_4 120;
BA_REL_ "GenSigFirstTimeoutTime" BU_SG_REL_ VMCU SG_ 2432639568 GlareFreeArea03_Distance_ISig_4 3000;
BA_REL_ "GenSigTimeoutTime" BU_SG_REL_ VMCU SG_ 2432639568 GlareFreeArea03_Distance_ISig_4 120;
BA_REL_ "GenSigFirstTimeoutTime" BU_SG_REL_ VMCU SG_ 2432639568 GlareFreeArea03_LeftAngle_ISig_4 3000;
BA_REL_ "GenSigTimeoutTime" BU_SG_REL_ VMCU SG_ 2432639568 GlareFreeArea03_LeftAngle_ISig_4 120;
BA_REL_ "GenSigFirstTimeoutTime" BU_SG_REL_ VMCU SG_ 2432639568 GlareFreeArea03_RightAngle_ISig_ 3000;
BA_REL_ "GenSigTimeoutTime" BU_SG_REL_ VMCU SG_ 2432639568 GlareFreeArea03_RightAngle_ISig_ 120;
BA_REL_ "GenSigFirstTimeoutTime" BU_SG_REL_ VMCU SG_ 2432639568 GlareFreeArea01_Distance_ISig_4 3000;
BA_REL_ "GenSigTimeoutTime" BU_SG_REL_ VMCU SG_ 2432639568 GlareFreeArea01_Distance_ISig_4 120;
BA_REL_ "GenSigFirstTimeoutTime" BU_SG_REL_ VMCU SG_ 2432639568 GlareFreeArea01_RightAngle_ISig_ 3000;
BA_REL_ "GenSigTimeoutTime" BU_SG_REL_ VMCU SG_ 2432639568 GlareFreeArea01_RightAngle_ISig_ 120;
BA_REL_ "GenSigFirstTimeoutTime" BU_SG_REL_ VMCU SG_ 2499772240 VisionLight_stat 3000;
BA_REL_ "GenSigTimeoutTime" BU_SG_REL_ VMCU SG_ 2499772240 VisionLight_stat 600;
BA_REL_ "GenSigFirstTimeoutTime" BU_SG_REL_ BBM SG_ 2499772240 BBSteeringStatus_ISig_4 3000;
BA_REL_ "GenSigTimeoutTime" BU_SG_REL_ BBM SG_ 2499772240 BBSteeringStatus_ISig_4 600;
BA_REL_ "GenSigFirstTimeoutTime" BU_SG_REL_ TECU SG_ 2499772240 ACCiSeeDistanceGap 3000;
BA_REL_ "GenSigTimeoutTime" BU_SG_REL_ TECU SG_ 2499772240 ACCiSeeDistanceGap 600;
BA_REL_ "GenSigFirstTimeoutTime" BU_SG_REL_ HMIIOM SG_ 2466246992 ForwardLookingCameraStatus_ISig_ 3000;
BA_REL_ "GenSigTimeoutTime" BU_SG_REL_ HMIIOM SG_ 2466246992 ForwardLookingCameraStatus_ISig_ 240;
BA_REL_ "GenSigFirstTimeoutTime" BU_SG_REL_ EMS SG_ 2466246992 XARDACU_ControlMode 3000;
BA_REL_ "GenSigTimeoutTime" BU_SG_REL_ EMS SG_ 2466246992 XARDACU_ControlMode 240;
BA_REL_ "GenSigFirstTimeoutTime" BU_SG_REL_ TECU SG_ 2466246992 XARDACU_ControlMode 3000;
BA_REL_ "GenSigTimeoutTime" BU_SG_REL_ TECU SG_ 2466246992 XARDACU_ControlMode 240;
BA_REL_ "GenSigFirstTimeoutTime" BU_SG_REL_ TECU SG_ 2466246992 ACCiRollInhibit 3000;
BA_REL_ "GenSigTimeoutTime" BU_SG_REL_ TECU SG_ 2466246992 ACCiRollInhibit 240;
BA_REL_ "GenSigFirstTimeoutTime" BU_SG_REL_ HMIIOM SG_ 2466246992 ACCTargetRelLongSpeed 3000;
BA_REL_ "GenSigTimeoutTime" BU_SG_REL_ HMIIOM SG_ 2466246992 ACCTargetRelLongSpeed 240;
BA_REL_ "GenSigFirstTimeoutTime" BU_SG_REL_ HMIIOM SG_ 2466246992 CMReducedAbilityStatus_ISig_4 3000;
BA_REL_ "GenSigTimeoutTime" BU_SG_REL_ HMIIOM SG_ 2466246992 CMReducedAbilityStatus_ISig_4 240;
BA_REL_ "GenSigFirstTimeoutTime" BU_SG_REL_ HMIIOM SG_ 2466246992 LPOSBlocked_ISig_4 3000;
BA_REL_ "GenSigTimeoutTime" BU_SG_REL_ HMIIOM SG_ 2466246992 LPOSBlocked_ISig_4 240;
BA_REL_ "GenSigFirstTimeoutTime" BU_SG_REL_ VMCU SG_ 2466246992 CollisionSituationAliveAck 3000;
BA_REL_ "GenSigTimeoutTime" BU_SG_REL_ VMCU SG_ 2466246992 CollisionSituationAliveAck 240;
BA_REL_ "GenSigFirstTimeoutTime" BU_SG_REL_ HMIIOM SG_ 2466246992 ForwardLookingRadarStatus_ISig_4 3000;
BA_REL_ "GenSigTimeoutTime" BU_SG_REL_ HMIIOM SG_ 2466246992 ForwardLookingRadarStatus_ISig_4 240;
BA_REL_ "GenSigFirstTimeoutTime" BU_SG_REL_ VMCU SG_ 2466246992 XPRRequest_CM_ISig_4 3000;
BA_REL_ "GenSigTimeoutTime" BU_SG_REL_ VMCU SG_ 2466246992 XPRRequest_CM_ISig_4 240;
BA_REL_ "GenSigFirstTimeoutTime" BU_SG_REL_ EMS SG_ 2466246992 XARDACU_AccelDemand 3000;
BA_REL_ "GenSigTimeoutTime" BU_SG_REL_ EMS SG_ 2466246992 XARDACU_AccelDemand 240;
BA_REL_ "GenSigFirstTimeoutTime" BU_SG_REL_ TECU SG_ 2466246992 XARDACU_AccelDemand 3000;
BA_REL_ "GenSigTimeoutTime" BU_SG_REL_ TECU SG_ 2466246992 XARDACU_AccelDemand 240;
BA_REL_ "GenSigFirstTimeoutTime" BU_SG_REL_ VMCU SG_ 2466246992 CollSituationHazardLightReq 3000;
BA_REL_ "GenSigTimeoutTime" BU_SG_REL_ VMCU SG_ 2466246992 CollSituationHazardLightReq 240;
BA_REL_ "GenSigFirstTimeoutTime" BU_SG_REL_ HMIIOM SG_ 2432690512 PathDeviationDriverAlert_ISig_4 3000;
BA_REL_ "GenSigTimeoutTime" BU_SG_REL_ HMIIOM SG_ 2432690512 PathDeviationDriverAlert_ISig_4 240;
BA_REL_ "GenSigFirstTimeoutTime" BU_SG_REL_ VMCU SG_ 2432690512 PathDeviationDriverAlert_ISig_4 3000;
BA_REL_ "GenSigTimeoutTime" BU_SG_REL_ VMCU SG_ 2432690512 PathDeviationDriverAlert_ISig_4 240;
BA_REL_ "GenSigFirstTimeoutTime" BU_SG_REL_ TECU SG_ 2432690512 CM_DisengageDrivelineRequest 3000;
BA_REL_ "GenSigTimeoutTime" BU_SG_REL_ TECU SG_ 2432690512 CM_DisengageDrivelineRequest 240;
BA_REL_ "GenSigFirstTimeoutTime" BU_SG_REL_ VMCU SG_ 2432690512 ACCBrakeRequestStatus 3000;
BA_REL_ "GenSigTimeoutTime" BU_SG_REL_ VMCU SG_ 2432690512 ACCBrakeRequestStatus 240;
BA_REL_ "GenSigFirstTimeoutTime" BU_SG_REL_ HMIIOM SG_ 2432690512 FrontalCollisionDriverAlert_ISig 3000;
BA_REL_ "GenSigTimeoutTime" BU_SG_REL_ HMIIOM SG_ 2432690512 FrontalCollisionDriverAlert_ISig 240;
BA_REL_ "GenSigFirstTimeoutTime" BU_SG_REL_ VMCU SG_ 2432690512 FrontalCollisionDriverAlert_ISig 3000;
BA_REL_ "GenSigTimeoutTime" BU_SG_REL_ VMCU SG_ 2432690512 FrontalCollisionDriverAlert_ISig 120;
BA_REL_ "GenSigFirstTimeoutTime" BU_SG_REL_ HMIIOM SG_ 2432690512 ACCBrakeCapacityWarning_ISig_4 3000;
BA_REL_ "GenSigTimeoutTime" BU_SG_REL_ HMIIOM SG_ 2432690512 ACCBrakeCapacityWarning_ISig_4 240;
BA_REL_ "GenSigFirstTimeoutTime" BU_SG_REL_ HMIIOM SG_ 2432690512 ACC_SGOFaultCondStat_SeatBelt_IS 3000;
BA_REL_ "GenSigTimeoutTime" BU_SG_REL_ HMIIOM SG_ 2432690512 ACC_SGOFaultCondStat_SeatBelt_IS 240;
BA_REL_ "GenSigFirstTimeoutTime" BU_SG_REL_ CIOM SG_ 2432690512 CM_Status_ISig_4 3000;
BA_REL_ "GenSigTimeoutTime" BU_SG_REL_ CIOM SG_ 2432690512 CM_Status_ISig_4 240;
BA_REL_ "GenSigFirstTimeoutTime" BU_SG_REL_ VMCU SG_ 2432690512 CM_Status_ISig_4 3000;
BA_REL_ "GenSigTimeoutTime" BU_SG_REL_ VMCU SG_ 2432690512 CM_Status_ISig_4 240;
BA_REL_ "GenSigFirstTimeoutTime" BU_SG_REL_ HMIIOM SG_ 2432690512 CM_Status_ISig_4 3000;
BA_REL_ "GenSigTimeoutTime" BU_SG_REL_ HMIIOM SG_ 2432690512 CM_Status_ISig_4 240;
BA_REL_ "GenSigFirstTimeoutTime" BU_SG_REL_ HMIIOM SG_ 2432690512 DASApplicationStatus_ISig_4 3000;
BA_REL_ "GenSigTimeoutTime" BU_SG_REL_ HMIIOM SG_ 2432690512 DASApplicationStatus_ISig_4 240;
BA_REL_ "GenSigFirstTimeoutTime" BU_SG_REL_ VMCU SG_ 2432690512 DASApplicationStatus_ISig_4 3000;
BA_REL_ "GenSigTimeoutTime" BU_SG_REL_ VMCU SG_ 2432690512 DASApplicationStatus_ISig_4 120;
BA_REL_ "GenSigFirstTimeoutTime" BU_SG_REL_ CIOM SG_ 2432690512 DASApplicationStatus_ISig_4 3000;
BA_REL_ "GenSigTimeoutTime" BU_SG_REL_ CIOM SG_ 2432690512 DASApplicationStatus_ISig_4 240;
BA_REL_ "GenSigFirstTimeoutTime" BU_SG_REL_ VMCU SG_ 2432690512 ACC_Status_ISig_4 3000;
BA_REL_ "GenSigTimeoutTime" BU_SG_REL_ VMCU SG_ 2432690512 ACC_Status_ISig_4 240;
BA_REL_ "GenSigFirstTimeoutTime" BU_SG_REL_ HMIIOM SG_ 2432690512 ACC_Status_ISig_4 3000;
BA_REL_ "GenSigTimeoutTime" BU_SG_REL_ HMIIOM SG_ 2432690512 ACC_Status_ISig_4 240;
BA_REL_ "GenSigFirstTimeoutTime" BU_SG_REL_ TECU SG_ 2432690512 ACC_Status_ISig_4 3000;
BA_REL_ "GenSigTimeoutTime" BU_SG_REL_ TECU SG_ 2432690512 ACC_Status_ISig_4 240;
BA_REL_ "GenSigFirstTimeoutTime" BU_SG_REL_ CIOM SG_ 2432690512 LKSApplicationStatus_ISig_4 3000;
BA_REL_ "GenSigTimeoutTime" BU_SG_REL_ CIOM SG_ 2432690512 LKSApplicationStatus_ISig_4 240;
BA_REL_ "GenSigFirstTimeoutTime" BU_SG_REL_ VMCU SG_ 2432690512 LKSApplicationStatus_ISig_4 3000;
BA_REL_ "GenSigTimeoutTime" BU_SG_REL_ VMCU SG_ 2432690512 LKSApplicationStatus_ISig_4 120;
BA_REL_ "GenSigFirstTimeoutTime" BU_SG_REL_ HMIIOM SG_ 2432690512 LKSApplicationStatus_ISig_4 3000;
BA_REL_ "GenSigTimeoutTime" BU_SG_REL_ HMIIOM SG_ 2432690512 LKSApplicationStatus_ISig_4 240;
BA_REL_ "GenSigFirstTimeoutTime" BU_SG_REL_ HMIIOM SG_ 2432690512 LCSSystemStatus 3000;
BA_REL_ "GenSigTimeoutTime" BU_SG_REL_ HMIIOM SG_ 2432690512 LCSSystemStatus 240;
BA_REL_ "GenSigFirstTimeoutTime" BU_SG_REL_ CIOM SG_ 2432690512 LCSSystemStatus 3000;
BA_REL_ "GenSigTimeoutTime" BU_SG_REL_ CIOM SG_ 2432690512 LCSSystemStatus 240;
BA_REL_ "GenSigFirstTimeoutTime" BU_SG_REL_ HMIIOM SG_ 2432690512 ACC_SGOFaultCondStat_SigStat_ISi 3000;
BA_REL_ "GenSigTimeoutTime" BU_SG_REL_ HMIIOM SG_ 2432690512 ACC_SGOFaultCondStat_SigStat_ISi 240;
BA_REL_ "GenSigFirstTimeoutTime" BU_SG_REL_ HMIIOM SG_ 2432690512 ACC_SGOFaultCondStat_Target_ISig 3000;
BA_REL_ "GenSigTimeoutTime" BU_SG_REL_ HMIIOM SG_ 2432690512 ACC_SGOFaultCondStat_Target_ISig 240;
BA_REL_ "GenSigFirstTimeoutTime" BU_SG_REL_ HMIIOM SG_ 2432690512 FCW_Status_ISig_4 3000;
BA_REL_ "GenSigTimeoutTime" BU_SG_REL_ HMIIOM SG_ 2432690512 FCW_Status_ISig_4 240;
BA_REL_ "GenSigFirstTimeoutTime" BU_SG_REL_ CIOM SG_ 2432690512 FCW_Status_ISig_4 3000;
BA_REL_ "GenSigTimeoutTime" BU_SG_REL_ CIOM SG_ 2432690512 FCW_Status_ISig_4 240;
BA_REL_ "GenSigFirstTimeoutTime" BU_SG_REL_ VMCU SG_ 2432690512 FCW_Status_ISig_4 3000;
BA_REL_ "GenSigTimeoutTime" BU_SG_REL_ VMCU SG_ 2432690512 FCW_Status_ISig_4 120;
BA_REL_ "GenSigFirstTimeoutTime" BU_SG_REL_ HMIIOM SG_ 2432690512 DriverImpairedDriverAlert_ISig_4 3000;
BA_REL_ "GenSigTimeoutTime" BU_SG_REL_ HMIIOM SG_ 2432690512 DriverImpairedDriverAlert_ISig_4 240;
BA_REL_ "GenSigFirstTimeoutTime" BU_SG_REL_ VMCU SG_ 2432690512 DriverImpairedDriverAlert_ISig_4 3000;
BA_REL_ "GenSigTimeoutTime" BU_SG_REL_ VMCU SG_ 2432690512 DriverImpairedDriverAlert_ISig_4 240;
BA_REL_ "GenSigFirstTimeoutTime" BU_SG_REL_ HMIIOM SG_ 2432690512 DriverVigilanceLevel_ISig_4 3000;
BA_REL_ "GenSigTimeoutTime" BU_SG_REL_ HMIIOM SG_ 2432690512 DriverVigilanceLevel_ISig_4 240;
BA_REL_ "GenSigFirstTimeoutTime" BU_SG_REL_ VMCU SG_ 2432690512 DriverVigilanceLevel_ISig_4 3000;
BA_REL_ "GenSigTimeoutTime" BU_SG_REL_ VMCU SG_ 2432690512 DriverVigilanceLevel_ISig_4 240;
BA_REL_ "GenSigFirstTimeoutTime" BU_SG_REL_ TECU SG_ 2432690512 ACCForwardVehicleSpeed_ISig_4 3000;
BA_REL_ "GenSigTimeoutTime" BU_SG_REL_ TECU SG_ 2432690512 ACCForwardVehicleSpeed_ISig_4 240;
BA_REL_ "GenSigFirstTimeoutTime" BU_SG_REL_ HMIIOM SG_ 2432690512 ACCForwardVehicleSpeed_ISig_4 3000;
BA_REL_ "GenSigTimeoutTime" BU_SG_REL_ HMIIOM SG_ 2432690512 ACCForwardVehicleSpeed_ISig_4 240;
BA_REL_ "GenSigFirstTimeoutTime" BU_SG_REL_ HMIIOM SG_ 2432690512 ACC_SGOFaultCondStat_Door_ISig_4 3000;
BA_REL_ "GenSigTimeoutTime" BU_SG_REL_ HMIIOM SG_ 2432690512 ACC_SGOFaultCondStat_Door_ISig_4 240;
BA_REL_ "GenSigFirstTimeoutTime" BU_SG_REL_ HMIIOM SG_ 2432690512 ACCTargetDetected_ISig_4 3000;
BA_REL_ "GenSigTimeoutTime" BU_SG_REL_ HMIIOM SG_ 2432690512 ACCTargetDetected_ISig_4 240;
BA_REL_ "GenSigFirstTimeoutTime" BU_SG_REL_ TECU SG_ 2432690512 ACCForwardVehicleDistance_ISig_4 3000;
BA_REL_ "GenSigTimeoutTime" BU_SG_REL_ TECU SG_ 2432690512 ACCForwardVehicleDistance_ISig_4 240;
BA_REL_ "GenSigFirstTimeoutTime" BU_SG_REL_ HMIIOM SG_ 2432690512 ACCForwardVehicleDistance_ISig_4 3000;
BA_REL_ "GenSigTimeoutTime" BU_SG_REL_ HMIIOM SG_ 2432690512 ACCForwardVehicleDistance_ISig_4 240;
BA_REL_ "GenSigFirstTimeoutTime" BU_SG_REL_ CIOM SG_ 2432690512 LKSCorrectiveSteeringStatus 3000;
BA_REL_ "GenSigTimeoutTime" BU_SG_REL_ CIOM SG_ 2432690512 LKSCorrectiveSteeringStatus 120;
BA_REL_ "GenSigFirstTimeoutTime" BU_SG_REL_ HMIIOM SG_ 2432690512 LKSCorrectiveSteeringStatus 3000;
BA_REL_ "GenSigTimeoutTime" BU_SG_REL_ HMIIOM SG_ 2432690512 LKSCorrectiveSteeringStatus 120;
BA_REL_ "GenSigFirstTimeoutTime" BU_SG_REL_ HMIIOM SG_ 2432690512 ACC_SGOFaultCondStat_Other_ISig_ 3000;
BA_REL_ "GenSigTimeoutTime" BU_SG_REL_ HMIIOM SG_ 2432690512 ACC_SGOFaultCondStat_Other_ISig_ 240;
BA_REL_ "GenSigFirstTimeoutTime" BU_SG_REL_ HMIIOM SG_ 2432690512 LCSSoundSettingStatus 3000;
BA_REL_ "GenSigTimeoutTime" BU_SG_REL_ HMIIOM SG_ 2432690512 LCSSoundSettingStatus 240;
BA_REL_ "GenSigFirstTimeoutTime" BU_SG_REL_ HMIIOM SG_ 2432690512 ACC_SGOFaultCondStat_Speed_ISig_ 3000;
BA_REL_ "GenSigTimeoutTime" BU_SG_REL_ HMIIOM SG_ 2432690512 ACC_SGOFaultCondStat_Speed_ISig_ 240;
BA_REL_ "GenSigFirstTimeoutTime" BU_SG_REL_ DACU SG_ 2432685120 LKSCSEnableSwitch_rqst 3000;
BA_REL_ "GenSigTimeoutTime" BU_SG_REL_ DACU SG_ 2432685120 LKSCSEnableSwitch_rqst 240;
BA_REL_ "GenSigFirstTimeoutTime" BU_SG_REL_ HMIIOM SG_ 2566078272 RollerBenchModeRequest_2 3000;
BA_REL_ "GenSigTimeoutTime" BU_SG_REL_ HMIIOM SG_ 2566078272 RollerBenchModeRequest_2 600;
BA_REL_ "GenSigFirstTimeoutTime" BU_SG_REL_ VMCU SG_ 2566078272 TrafficAccidentHazardLightRqst_I 3000;
BA_REL_ "GenSigTimeoutTime" BU_SG_REL_ VMCU SG_ 2566078272 TrafficAccidentHazardLightRqst_I 600;
BA_REL_ "GenSigFirstTimeoutTime" BU_SG_REL_ TECU SG_ 2566078272 GearboxUnlockAuth_stat 3000;
BA_REL_ "GenSigTimeoutTime" BU_SG_REL_ TECU SG_ 2566078272 GearboxUnlockAuth_stat 600;
BA_REL_ "GenSigFirstTimeoutTime" BU_SG_REL_ HMIIOM SG_ 2566078272 InhibRegeneration_ButtonStat 3000;
BA_REL_ "GenSigTimeoutTime" BU_SG_REL_ HMIIOM SG_ 2566078272 InhibRegeneration_ButtonStat 600;
BA_REL_ "GenSigFirstTimeoutTime" BU_SG_REL_ BBM SG_ 2482978624 TipperUpDownRequest_ISig_4 3000;
BA_REL_ "GenSigTimeoutTime" BU_SG_REL_ BBM SG_ 2482978624 TipperUpDownRequest_ISig_4 500;
BA_REL_ "GenSigFirstTimeoutTime" BU_SG_REL_ VMCU SG_ 2482978624 LoadDistributionRequested_ISig_4 3000;
BA_REL_ "GenSigTimeoutTime" BU_SG_REL_ VMCU SG_ 2482978624 LoadDistributionRequested_ISig_4 500;
BA_REL_ "GenSigFirstTimeoutTime" BU_SG_REL_ BBM SG_ 2482978624 TipperTailGateRequest_ISig_4 3000;
BA_REL_ "GenSigTimeoutTime" BU_SG_REL_ BBM SG_ 2482978624 TipperTailGateRequest_ISig_4 500;
BA_REL_ "GenSigFirstTimeoutTime" BU_SG_REL_ BBM SG_ 2482978624 TipperTippingBodySelection_ISig_ 3000;
BA_REL_ "GenSigTimeoutTime" BU_SG_REL_ BBM SG_ 2482978624 TipperTippingBodySelection_ISig_ 500;
BA_REL_ "GenSigFirstTimeoutTime" BU_SG_REL_ BBM SG_ 2482978624 TipperEmergencyStop_ISig_4 3000;
BA_REL_ "GenSigTimeoutTime" BU_SG_REL_ BBM SG_ 2482978624 TipperEmergencyStop_ISig_4 500;
BA_REL_ "GenSigFirstTimeoutTime" BU_SG_REL_ BBM SG_ 2482978624 ExtraBbWrcWatchdog_ISig_4 3000;
BA_REL_ "GenSigTimeoutTime" BU_SG_REL_ BBM SG_ 2482978624 ExtraBbWrcWatchdog_ISig_4 500;
BA_REL_ "GenSigFirstTimeoutTime" BU_SG_REL_ VMCU SG_ 2482978624 AutoFrontWheelDriveDrvReq 3000;
BA_REL_ "GenSigTimeoutTime" BU_SG_REL_ VMCU SG_ 2482978624 AutoFrontWheelDriveDrvReq 300;
BA_REL_ "GenSigFirstTimeoutTime" BU_SG_REL_ DACU SG_ 2482978624 FrontalCollisionAccidentStatus_I 3000;
BA_REL_ "GenSigTimeoutTime" BU_SG_REL_ DACU SG_ 2482978624 FrontalCollisionAccidentStatus_I 300;
BA_REL_ "GenSigFirstTimeoutTime" BU_SG_REL_ VMCU SG_ 2482978624 ShortStopHeater_cmd_ISig_4 3000;
BA_REL_ "GenSigTimeoutTime" BU_SG_REL_ VMCU SG_ 2482978624 ShortStopHeater_cmd_ISig_4 300;
BA_REL_ "GenSigFirstTimeoutTime" BU_SG_REL_ BBM SG_ 2482978624 TailLiftMotionRequest_ISig_4 3000;
BA_REL_ "GenSigTimeoutTime" BU_SG_REL_ BBM SG_ 2482978624 TailLiftMotionRequest_ISig_4 500;
BA_REL_ "GenSigFirstTimeoutTime" BU_SG_REL_ BBM SG_ 2482978624 TipperShakerRequest_ISig_4 3000;
BA_REL_ "GenSigTimeoutTime" BU_SG_REL_ BBM SG_ 2482978624 TipperShakerRequest_ISig_4 500;
BA_REL_ "GenSigFirstTimeoutTime" BU_SG_REL_ BBM SG_ 2482978624 TipperTarpaulinRequest_ISig_4 3000;
BA_REL_ "GenSigTimeoutTime" BU_SG_REL_ BBM SG_ 2482978624 TipperTarpaulinRequest_ISig_4 500;
BA_REL_ "GenSigFirstTimeoutTime" BU_SG_REL_ HMIIOM SG_ 2482978624 ExtraHeating_status_ISig_4 3000;
BA_REL_ "GenSigTimeoutTime" BU_SG_REL_ HMIIOM SG_ 2482978624 ExtraHeating_status_ISig_4 300;
BA_REL_ "GenSigFirstTimeoutTime" BU_SG_REL_ HMIIOM SG_ 2499801341 EngineTimer_stat_Timer3StartDay_ 3000;
BA_REL_ "GenSigTimeoutTime" BU_SG_REL_ HMIIOM SG_ 2499801341 EngineTimer_stat_Timer3StartDay_ 500;
BA_REL_ "GenSigFirstTimeoutTime" BU_SG_REL_ HMIIOM SG_ 2499801341 EngineTimer_stat_Timer3_Status_I 3000;
BA_REL_ "GenSigTimeoutTime" BU_SG_REL_ HMIIOM SG_ 2499801341 EngineTimer_stat_Timer3_Status_I 500;
BA_REL_ "GenSigFirstTimeoutTime" BU_SG_REL_ HMIIOM SG_ 2499801341 EngineTimer_stat_Timer3Minutes_I 3000;
BA_REL_ "GenSigTimeoutTime" BU_SG_REL_ HMIIOM SG_ 2499801341 EngineTimer_stat_Timer3Minutes_I 500;
BA_REL_ "GenSigFirstTimeoutTime" BU_SG_REL_ HMIIOM SG_ 2499801341 EngineTimer_stat_Timer3Hours_ISi 3000;
BA_REL_ "GenSigTimeoutTime" BU_SG_REL_ HMIIOM SG_ 2499801341 EngineTimer_stat_Timer3Hours_ISi 500;
BA_REL_ "GenSigFirstTimeoutTime" BU_SG_REL_ HMIIOM SG_ 2499801341 EngineTimer_stat_Timer3Recurr_IS 3000;
BA_REL_ "GenSigTimeoutTime" BU_SG_REL_ HMIIOM SG_ 2499801341 EngineTimer_stat_Timer3Recurr_IS 500;
BA_REL_ "GenSigFirstTimeoutTime" BU_SG_REL_ HMIIOM SG_ 2499801341 EngineTimer_stat_Timer1Hours_ISi 3000;
BA_REL_ "GenSigTimeoutTime" BU_SG_REL_ HMIIOM SG_ 2499801341 EngineTimer_stat_Timer1Hours_ISi 500;
BA_REL_ "GenSigFirstTimeoutTime" BU_SG_REL_ HMIIOM SG_ 2499801341 EngineTimer_stat_Timer2Hours_ISi 3000;
BA_REL_ "GenSigTimeoutTime" BU_SG_REL_ HMIIOM SG_ 2499801341 EngineTimer_stat_Timer2Hours_ISi 500;
BA_REL_ "GenSigFirstTimeoutTime" BU_SG_REL_ HMIIOM SG_ 2499801341 EngineTimer_stat_Timer2StartDay_ 3000;
BA_REL_ "GenSigTimeoutTime" BU_SG_REL_ HMIIOM SG_ 2499801341 EngineTimer_stat_Timer2StartDay_ 500;
BA_REL_ "GenSigFirstTimeoutTime" BU_SG_REL_ HMIIOM SG_ 2499801341 EngineTimer_stat_Timer1Recurr_IS 3000;
BA_REL_ "GenSigTimeoutTime" BU_SG_REL_ HMIIOM SG_ 2499801341 EngineTimer_stat_Timer1Recurr_IS 500;
BA_REL_ "GenSigFirstTimeoutTime" BU_SG_REL_ HMIIOM SG_ 2499801341 EngineTimer_stat_Timer2Recurr_IS 3000;
BA_REL_ "GenSigTimeoutTime" BU_SG_REL_ HMIIOM SG_ 2499801341 EngineTimer_stat_Timer2Recurr_IS 500;
BA_REL_ "GenSigFirstTimeoutTime" BU_SG_REL_ HMIIOM SG_ 2499801341 EngineTimer_stat_Timer1Minutes_I 3000;
BA_REL_ "GenSigTimeoutTime" BU_SG_REL_ HMIIOM SG_ 2499801341 EngineTimer_stat_Timer1Minutes_I 500;
BA_REL_ "GenSigFirstTimeoutTime" BU_SG_REL_ HMIIOM SG_ 2499801341 EngineTimer_stat_Timer1StartDay_ 3000;
BA_REL_ "GenSigTimeoutTime" BU_SG_REL_ HMIIOM SG_ 2499801341 EngineTimer_stat_Timer1StartDay_ 500;
BA_REL_ "GenSigFirstTimeoutTime" BU_SG_REL_ HMIIOM SG_ 2499801341 EngineTimer_stat_Timer2_Status_I 3000;
BA_REL_ "GenSigTimeoutTime" BU_SG_REL_ HMIIOM SG_ 2499801341 EngineTimer_stat_Timer2_Status_I 500;
BA_REL_ "GenSigFirstTimeoutTime" BU_SG_REL_ HMIIOM SG_ 2499801341 EngineTimer_stat_Timer2Minutes_I 3000;
BA_REL_ "GenSigTimeoutTime" BU_SG_REL_ HMIIOM SG_ 2499801341 EngineTimer_stat_Timer2Minutes_I 500;
BA_REL_ "GenSigFirstTimeoutTime" BU_SG_REL_ HMIIOM SG_ 2499801341 EngineTimer_stat_Timer1_Status_I 3000;
BA_REL_ "GenSigTimeoutTime" BU_SG_REL_ HMIIOM SG_ 2499801341 EngineTimer_stat_Timer1_Status_I 500;
BA_REL_ "GenSigFirstTimeoutTime" BU_SG_REL_ HMIIOM SG_ 2498741568 WindscreenDefrostInd_cmd_ISig_4 3000;
BA_REL_ "GenSigTimeoutTime" BU_SG_REL_ HMIIOM SG_ 2498741568 WindscreenDefrostInd_cmd_ISig_4 570;
BA_REL_ "GenSigFirstTimeoutTime" BU_SG_REL_ EMS SG_ 2498741568 ACCoolingFanSpeedRequest 3000;
BA_REL_ "GenSigTimeoutTime" BU_SG_REL_ EMS SG_ 2498741568 ACCoolingFanSpeedRequest 570;
BA_REL_ "GenSigFirstTimeoutTime" BU_SG_REL_ HMIIOM SG_ 2498741568 AutoMode_IndicationCmd_ISig_4 3000;
BA_REL_ "GenSigTimeoutTime" BU_SG_REL_ HMIIOM SG_ 2498741568 AutoMode_IndicationCmd_ISig_4 570;
BA_REL_ "GenSigFirstTimeoutTime" BU_SG_REL_ VMCU SG_ 2498741568 CabTilt_rqst 3000;
BA_REL_ "GenSigTimeoutTime" BU_SG_REL_ VMCU SG_ 2498741568 CabTilt_rqst 570;
BA_REL_ "GenSigFirstTimeoutTime" BU_SG_REL_ HMIIOM SG_ 2498741568 ACdisplayIndication_Cmd_ISig_4 3000;
BA_REL_ "GenSigTimeoutTime" BU_SG_REL_ HMIIOM SG_ 2498741568 ACdisplayIndication_Cmd_ISig_4 570;
BA_REL_ "GenSigFirstTimeoutTime" BU_SG_REL_ HMIIOM SG_ 2498741568 TemperatureRqstIndication_cmd_IS 3000;
BA_REL_ "GenSigTimeoutTime" BU_SG_REL_ HMIIOM SG_ 2498741568 TemperatureRqstIndication_cmd_IS 570;
BA_REL_ "GenSigFirstTimeoutTime" BU_SG_REL_ BBM SG_ 2498741568 Pto3CabRequest 3000;
BA_REL_ "GenSigTimeoutTime" BU_SG_REL_ BBM SG_ 2498741568 Pto3CabRequest 570;
BA_REL_ "GenSigFirstTimeoutTime" BU_SG_REL_ VMCU SG_ 2498741568 Pto3CabRequest 3000;
BA_REL_ "GenSigTimeoutTime" BU_SG_REL_ VMCU SG_ 2498741568 Pto3CabRequest 570;
BA_REL_ "GenSigFirstTimeoutTime" BU_SG_REL_ VMCU SG_ 2498741568 Pto4CabRequest 3000;
BA_REL_ "GenSigTimeoutTime" BU_SG_REL_ VMCU SG_ 2498741568 Pto4CabRequest 570;
BA_REL_ "GenSigFirstTimeoutTime" BU_SG_REL_ BBM SG_ 2498741568 Pto4CabRequest 3000;
BA_REL_ "GenSigTimeoutTime" BU_SG_REL_ BBM SG_ 2498741568 Pto4CabRequest 600;
BA_REL_ "GenSigFirstTimeoutTime" BU_SG_REL_ HMIIOM SG_ 2498741568 SRSAirbagStatus_ISig_4 3000;
BA_REL_ "GenSigTimeoutTime" BU_SG_REL_ HMIIOM SG_ 2498741568 SRSAirbagStatus_ISig_4 570;
BA_REL_ "GenSigFirstTimeoutTime" BU_SG_REL_ VMCU SG_ 2498741568 SRSAirbagStatus_ISig_4 3000;
BA_REL_ "GenSigTimeoutTime" BU_SG_REL_ VMCU SG_ 2498741568 SRSAirbagStatus_ISig_4 570;
BA_REL_ "GenSigFirstTimeoutTime" BU_SG_REL_ HMIIOM SG_ 2498741568 Area_9level_Indication_cmd_ISig_ 3000;
BA_REL_ "GenSigTimeoutTime" BU_SG_REL_ HMIIOM SG_ 2498741568 Area_9level_Indication_cmd_ISig_ 570;
BA_REL_ "GenSigFirstTimeoutTime" BU_SG_REL_ HMIIOM SG_ 2498741568 AutoDefogIndication_Cmd_ISig_4 3000;
BA_REL_ "GenSigTimeoutTime" BU_SG_REL_ HMIIOM SG_ 2498741568 AutoDefogIndication_Cmd_ISig_4 570;
BA_REL_ "GenSigFirstTimeoutTime" BU_SG_REL_ VMCU SG_ 2498741568 FrontLidAjar_Stat 3000;
BA_REL_ "GenSigTimeoutTime" BU_SG_REL_ VMCU SG_ 2498741568 FrontLidAjar_Stat 570;
BA_REL_ "GenSigFirstTimeoutTime" BU_SG_REL_ HMIIOM SG_ 2498741568 ParkingHeaterCleaning_Rqst_ISig_ 3000;
BA_REL_ "GenSigTimeoutTime" BU_SG_REL_ HMIIOM SG_ 2498741568 ParkingHeaterCleaning_Rqst_ISig_ 570;
BA_REL_ "GenSigFirstTimeoutTime" BU_SG_REL_ BBM SG_ 2498741568 Pto2CabRequest 3000;
BA_REL_ "GenSigTimeoutTime" BU_SG_REL_ BBM SG_ 2498741568 Pto2CabRequest 570;
BA_REL_ "GenSigFirstTimeoutTime" BU_SG_REL_ VMCU SG_ 2498741568 Pto2CabRequest 3000;
BA_REL_ "GenSigTimeoutTime" BU_SG_REL_ VMCU SG_ 2498741568 Pto2CabRequest 570;
BA_REL_ "GenSigFirstTimeoutTime" BU_SG_REL_ HMIIOM SG_ 2498741568 AutoBlowerLevelIndication_Cmd_IS 3000;
BA_REL_ "GenSigTimeoutTime" BU_SG_REL_ HMIIOM SG_ 2498741568 AutoBlowerLevelIndication_Cmd_IS 570;
BA_REL_ "GenSigFirstTimeoutTime" BU_SG_REL_ HMIIOM SG_ 2498741568 SeatSwivelWarning_rqst 3000;
BA_REL_ "GenSigTimeoutTime" BU_SG_REL_ HMIIOM SG_ 2498741568 SeatSwivelWarning_rqst 570;
BA_REL_ "GenSigFirstTimeoutTime" BU_SG_REL_ HMIIOM SG_ 2498741568 AQSmodeIndication_Cmd_ISig_4 3000;
BA_REL_ "GenSigTimeoutTime" BU_SG_REL_ HMIIOM SG_ 2498741568 AQSmodeIndication_Cmd_ISig_4 570;
BA_REL_ "GenSigFirstTimeoutTime" BU_SG_REL_ VMCU SG_ 2498741568 TemporaryRSLDriverRequest 3000;
BA_REL_ "GenSigTimeoutTime" BU_SG_REL_ VMCU SG_ 2498741568 TemporaryRSLDriverRequest 570;
BA_REL_ "GenSigFirstTimeoutTime" BU_SG_REL_ VMCU SG_ 2498741568 Pto1CabRequest 3000;
BA_REL_ "GenSigTimeoutTime" BU_SG_REL_ VMCU SG_ 2498741568 Pto1CabRequest 570;
BA_REL_ "GenSigFirstTimeoutTime" BU_SG_REL_ BBM SG_ 2498741568 Pto1CabRequest 3000;
BA_REL_ "GenSigTimeoutTime" BU_SG_REL_ BBM SG_ 2498741568 Pto1CabRequest 570;
BA_REL_ "GenSigFirstTimeoutTime" BU_SG_REL_ DACU SG_ 2483023936 LCS_EnableSwitch_rqst 3000;
BA_REL_ "GenSigTimeoutTime" BU_SG_REL_ DACU SG_ 2483023936 LCS_EnableSwitch_rqst 330;
BA_REL_ "GenSigFirstTimeoutTime" BU_SG_REL_ HMIIOM SG_ 2483023936 PH_Activation_cmd_ISig_4 3000;
BA_REL_ "GenSigTimeoutTime" BU_SG_REL_ HMIIOM SG_ 2483023936 PH_Activation_cmd_ISig_4 330;
BA_REL_ "GenSigFirstTimeoutTime" BU_SG_REL_ VMCU SG_ 2483023936 EscCrossCountryActivation_rqst 3000;
BA_REL_ "GenSigTimeoutTime" BU_SG_REL_ VMCU SG_ 2483023936 EscCrossCountryActivation_rqst 330;
BA_REL_ "GenSigFirstTimeoutTime" BU_SG_REL_ VMCU SG_ 2483023936 StaticCornerLightMode 3000;
BA_REL_ "GenSigTimeoutTime" BU_SG_REL_ VMCU SG_ 2483023936 StaticCornerLightMode 330;
BA_REL_ "GenSigFirstTimeoutTime" BU_SG_REL_ HMIIOM SG_ 2483023936 SplitBoxDifflockActvnDrvrRqst_IS 3000;
BA_REL_ "GenSigTimeoutTime" BU_SG_REL_ HMIIOM SG_ 2483023936 SplitBoxDifflockActvnDrvrRqst_IS 500;
BA_REL_ "GenSigFirstTimeoutTime" BU_SG_REL_ EMS SG_ 2483023936 SplitBoxDifflockActvnDrvrRqst_IS 3000;
BA_REL_ "GenSigTimeoutTime" BU_SG_REL_ EMS SG_ 2483023936 SplitBoxDifflockActvnDrvrRqst_IS 500;
BA_REL_ "GenSigFirstTimeoutTime" BU_SG_REL_ VMCU SG_ 2483023936 SplitBoxDifflockActvnDrvrRqst_IS 3000;
BA_REL_ "GenSigTimeoutTime" BU_SG_REL_ VMCU SG_ 2483023936 SplitBoxDifflockActvnDrvrRqst_IS 500;
BA_REL_ "GenSigFirstTimeoutTime" BU_SG_REL_ TECU SG_ 2483023936 SplitBoxDifflockActvnDrvrRqst_IS 3000;
BA_REL_ "GenSigTimeoutTime" BU_SG_REL_ TECU SG_ 2483023936 SplitBoxDifflockActvnDrvrRqst_IS 500;
BA_REL_ "GenSigFirstTimeoutTime" BU_SG_REL_ TECU SG_ 2483023936 ConstructionSwitch_stat 3000;
BA_REL_ "GenSigTimeoutTime" BU_SG_REL_ TECU SG_ 2483023936 ConstructionSwitch_stat 330;
BA_REL_ "GenSigFirstTimeoutTime" BU_SG_REL_ HMIIOM SG_ 2483023936 ConstructionSwitch_stat 3000;
BA_REL_ "GenSigTimeoutTime" BU_SG_REL_ HMIIOM SG_ 2483023936 ConstructionSwitch_stat 330;
BA_REL_ "GenSigFirstTimeoutTime" BU_SG_REL_ HMIIOM SG_ 2483023936 ATCFrontWheelDriveRequest 3000;
BA_REL_ "GenSigTimeoutTime" BU_SG_REL_ HMIIOM SG_ 2483023936 ATCFrontWheelDriveRequest 330;
BA_REL_ "GenSigFirstTimeoutTime" BU_SG_REL_ VMCU SG_ 2483023936 EscCabActionRequest 3000;
BA_REL_ "GenSigTimeoutTime" BU_SG_REL_ VMCU SG_ 2483023936 EscCabActionRequest 330;
BA_REL_ "GenSigFirstTimeoutTime" BU_SG_REL_ VMCU SG_ 2483023936 AdjustRequestForIdle 3000;
BA_REL_ "GenSigTimeoutTime" BU_SG_REL_ VMCU SG_ 2483023936 AdjustRequestForIdle 330;
BA_REL_ "GenSigFirstTimeoutTime" BU_SG_REL_ VMCU SG_ 2483023936 SCL_LogicPowerOutput_stat 3000;
BA_REL_ "GenSigTimeoutTime" BU_SG_REL_ VMCU SG_ 2483023936 SCL_LogicPowerOutput_stat 330;
BA_REL_ "GenSigFirstTimeoutTime" BU_SG_REL_ HMIIOM SG_ 2483023936 PinCode_validity_time 3000;
BA_REL_ "GenSigTimeoutTime" BU_SG_REL_ HMIIOM SG_ 2483023936 PinCode_validity_time 330;
BA_REL_ "GenSigFirstTimeoutTime" BU_SG_REL_ VMCU SG_ 2483023936 StatTrailerBrakeSwitchStatus 3000;
BA_REL_ "GenSigTimeoutTime" BU_SG_REL_ VMCU SG_ 2483023936 StatTrailerBrakeSwitchStatus 330;
BA_REL_ "GenSigFirstTimeoutTime" BU_SG_REL_ VMCU SG_ 2483023936 RoofHatch_HMI_rqst 3000;
BA_REL_ "GenSigTimeoutTime" BU_SG_REL_ VMCU SG_ 2483023936 RoofHatch_HMI_rqst 330;
BA_REL_ "GenSigFirstTimeoutTime" BU_SG_REL_ HMIIOM SG_ 2483023936 EscCabEnable 3000;
BA_REL_ "GenSigTimeoutTime" BU_SG_REL_ HMIIOM SG_ 2483023936 EscCabEnable 330;
BA_REL_ "GenSigFirstTimeoutTime" BU_SG_REL_ VMCU SG_ 2483023936 EscCabEnable 3000;
BA_REL_ "GenSigTimeoutTime" BU_SG_REL_ VMCU SG_ 2483023936 EscCabEnable 330;
BA_REL_ "GenSigFirstTimeoutTime" BU_SG_REL_ VMCU SG_ 2483023936 ExtraSideMarkers_Rqst 3000;
BA_REL_ "GenSigTimeoutTime" BU_SG_REL_ VMCU SG_ 2483023936 ExtraSideMarkers_Rqst 330;
BA_REL_ "GenSigFirstTimeoutTime" BU_SG_REL_ VMCU SG_ 2483023936 LevelingThumbwheel_stat 3000;
BA_REL_ "GenSigTimeoutTime" BU_SG_REL_ VMCU SG_ 2483023936 LevelingThumbwheel_stat 330;
BA_REL_ "GenSigFirstTimeoutTime" BU_SG_REL_ HMIIOM SG_ 2483023936 MemoDisplayIndication_Cmd_ISig_4 3000;
BA_REL_ "GenSigTimeoutTime" BU_SG_REL_ HMIIOM SG_ 2483023936 MemoDisplayIndication_Cmd_ISig_4 330;
BA_REL_ "GenSigFirstTimeoutTime" BU_SG_REL_ DACU SG_ 2483023936 FCW_Enable 3000;
BA_REL_ "GenSigTimeoutTime" BU_SG_REL_ DACU SG_ 2483023936 FCW_Enable 330;
BA_REL_ "GenSigFirstTimeoutTime" BU_SG_REL_ DACU SG_ 2483023936 DASActivation_rqst 3000;
BA_REL_ "GenSigTimeoutTime" BU_SG_REL_ DACU SG_ 2483023936 DASActivation_rqst 330;
BA_REL_ "GenSigFirstTimeoutTime" BU_SG_REL_ VMCU SG_ 2483023936 DriverSeatBeltSwitch_ISig_4 3000;
BA_REL_ "GenSigTimeoutTime" BU_SG_REL_ VMCU SG_ 2483023936 DriverSeatBeltSwitch_ISig_4 330;
BA_REL_ "GenSigFirstTimeoutTime" BU_SG_REL_ DACU SG_ 2483023936 DriverSeatBeltSwitch_ISig_4 3000;
BA_REL_ "GenSigTimeoutTime" BU_SG_REL_ DACU SG_ 2483023936 DriverSeatBeltSwitch_ISig_4 330;
BA_REL_ "GenSigFirstTimeoutTime" BU_SG_REL_ BBM SG_ 2483023936 DriverSeatBeltSwitch_ISig_4 3000;
BA_REL_ "GenSigTimeoutTime" BU_SG_REL_ BBM SG_ 2483023936 DriverSeatBeltSwitch_ISig_4 330;
BA_REL_ "GenSigFirstTimeoutTime" BU_SG_REL_ HMIIOM SG_ 2483023936 DriverSeatBeltSwitch_ISig_4 3000;
BA_REL_ "GenSigTimeoutTime" BU_SG_REL_ HMIIOM SG_ 2483023936 DriverSeatBeltSwitch_ISig_4 330;
BA_REL_ "GenSigFirstTimeoutTime" BU_SG_REL_ HMIIOM SG_ 2483023936 PinCode_stat 3000;
BA_REL_ "GenSigTimeoutTime" BU_SG_REL_ HMIIOM SG_ 2483023936 PinCode_stat 330;
BA_REL_ "GenSigFirstTimeoutTime" BU_SG_REL_ EMS SG_ 2483023936 WarmUp_Request 3000;
BA_REL_ "GenSigTimeoutTime" BU_SG_REL_ EMS SG_ 2483023936 WarmUp_Request 330;
BA_REL_ "GenSigFirstTimeoutTime" BU_SG_REL_ DACU SG_ 2483023936 LKSEnableSwitch_rqst 3000;
BA_REL_ "GenSigTimeoutTime" BU_SG_REL_ DACU SG_ 2483023936 LKSEnableSwitch_rqst 330;
BA_REL_ "GenSigFirstTimeoutTime" BU_SG_REL_ HMIIOM SG_ 2515579712 AlmClkSnze_LECM_rqst_ID_ISig_4 3000;
BA_REL_ "GenSigTimeoutTime" BU_SG_REL_ HMIIOM SG_ 2515579712 AlmClkSnze_LECM_rqst_ID_ISig_4 600;
BA_REL_ "GenSigFirstTimeoutTime" BU_SG_REL_ HMIIOM SG_ 2515579712 AlmClkSetCurAlm_rqst_ID 3000;
BA_REL_ "GenSigTimeoutTime" BU_SG_REL_ HMIIOM SG_ 2515579712 AlmClkSetCurAlm_rqst_ID 600;
BA_REL_ "GenSigFirstTimeoutTime" BU_SG_REL_ HMIIOM SG_ 2515579712 AlmClkSnze_LECM_rqst_Action_ISig 3000;
BA_REL_ "GenSigTimeoutTime" BU_SG_REL_ HMIIOM SG_ 2515579712 AlmClkSnze_LECM_rqst_Action_ISig 600;
BA_REL_ "GenSigFirstTimeoutTime" BU_SG_REL_ HMIIOM SG_ 2515579712 AlmClkSetCurAlm_rqst_Stat 3000;
BA_REL_ "GenSigTimeoutTime" BU_SG_REL_ HMIIOM SG_ 2515579712 AlmClkSetCurAlm_rqst_Stat 600;
BA_REL_ "GenSigFirstTimeoutTime" BU_SG_REL_ HMIIOM SG_ 2515579712 AlmClkSetCurAlm_rqst_SetMin 3000;
BA_REL_ "GenSigTimeoutTime" BU_SG_REL_ HMIIOM SG_ 2515579712 AlmClkSetCurAlm_rqst_SetMin 600;
BA_REL_ "GenSigFirstTimeoutTime" BU_SG_REL_ HMIIOM SG_ 2515579712 AlmClkSetCurAlm_rqst_SetHr 3000;
BA_REL_ "GenSigTimeoutTime" BU_SG_REL_ HMIIOM SG_ 2515579712 AlmClkSetCurAlm_rqst_SetHr 600;
BA_REL_ "GenSigFirstTimeoutTime" BU_SG_REL_ HMIIOM SG_ 2515579712 CollSituationHMICtrlRequestVM_IS 3000;
BA_REL_ "GenSigTimeoutTime" BU_SG_REL_ HMIIOM SG_ 2515579712 CollSituationHMICtrlRequestVM_IS 600;
BA_REL_ "GenSigFirstTimeoutTime" BU_SG_REL_ EMS SG_ 2515579712 AcCoolantPumpEngagementRequest_I 3000;
BA_REL_ "GenSigTimeoutTime" BU_SG_REL_ EMS SG_ 2515579712 AcCoolantPumpEngagementRequest_I 600;
BA_REL_ "GenSigFirstTimeoutTime" BU_SG_REL_ HMIIOM SG_ 2515579712 AlmClkSetCurAlm_rqst_Type 3000;
BA_REL_ "GenSigTimeoutTime" BU_SG_REL_ HMIIOM SG_ 2515579712 AlmClkSetCurAlm_rqst_Type 600;
BA_REL_ "GenSigFirstTimeoutTime" BU_SG_REL_ HMIIOM SG_ 2515579712 WRC_Docking_stat_ISig_4 3000;
BA_REL_ "GenSigTimeoutTime" BU_SG_REL_ HMIIOM SG_ 2515579712 WRC_Docking_stat_ISig_4 600;
BA_REL_ "GenSigFirstTimeoutTime" BU_SG_REL_ HMIIOM SG_ 2482995008 Regeneration2PosSwitchStatus 3000;
BA_REL_ "GenSigTimeoutTime" BU_SG_REL_ HMIIOM SG_ 2482995008 Regeneration2PosSwitchStatus 300;
BA_REL_ "GenSigFirstTimeoutTime" BU_SG_REL_ BBM SG_ 2482995008 WRCEngineStopRequest_ISig_4 3000;
BA_REL_ "GenSigTimeoutTime" BU_SG_REL_ BBM SG_ 2482995008 WRCEngineStopRequest_ISig_4 500;
BA_REL_ "GenSigFirstTimeoutTime" BU_SG_REL_ VMCU SG_ 2482995008 LiftAxle1DirectControl_ISig_4 3000;
BA_REL_ "GenSigTimeoutTime" BU_SG_REL_ VMCU SG_ 2482995008 LiftAxle1DirectControl_ISig_4 500;
BA_REL_ "GenSigFirstTimeoutTime" BU_SG_REL_ VMCU SG_ 2482995008 PanicAlarmFromKeyfob_rqst 3000;
BA_REL_ "GenSigTimeoutTime" BU_SG_REL_ VMCU SG_ 2482995008 PanicAlarmFromKeyfob_rqst 300;
BA_REL_ "GenSigFirstTimeoutTime" BU_SG_REL_ HMIIOM SG_ 2482995008 InhibRegenerationSwitch_stat 3000;
BA_REL_ "GenSigTimeoutTime" BU_SG_REL_ HMIIOM SG_ 2482995008 InhibRegenerationSwitch_stat 300;
BA_REL_ "GenSigFirstTimeoutTime" BU_SG_REL_ HMIIOM SG_ 2482995008 ParkingClimate_IndicationCmd_ISi 3000;
BA_REL_ "GenSigTimeoutTime" BU_SG_REL_ HMIIOM SG_ 2482995008 ParkingClimate_IndicationCmd_ISi 300;
BA_REL_ "GenSigFirstTimeoutTime" BU_SG_REL_ HMIIOM SG_ 2482995008 DriverDoorAjar_stat_ISig_4 3000;
BA_REL_ "GenSigTimeoutTime" BU_SG_REL_ HMIIOM SG_ 2482995008 DriverDoorAjar_stat_ISig_4 300;
BA_REL_ "GenSigFirstTimeoutTime" BU_SG_REL_ BBM SG_ 2482995008 WRCEngineStartRequest_ISig_4 3000;
BA_REL_ "GenSigTimeoutTime" BU_SG_REL_ BBM SG_ 2482995008 WRCEngineStartRequest_ISig_4 500;
BA_REL_ "GenSigFirstTimeoutTime" BU_SG_REL_ HMIIOM SG_ 2482995008 RegenerationPushButtonStatus_ISi 3000;
BA_REL_ "GenSigTimeoutTime" BU_SG_REL_ HMIIOM SG_ 2482995008 RegenerationPushButtonStatus_ISi 300;
BA_REL_ "GenSigFirstTimeoutTime" BU_SG_REL_ HMIIOM SG_ 2482995008 RegenerationSwitchStatus_ISig_4 3000;
BA_REL_ "GenSigTimeoutTime" BU_SG_REL_ HMIIOM SG_ 2482995008 RegenerationSwitchStatus_ISig_4 300;
BA_REL_ "GenSigFirstTimeoutTime" BU_SG_REL_ BBM SG_ 2482995008 DoorLock_stat_ISig_4 3000;
BA_REL_ "GenSigTimeoutTime" BU_SG_REL_ BBM SG_ 2482995008 DoorLock_stat_ISig_4 300;
BA_REL_ "GenSigFirstTimeoutTime" BU_SG_REL_ HMIIOM SG_ 2482995008 DoorLock_stat_ISig_4 3000;
BA_REL_ "GenSigTimeoutTime" BU_SG_REL_ HMIIOM SG_ 2482995008 DoorLock_stat_ISig_4 300;
BA_REL_ "GenSigFirstTimeoutTime" BU_SG_REL_ HMIIOM SG_ 2482995008 LuggageAjar_stat_ISig_4 3000;
BA_REL_ "GenSigTimeoutTime" BU_SG_REL_ HMIIOM SG_ 2482995008 LuggageAjar_stat_ISig_4 300;
BA_REL_ "GenSigFirstTimeoutTime" BU_SG_REL_ HMIIOM SG_ 2482995008 AlarmStatus_stat_ISig_4 3000;
BA_REL_ "GenSigTimeoutTime" BU_SG_REL_ HMIIOM SG_ 2482995008 AlarmStatus_stat_ISig_4 300;
BA_REL_ "GenSigFirstTimeoutTime" BU_SG_REL_ HMIIOM SG_ 2482995008 AlarmTriggeringCause_stat_ISig_4 3000;
BA_REL_ "GenSigTimeoutTime" BU_SG_REL_ HMIIOM SG_ 2482995008 AlarmTriggeringCause_stat_ISig_4 300;
BA_REL_ "GenSigFirstTimeoutTime" BU_SG_REL_ HMIIOM SG_ 2482995008 DoorsAjar_stat_ISig_4 3000;
BA_REL_ "GenSigTimeoutTime" BU_SG_REL_ HMIIOM SG_ 2482995008 DoorsAjar_stat_ISig_4 500;
BA_REL_ "GenSigFirstTimeoutTime" BU_SG_REL_ VMCU SG_ 2482995008 DoorsAjar_stat_ISig_4 3000;
BA_REL_ "GenSigTimeoutTime" BU_SG_REL_ VMCU SG_ 2482995008 DoorsAjar_stat_ISig_4 500;
BA_REL_ "GenSigFirstTimeoutTime" BU_SG_REL_ DACU SG_ 2482995008 DoorsAjar_stat_ISig_4 3000;
BA_REL_ "GenSigTimeoutTime" BU_SG_REL_ DACU SG_ 2482995008 DoorsAjar_stat_ISig_4 500;
BA_REL_ "GenSigFirstTimeoutTime" BU_SG_REL_ BBM SG_ 2482995008 DoorsAjar_stat_ISig_4 3000;
BA_REL_ "GenSigTimeoutTime" BU_SG_REL_ BBM SG_ 2482995008 DoorsAjar_stat_ISig_4 500;
BA_REL_ "GenSigFirstTimeoutTime" BU_SG_REL_ VMCU SG_ 2482995008 DoorAutoFunction_rqst 3000;
BA_REL_ "GenSigTimeoutTime" BU_SG_REL_ VMCU SG_ 2482995008 DoorAutoFunction_rqst 300;
VAL_ 2432641616 FASHapticFeedbackRequest_ISig_4 15 "FASHapticFeedbackRequest_NotAvailable" 14 "FASHapticFeedbackRequest_Error" 13 "FASHapticFeedbackRequest_Spare3" 12 "FASHapticFeedbackRequest_Spare2" 11 "FASHapticFeedbackRequest_Spare1" 10 "FASHapticFeedbackRequest_PredefinedFreqAndAmpl10" 9 "FASHapticFeedbackRequest_PredefinedFreqAndAmpl9" 8 "FASHapticFeedbackRequest_PredefinedFreqAndAmpl8" 7 "FASHapticFeedbackRequest_PredefinedFreqAndAmpl7" 6 "FASHapticFeedbackRequest_PredefinedFreqAndAmpl6" 5 "FASHapticFeedbackRequest_PredefinedFreqAndAmpl5" 4 "FASHapticFeedbackRequest_PredefinedFreqAndAmpl4" 3 "FASHapticFeedbackRequest_PredefinedFreqAndAmpl3" 2 "FASHapticFeedbackRequest_PredefinedFreqAndAmpl2" 1 "FASHapticFeedbackRequest_PredefinedFreqAndAmpl1" 0 "FASHapticFeedbackRequest_NoHapticFeedback" ;
VAL_ 2499772240 VisionLight_stat 7 "VisionLight_stat_NotAvailable" 6 "VisionLight_stat_Error" 5 "VisionLight_stat_Spare02" 4 "VisionLight_stat_Spare01" 3 "VisionLight_stat_CameraBlockedCondition" 2 "VisionLight_stat_NightSufficientLight" 1 "VisionLight_stat_NightNotSufficientLight" 0 "VisionLight_stat_Day" ;
VAL_ 2499772240 BBSteeringStatus_ISig_4 3 "InactiveActive_NotAvailable" 2 "InactiveActive_Error" 1 "InactiveActive_Active" 0 "InactiveActive_Inactive" ;
VAL_ 2466246992 ForwardLookingCameraStatus_ISig_ 15 "CameraStatus_NotAvailable" 14 "CameraStatus_Error" 13 "CameraStatus_Spare08" 12 "CameraStatus_Spare07" 11 "CameraStatus_Spare06" 10 "CameraStatus_Spare05" 9 "CameraStatus_Spare04" 8 "CameraStatus_Failure" 7 "CameraStatus_ShutDownCompleted" 6 "CameraStatus_ShutDownInitiated" 5 "CameraStatus_CalibrationOngoing" 4 "CameraStatus_NotCalibrated" 3 "CameraStatus_Misaligned" 2 "CameraStatus_Blocked" 1 "CameraStatus_WarmingUp" 0 "CameraStatus_FullyOperational" ;
VAL_ 2466246992 XARDACU_ControlMode 3 "XARControlMode_NotDefined" 2 "XARControlMode_CoastingModeRequest" 1 "XARControlMode_AccelerationControlWithMaximumMode" 0 "XARControlMode_OverrideDisabled" ;
VAL_ 2466246992 ACCiRollInhibit 3 "Inhibit_NotAvailable" 2 "Inhibit_Error" 1 "Inhibit_InhibitActive" 0 "Inhibit_NoInhibit" ;
VAL_ 2466246992 CMReducedAbilityStatus_ISig_4 7 "ReducedAbilityStatus_NotAvailable" 6 "ReducedAbilityStatus_Error" 5 "ReducedAbilityStatus_Spare4" 4 "ReducedAbilityStatus_Spare3" 3 "ReducedAbilityStatus_Spare2" 2 "ReducedAbilityStatus_Spare1" 1 "ReducedAbilityStatus_ReducedAbility" 0 "ReducedAbilityStatus_NoReducedAbility" ;
VAL_ 2466246992 LPOSBlocked_ISig_4 3 "FalseTrue_NotAvaiable" 2 "FalseTrue_Error" 1 "FalseTrue_True" 0 "FalseTrue_False" ;
VAL_ 2466246992 ForwardLookingRadarStatus_ISig_4 15 "RadarStatus_NotAvailable" 14 "RadarStatus_Error" 13 "RadarStatus_Spare05" 12 "RadarStatus_Spare04" 11 "RadarStatus_Spare03" 10 "RadarStatus_Spare02" 9 "RadarStatus_Spare01" 8 "RadarStatus_Failure" 7 "RadarStatus_ShutDownCompleted" 6 "RadarStatus_ShutDownInitiated" 5 "RadarStatus_CalibrationOngoing" 4 "RadarStatus_NotCalibrated" 3 "RadarStatus_Misaligned" 2 "RadarStatus_Blocked" 1 "RadarStatus_WarmingUp" 0 "RadarStatus_FullyOperational" ;
VAL_ 2466246992 CollSituationHazardLightReq 7 "ActivateDeactivateRqst3bit_NotAvailable" 6 "ActivateDeactivateRqst3bit_Error" 5 "ActivateDeactivateRqst3bit_Spare3" 4 "ActivateDeactivateRqst3bit_Spare2" 3 "ActivateDeactivateRqst3bit_Spare1" 2 "ActivateDeactivateRqst3bit_DeactivationRequest" 1 "ActivateDeactivateRqst3bit_ActivationRequest" 0 "ActivateDeactivateRqst3bit_NoRequest" ;
VAL_ 2432690512 PathDeviationDriverAlert_ISig_4 7 "LKSDepartureWarningStatus_NotAvailable" 6 "LKSDepartureWarningStatus_ErrorIndication" 5 "LKSDepartureWarningStatus_MajorDepartureWarning_Right" 4 "LKSDepartureWarningStatus_MajorDepartureWarning_Left" 3 "LKSDepartureWarningStatus_MinorDepartureWarning_Right" 2 "LKSDepartureWarningStatus_MinorDepartureWarning_Left" 1 "LKSDepartureWarningStatus_WarningNotPossible" 0 "LKSDepartureWarningStatus_NoWarning" ;
VAL_ 2432690512 CM_DisengageDrivelineRequest 3 "CM_DisengageDrivelineRequest_TakeNoAction" 2 "CM_DisengageDrivelineRequest_Reserved" 1 "CM_DisengageDrivelineRequest_DisengageDriveline" 0 "CM_DisengageDrivelineRequest_AllowDrivelineEngagement" ;
VAL_ 2432690512 ACCBrakeRequestStatus 3 "InactiveActive_NotAvailable" 2 "InactiveActive_Error" 1 "InactiveActive_Active" 0 "InactiveActive_Inactive" ;
VAL_ 2432690512 FrontalCollisionDriverAlert_ISig 7 "FCW_Warning_NotAvailable" 6 "FCW_Warning_ErrorIndicator" 5 "FCW_Warning_SpareValue_01" 4 "FCW_Warning_SpareValue" 3 "FCW_Warning_CMbBActiveWarning" 2 "FCW_Warning_CollisionWarning" 1 "FCW_Warning_PreliminaryCollisionWarning" 0 "FCW_Warning_NoWarning" ;
VAL_ 2432690512 ACCBrakeCapacityWarning_ISig_4 3 "ACCBrakeCapacityWarning_TakeNoAction" 2 "ACCBrakeCapacityWarning_Reserved" 1 "ACCBrakeCapacityWarning_ACCBrakeCapacityWarningACTIVE" 0 "ACCBrakeCapacityWarning_ACCBrakeCapacityWarningNOTACTIVE" ;
VAL_ 2432690512 ACC_SGOFaultCondStat_SeatBelt_IS 1 "SeatBeltIndicationRqst_IndicationRequested" 0 "SeatBeltIndicationRqst_NoIndicationRequested" ;
VAL_ 2432690512 CM_Status_ISig_4 7 "CM_Status_NotAvailable" 6 "CM_Status_ErrorIndicator" 5 "CM_Status_CM_DisabledBySystem" 4 "CM_Status_CM_MitigationBrakingFinished" 3 "CM_Status_CM_MitigationBraking" 2 "CM_Status_CM_PreMitigationBraking" 1 "CM_Status_CM_Enabled" 0 "CM_Status_CM_Disabled" ;
VAL_ 2432690512 DASApplicationStatus_ISig_4 7 "DASSystemStatus_NA" 6 "DASSystemStatus_Error" 5 "DASSystemStatus_SpareValue_01" 4 "DASSystemStatus_SpareValue" 3 "DASSystemStatus_Limited_func" 2 "DASSystemStatus_INACTIVE" 1 "DASSystemStatus_ACTIVE" 0 "DASSystemStatus_OFF" ;
VAL_ 2432690512 ACC_Status_ISig_4 7 "ACC_Status_NotAvailable" 6 "ACC_Status_Error" 5 "ACC_Status_ACCFailureAndInactive" 4 "ACC_Status_Reserved" 3 "ACC_Status_ActiveWithLimitedBrakeCapacity" 2 "ACC_Status_ActiveECONOMYMODE" 1 "ACC_Status_ActiveSTANDARDMODE" 0 "ACC_Status_Inactive" ;
VAL_ 2432690512 LKSApplicationStatus_ISig_4 7 "LKSStatus_NotAvailable" 6 "LKSStatus_Error" 5 "LKSStatus_Spare_02" 4 "LKSStatus_Spare_01" 3 "LKSStatus_Spare" 2 "LKSStatus_ACTIVE" 1 "LKSStatus_INACTIVE" 0 "LKSStatus_OFF" ;
VAL_ 2432690512 LCSSystemStatus 7 "LCSSystemStatus_NotAvailable" 6 "LCSSystemStatus_Error" 5 "LCSSystemStatus_NotUsed" 4 "LCSSystemStatus_WarningRight" 3 "LCSSystemStatus_WarningLeft" 2 "LCSSystemStatus_EnabledAndActive" 1 "LCSSystemStatus_EnabledAndInactive" 0 "LCSSystemStatus_Disabled" ;
VAL_ 2432690512 ACC_SGOFaultCondStat_SigStat_ISi 1 "SigStat_SignalNotAvailable" 0 "SigStat_SignalOK" ;
VAL_ 2432690512 ACC_SGOFaultCondStat_Target_ISig 1 "TargetIndicationRqst_IndicationRequested" 0 "TargetIndicationRqst_NoIndicationRequested" ;
VAL_ 2432690512 FCW_Status_ISig_4 3 "DisableEnable_NotAvailable" 2 "DisableEnable_Error" 1 "DisableEnable_Enable" 0 "DisableEnable_Disable" ;
VAL_ 2432690512 DriverImpairedDriverAlert_ISig_4 7 "DASImpairmentWarningStatus_NotAvailable" 6 "DASImpairmentWarningStatus_ErrorIndicator" 5 "DASImpairmentWarningStatus_SPAREValue_02" 4 "DASImpairmentWarningStatus_SPAREValue_01" 3 "DASImpairmentWarningStatus_SPAREValue" 2 "DASImpairmentWarningStatus_MajorImpairmentWarning" 1 "DASImpairmentWarningStatus_MinorImpairmentWarning" 0 "DASImpairmentWarningStatus_NoWarning" ;
VAL_ 2432690512 DriverVigilanceLevel_ISig_4 7 "DASVigilanceLevelStatus_NotAvailable" 6 "DASVigilanceLevelStatus_Error" 5 "DASVigilanceLevelStatus_VigilanceLevel5" 4 "DASVigilanceLevelStatus_VigilanceLevel4" 3 "DASVigilanceLevelStatus_VigilanceLevel3" 2 "DASVigilanceLevelStatus_VigilanceLevel2" 1 "DASVigilanceLevelStatus_VigilanceLevel1" 0 "DASVigilanceLevelStatus_DASUnavailable" ;
VAL_ 2432690512 ACC_SGOFaultCondStat_Door_ISig_4 1 "DoorIndicationRqst_IndicationRequested" 0 "DoorIndicationRqst_NoIndicationRequested" ;
VAL_ 2432690512 ACCTargetDetected_ISig_4 3 "ACCTargetDetected_TakeNoAction" 2 "ACCTargetDetected_Reserved" 1 "ACCTargetDetected_TargetDetected" 0 "ACCTargetDetected_NoTargetsDetected" ;
VAL_ 2432690512 LKSCorrectiveSteeringStatus 7 "LKSCorrectiveSteeringStatus_NotAvailable" 6 "LKSCorrectiveSteeringStatus_Error" 5 "LKSCorrectiveSteeringStatus_Spare2" 4 "LKSCorrectiveSteeringStatus_Spare1" 3 "LKSCorrectiveSteeringStatus_DriverTakeOverRqst" 2 "LKSCorrectiveSteeringStatus_Active" 1 "LKSCorrectiveSteeringStatus_Inactive" 0 "LKSCorrectiveSteeringStatus_Off" ;
VAL_ 2432690512 ACC_SGOFaultCondStat_Other_ISig_ 1 "IndicationRqst_IndicationRequested" 0 "IndicationRqst_NoIndicationRequested" ;
VAL_ 2432690512 LCSSoundSettingStatus 3 "LCSSoundSettingStatus_NotAvailable" 2 "LCSSoundSettingStatus_Error" 1 "LCSSoundSettingStatus_LCSSoundAnabled" 0 "LCSSoundSettingStatus_LCSSoundDisabled" ;
VAL_ 2432690512 ACC_SGOFaultCondStat_Speed_ISig_ 1 "SpeedIndicationRqst_IndicationRequested" 0 "SpeedIndicationRqst_NoIndicationRequested" ;
VAL_ 2432685120 LKSCSEnableSwitch_rqst 3 "OffOn_NotAvailable" 2 "OffOn_Error" 1 "OffOn_On" 0 "OffOn_Off" ;
VAL_ 2566078272 RollerBenchModeRequest_2 3 "OffOn_NotAvailable" 2 "OffOn_Error" 1 "OffOn_On" 0 "OffOn_Off" ;
VAL_ 2566078272 TrafficAccidentHazardLightRqst_I 3 "Request_NotAvailable" 2 "Request_Error" 1 "Request_RequestActive" 0 "Request_NotRequested" ;
VAL_ 2566078272 GearboxUnlockAuth_stat 7 "GearboxUnlockAuth_stat_NotAvaiable" 6 "GearboxUnlockAuth_stat_Error" 5 "GearboxUnlockAuth_stat_Spare3" 4 "GearboxUnlockAuth_stat_Spare2" 3 "GearboxUnlockAuth_stat_Spare1" 2 "GearboxUnlockAuth_stat_GearEngagementRefused" 1 "GearboxUnlockAuth_stat_GearEngagementAllowed" 0 "GearboxUnlockAuth_stat_Idle" ;
VAL_ 2566078272 InhibRegeneration_ButtonStat 3 "PushButtonStatus_NotAvailable" 2 "PushButtonStatus_Error" 1 "PushButtonStatus_Pushed" 0 "PushButtonStatus_Neutral" ;
VAL_ 2490646336 MediaSourcesListReq_SInfo_ISig_4 3 "SignalInfo2bitType_NotAvailable" 2 "SignalInfo2bitType_ErrorIndication" 1 "SignalInfo2bitType_Spare" 0 "SignalInfo2bitType_Valid" ;
VAL_ 2499780850 AlmClkSetAlm_LECM_rq_Type_ISig_4 7 "AlarmClkType_NotAvailable" 6 "AlarmClkType_Error" 5 "AlarmClkType_Reserved_02" 4 "AlarmClkType_Reserved_01" 3 "AlarmClkType_Reserved" 2 "AlarmClkType_Radio" 1 "AlarmClkType_Buzzer" 0 "AlarmClkType_NoAudibleNotification" ;
VAL_ 2499780850 AlmClkSetAlm_LECM_rq_ID_ISig_4 127 "AlarmClkID_NotAvailable" 126 "AlarmClkID_Error" 10 "AlarmClkID_Alarm10" 9 "AlarmClkID_Alarm9" 8 "AlarmClkID_Alarm8" 7 "AlarmClkID_Alarm7" 6 "AlarmClkID_Alarm6" 5 "AlarmClkID_Alarm5" 4 "AlarmClkID_Alarm4" 3 "AlarmClkID_Alarm3" 2 "AlarmClkID_Alarm2" 1 "AlarmClkID_Alarm1" 0 "AlarmClkID_NotUsed" ;
VAL_ 2499780850 AlmClkSetAlm_LECM_rq_Stat_ISig_4 3 "AlarmClkStat2_Snoozed" 2 "AlarmClkStat2_Ringing" 1 "AlarmClkStat2_Active" 0 "AlarmClkStat2_Inactive" ;
VAL_ 2499780850 AlmClkSetAlm_LECM_rq_Mode_ISig_4 3 "AlarmClkMode_Spare" 2 "AlarmClkMode_Timer" 1 "AlarmClkMode_Recurrent" 0 "AlarmClkMode_OneTime" ;
VAL_ 2482978624 TipperUpDownRequest_ISig_4 7 "UpDown_NotAvailable" 6 "UpDown_Error" 5 "UpDown_Spare2" 4 "UpDown_Spare1" 3 "UpDown_RequestDownAuto" 2 "UpDown_RequestDown" 1 "UpDown_RequestUp" 0 "UpDown_NoRequest" ;
VAL_ 2482978624 LoadDistributionRequested_ISig_4 15 "LoadDistributionRequested_NotAvailable" 14 "LoadDistributionRequested_Error" 13 "LoadDistributionRequested_Reserved5" 12 "LoadDistributionRequested_Reserved4" 11 "LoadDistributionRequested_Reserved3" 10 "LoadDistributionRequested_Reserved2" 9 "LoadDistributionRequested_Reserved1" 8 "LoadDistributionRequested_DelpressLoadDistribution" 7 "LoadDistributionRequested_VariableLoadDistribution" 6 "LoadDistributionRequested_AlternativeLoadDistribution" 5 "LoadDistributionRequested_MaximumTraction2" 4 "LoadDistributionRequested_MaximumTraction1" 3 "LoadDistributionRequested_OptimizedTraction" 2 "LoadDistributionRequested_NormalLoadDistribution" 1 "LoadDistributionRequested_DefaultLoadDistribution" 0 "LoadDistributionRequested_NoAction" ;
VAL_ 2482978624 TipperTailGateRequest_ISig_4 7 "OpenCloseRqst_NotAvailable" 6 "OpenCloseRqst_Error" 5 "OpenCloseRqst_Spare3" 4 "OpenCloseRqst_Spare2" 3 "OpenCloseRqst_Spare1" 2 "OpenCloseRqst_Close" 1 "OpenCloseRqst_Open" 0 "OpenCloseRqst_NoRequest" ;
VAL_ 2482978624 TipperTippingBodySelection_ISig_ 3 "PrimarySecondary_NotAvailable" 2 "PrimarySecondary_Error" 1 "PrimarySecondary_Secondary" 0 "PrimarySecondary_Primary" ;
VAL_ 2482978624 TipperEmergencyStop_ISig_4 3 "StopRqst_NotAvailable" 2 "StopRqst_Error" 1 "StopRqst_Stop" 0 "StopRqst_NoRequest" ;
VAL_ 2482978624 ExtraBbWrcWatchdog_ISig_4 3 "LowHigh_NotAvailable" 2 "LowHigh_Error" 1 "LowHigh_High" 0 "LowHigh_Low" ;
VAL_ 2482978624 AutoFrontWheelDriveDrvReq 3 "DisengageEngage_NotAvailable" 2 "DisengageEngage_Error" 1 "DisengageEngage_Engage" 0 "DisengageEngage_Disengage" ;
VAL_ 2482978624 FrontalCollisionAccidentStatus_I 3 "NotDetected_NotAvaliable" 2 "NotDetected_Error" 1 "NotDetected_Detected" 0 "NotDetected_NotDetected" ;
VAL_ 2482978624 ShortStopHeater_cmd_ISig_4 3 "Request_NotAvailable" 2 "Request_Error" 1 "Request_RequestActive" 0 "Request_NotRequested" ;
VAL_ 2482978624 TailLiftMotionRequest_ISig_4 7 "RqstTiltUpDown_NotAvailable" 6 "RqstTiltUpDown_Error" 5 "RqstTiltUpDown_Spare" 4 "RqstTiltUpDown_TiltDown" 3 "RqstTiltUpDown_TiltUp" 2 "RqstTiltUpDown_RequestDown" 1 "RqstTiltUpDown_RequestUp" 0 "RqstTiltUpDown_NoRequest" ;
VAL_ 2482978624 TipperShakerRequest_ISig_4 3 "ShakeRqst_NotAvailable" 2 "ShakeRqst_Error" 1 "ShakeRqst_Shake" 0 "ShakeRqst_NoRequest" ;
VAL_ 2482978624 TipperTarpaulinRequest_ISig_4 7 "CoverUncoverRqst_NotAvailable" 6 "CoverUncoverRqst_Error" 5 "CoverUncoverRqst_Spare3" 4 "CoverUncoverRqst_Spare2" 3 "CoverUncoverRqst_Spare1" 2 "CoverUncoverRqst_Uncover" 1 "CoverUncoverRqst_Cover" 0 "CoverUncoverRqst_NoRequest" ;
VAL_ 2482978624 ExtraHeating_status_ISig_4 3 "OffAuto_NotAvailable" 2 "OffAuto_Error" 1 "OffAuto_AutoStart" 0 "OffAuto_Off" ;
VAL_ 2499804480 PHTimer3_stat_Recurrence_ISig_4 15 "HeaterTimerRecurrence_NotAvailable" 14 "HeaterTimerRecurrence_Error" 13 "HeaterTimerRecurrence_Spare_3" 12 "HeaterTimerRecurrence_Spare_2" 11 "HeaterTimerRecurrence_Spare_1" 10 "HeaterTimerRecurrence_Sundays" 9 "HeaterTimerRecurrence_Saturdays" 8 "HeaterTimerRecurrence_Fridays" 7 "HeaterTimerRecurrence_Thursdays" 6 "HeaterTimerRecurrence_Wednesdays" 5 "HeaterTimerRecurrence_Tuesdays" 4 "HeaterTimerRecurrence_Mondays" 3 "HeaterTimerRecurrence_Weekends" 2 "HeaterTimerRecurrence_AllWeekdays" 1 "HeaterTimerRecurrence_Daily" 0 "HeaterTimerRecurrence_None" ;
VAL_ 2499804480 PHTimer2_stat_Status_ISig_4 3 "ParkHeaterTimer_Status_NotAvailable" 2 "ParkHeaterTimer_Status_TimerDeleted" 1 "ParkHeaterTimer_Status_TimerNotActivated" 0 "ParkHeaterTimer_Status_TimerActivated" ;
VAL_ 2499804480 PHTimer3_stat_StartDay_ISig_4 15 "HeaterTimerStartDay_NotAvailable" 14 "HeaterTimerStartDay_Error" 13 "HeaterTimerStartDay_Spare_05" 12 "HeaterTimerStartDay_Spare_04" 11 "HeaterTimerStartDay_Spare_03" 10 "HeaterTimerStartDay_Spare_02" 9 "HeaterTimerStartDay_Spare_01" 8 "HeaterTimerStartDay_Spare" 7 "HeaterTimerStartDay_Sunday" 6 "HeaterTimerStartDay_Saturday" 5 "HeaterTimerStartDay_Friday" 4 "HeaterTimerStartDay_Thursday" 3 "HeaterTimerStartDay_Wednesday" 2 "HeaterTimerStartDay_Tuesday" 1 "HeaterTimerStartDay_Monday" 0 "HeaterTimerStartDay_NotUsed" ;
VAL_ 2499804480 PHTimer3_stat_Status_ISig_4 3 "ParkHeaterTimer_Status_NotAvailable" 2 "ParkHeaterTimer_Status_TimerDeleted" 1 "ParkHeaterTimer_Status_TimerNotActivated" 0 "ParkHeaterTimer_Status_TimerActivated" ;
VAL_ 2499804480 PHTimer2_stat_Temp_ISig_4 31 "TemperatureRqstIndication_cmd_NotAvailable" 30 "TemperatureRqstIndication_cmd_Error" 29 "TemperatureRqstIndication_cmd_Spare_01" 28 "TemperatureRqstIndication_cmd_Spare" 27 "TemperatureRqstIndication_cmd_Max" 26 "TemperatureRqstIndication_cmd_29C" 25 "TemperatureRqstIndication_cmd_28C" 24 "TemperatureRqstIndication_cmd_27C" 23 "TemperatureRqstIndication_cmd_26C" 22 "TemperatureRqstIndication_cmd_25_5C" 21 "TemperatureRqstIndication_cmd_25C" 20 "TemperatureRqstIndication_cmd_24_5C" 19 "TemperatureRqstIndication_cmd_24C" 18 "TemperatureRqstIndication_cmd_23_5C" 17 "TemperatureRqstIndication_cmd_23C" 16 "TemperatureRqstIndication_cmd_22_5C" 15 "TemperatureRqstIndication_cmd_22C" 14 "TemperatureRqstIndication_cmd_21_5C" 13 "TemperatureRqstIndication_cmd_21C" 12 "TemperatureRqstIndication_cmd_20_5C" 11 "TemperatureRqstIndication_cmd_20C" 10 "TemperatureRqstIndication_cmd_19_5C" 9 "TemperatureRqstIndication_cmd_19C" 8 "TemperatureRqstIndication_cmd_18_5C" 7 "TemperatureRqstIndication_cmd_18C" 6 "TemperatureRqstIndication_cmd_17_5C" 5 "TemperatureRqstIndication_cmd_17C" 4 "TemperatureRqstIndication_cmd_16_5C" 3 "TemperatureRqstIndication_cmd_16C" 2 "TemperatureRqstIndication_cmd_15C" 1 "TemperatureRqstIndication_cmd_Min" 0 "TemperatureRqstIndication_cmd_NoTempDisplayed" ;
VAL_ 2499804480 PHTimer3_stat_Temp_ISig_4 31 "TemperatureRqstIndication_cmd_NotAvailable" 30 "TemperatureRqstIndication_cmd_Error" 29 "TemperatureRqstIndication_cmd_Spare_01" 28 "TemperatureRqstIndication_cmd_Spare" 27 "TemperatureRqstIndication_cmd_Max" 26 "TemperatureRqstIndication_cmd_29C" 25 "TemperatureRqstIndication_cmd_28C" 24 "TemperatureRqstIndication_cmd_27C" 23 "TemperatureRqstIndication_cmd_26C" 22 "TemperatureRqstIndication_cmd_25_5C" 21 "TemperatureRqstIndication_cmd_25C" 20 "TemperatureRqstIndication_cmd_24_5C" 19 "TemperatureRqstIndication_cmd_24C" 18 "TemperatureRqstIndication_cmd_23_5C" 17 "TemperatureRqstIndication_cmd_23C" 16 "TemperatureRqstIndication_cmd_22_5C" 15 "TemperatureRqstIndication_cmd_22C" 14 "TemperatureRqstIndication_cmd_21_5C" 13 "TemperatureRqstIndication_cmd_21C" 12 "TemperatureRqstIndication_cmd_20_5C" 11 "TemperatureRqstIndication_cmd_20C" 10 "TemperatureRqstIndication_cmd_19_5C" 9 "TemperatureRqstIndication_cmd_19C" 8 "TemperatureRqstIndication_cmd_18_5C" 7 "TemperatureRqstIndication_cmd_18C" 6 "TemperatureRqstIndication_cmd_17_5C" 5 "TemperatureRqstIndication_cmd_17C" 4 "TemperatureRqstIndication_cmd_16_5C" 3 "TemperatureRqstIndication_cmd_16C" 2 "TemperatureRqstIndication_cmd_15C" 1 "TemperatureRqstIndication_cmd_Min" 0 "TemperatureRqstIndication_cmd_NoTempDisplayed" ;
VAL_ 2499804480 PHTimer2_stat_Recurrence_ISig_4 15 "HeaterTimerRecurrence_NotAvailable" 14 "HeaterTimerRecurrence_Error" 13 "HeaterTimerRecurrence_Spare_3" 12 "HeaterTimerRecurrence_Spare_2" 11 "HeaterTimerRecurrence_Spare_1" 10 "HeaterTimerRecurrence_Sundays" 9 "HeaterTimerRecurrence_Saturdays" 8 "HeaterTimerRecurrence_Fridays" 7 "HeaterTimerRecurrence_Thursdays" 6 "HeaterTimerRecurrence_Wednesdays" 5 "HeaterTimerRecurrence_Tuesdays" 4 "HeaterTimerRecurrence_Mondays" 3 "HeaterTimerRecurrence_Weekends" 2 "HeaterTimerRecurrence_AllWeekdays" 1 "HeaterTimerRecurrence_Daily" 0 "HeaterTimerRecurrence_None" ;
VAL_ 2499804480 PHTimer2_stat_StartDay_ISig_4 15 "HeaterTimerStartDay_NotAvailable" 14 "HeaterTimerStartDay_Error" 13 "HeaterTimerStartDay_Spare_05" 12 "HeaterTimerStartDay_Spare_04" 11 "HeaterTimerStartDay_Spare_03" 10 "HeaterTimerStartDay_Spare_02" 9 "HeaterTimerStartDay_Spare_01" 8 "HeaterTimerStartDay_Spare" 7 "HeaterTimerStartDay_Sunday" 6 "HeaterTimerStartDay_Saturday" 5 "HeaterTimerStartDay_Friday" 4 "HeaterTimerStartDay_Thursday" 3 "HeaterTimerStartDay_Wednesday" 2 "HeaterTimerStartDay_Tuesday" 1 "HeaterTimerStartDay_Monday" 0 "HeaterTimerStartDay_NotUsed" ;
VAL_ 2499803968 PHTimer1_stat_Status_ISig_4 3 "ParkHeaterTimer_Status_NotAvailable" 2 "ParkHeaterTimer_Status_TimerDeleted" 1 "ParkHeaterTimer_Status_TimerNotActivated" 0 "ParkHeaterTimer_Status_TimerActivated" ;
VAL_ 2499803968 PHTimer1_stat_Temp_ISig_4 31 "TemperatureRqstIndication_cmd_NotAvailable" 30 "TemperatureRqstIndication_cmd_Error" 29 "TemperatureRqstIndication_cmd_Spare_01" 28 "TemperatureRqstIndication_cmd_Spare" 27 "TemperatureRqstIndication_cmd_Max" 26 "TemperatureRqstIndication_cmd_29C" 25 "TemperatureRqstIndication_cmd_28C" 24 "TemperatureRqstIndication_cmd_27C" 23 "TemperatureRqstIndication_cmd_26C" 22 "TemperatureRqstIndication_cmd_25_5C" 21 "TemperatureRqstIndication_cmd_25C" 20 "TemperatureRqstIndication_cmd_24_5C" 19 "TemperatureRqstIndication_cmd_24C" 18 "TemperatureRqstIndication_cmd_23_5C" 17 "TemperatureRqstIndication_cmd_23C" 16 "TemperatureRqstIndication_cmd_22_5C" 15 "TemperatureRqstIndication_cmd_22C" 14 "TemperatureRqstIndication_cmd_21_5C" 13 "TemperatureRqstIndication_cmd_21C" 12 "TemperatureRqstIndication_cmd_20_5C" 11 "TemperatureRqstIndication_cmd_20C" 10 "TemperatureRqstIndication_cmd_19_5C" 9 "TemperatureRqstIndication_cmd_19C" 8 "TemperatureRqstIndication_cmd_18_5C" 7 "TemperatureRqstIndication_cmd_18C" 6 "TemperatureRqstIndication_cmd_17_5C" 5 "TemperatureRqstIndication_cmd_17C" 4 "TemperatureRqstIndication_cmd_16_5C" 3 "TemperatureRqstIndication_cmd_16C" 2 "TemperatureRqstIndication_cmd_15C" 1 "TemperatureRqstIndication_cmd_Min" 0 "TemperatureRqstIndication_cmd_NoTempDisplayed" ;
VAL_ 2499803968 PHTimer1_stat_StartDay_ISig_4 15 "HeaterTimerStartDay_NotAvailable" 14 "HeaterTimerStartDay_Error" 13 "HeaterTimerStartDay_Spare_05" 12 "HeaterTimerStartDay_Spare_04" 11 "HeaterTimerStartDay_Spare_03" 10 "HeaterTimerStartDay_Spare_02" 9 "HeaterTimerStartDay_Spare_01" 8 "HeaterTimerStartDay_Spare" 7 "HeaterTimerStartDay_Sunday" 6 "HeaterTimerStartDay_Saturday" 5 "HeaterTimerStartDay_Friday" 4 "HeaterTimerStartDay_Thursday" 3 "HeaterTimerStartDay_Wednesday" 2 "HeaterTimerStartDay_Tuesday" 1 "HeaterTimerStartDay_Monday" 0 "HeaterTimerStartDay_NotUsed" ;
VAL_ 2499803968 PHTimer1_stat_Recurrence_ISig_4 15 "HeaterTimerRecurrence_NotAvailable" 14 "HeaterTimerRecurrence_Error" 13 "HeaterTimerRecurrence_Spare_3" 12 "HeaterTimerRecurrence_Spare_2" 11 "HeaterTimerRecurrence_Spare_1" 10 "HeaterTimerRecurrence_Sundays" 9 "HeaterTimerRecurrence_Saturdays" 8 "HeaterTimerRecurrence_Fridays" 7 "HeaterTimerRecurrence_Thursdays" 6 "HeaterTimerRecurrence_Wednesdays" 5 "HeaterTimerRecurrence_Tuesdays" 4 "HeaterTimerRecurrence_Mondays" 3 "HeaterTimerRecurrence_Weekends" 2 "HeaterTimerRecurrence_AllWeekdays" 1 "HeaterTimerRecurrence_Daily" 0 "HeaterTimerRecurrence_None" ;
VAL_ 2499801341 EngineTimer_stat_Timer3StartDay_ 15 "HeaterTimerStartDay_NotAvailable" 14 "HeaterTimerStartDay_Error" 13 "HeaterTimerStartDay_Spare_05" 12 "HeaterTimerStartDay_Spare_04" 11 "HeaterTimerStartDay_Spare_03" 10 "HeaterTimerStartDay_Spare_02" 9 "HeaterTimerStartDay_Spare_01" 8 "HeaterTimerStartDay_Spare" 7 "HeaterTimerStartDay_Sunday" 6 "HeaterTimerStartDay_Saturday" 5 "HeaterTimerStartDay_Friday" 4 "HeaterTimerStartDay_Thursday" 3 "HeaterTimerStartDay_Wednesday" 2 "HeaterTimerStartDay_Tuesday" 1 "HeaterTimerStartDay_Monday" 0 "HeaterTimerStartDay_NotUsed" ;
VAL_ 2499801341 EngineTimer_stat_Timer3_Status_I 3 "ParkHeaterTimer_Status_NotAvailable" 2 "ParkHeaterTimer_Status_TimerDeleted" 1 "ParkHeaterTimer_Status_TimerNotActivated" 0 "ParkHeaterTimer_Status_TimerActivated" ;
VAL_ 2499801341 EngineTimer_stat_Timer3Recurr_IS 15 "HeaterTimerRecurrence_NotAvailable" 14 "HeaterTimerRecurrence_Error" 13 "HeaterTimerRecurrence_Spare_3" 12 "HeaterTimerRecurrence_Spare_2" 11 "HeaterTimerRecurrence_Spare_1" 10 "HeaterTimerRecurrence_Sundays" 9 "HeaterTimerRecurrence_Saturdays" 8 "HeaterTimerRecurrence_Fridays" 7 "HeaterTimerRecurrence_Thursdays" 6 "HeaterTimerRecurrence_Wednesdays" 5 "HeaterTimerRecurrence_Tuesdays" 4 "HeaterTimerRecurrence_Mondays" 3 "HeaterTimerRecurrence_Weekends" 2 "HeaterTimerRecurrence_AllWeekdays" 1 "HeaterTimerRecurrence_Daily" 0 "HeaterTimerRecurrence_None" ;
VAL_ 2499801341 EngineTimer_stat_Timer2StartDay_ 15 "HeaterTimerStartDay_NotAvailable" 14 "HeaterTimerStartDay_Error" 13 "HeaterTimerStartDay_Spare_05" 12 "HeaterTimerStartDay_Spare_04" 11 "HeaterTimerStartDay_Spare_03" 10 "HeaterTimerStartDay_Spare_02" 9 "HeaterTimerStartDay_Spare_01" 8 "HeaterTimerStartDay_Spare" 7 "HeaterTimerStartDay_Sunday" 6 "HeaterTimerStartDay_Saturday" 5 "HeaterTimerStartDay_Friday" 4 "HeaterTimerStartDay_Thursday" 3 "HeaterTimerStartDay_Wednesday" 2 "HeaterTimerStartDay_Tuesday" 1 "HeaterTimerStartDay_Monday" 0 "HeaterTimerStartDay_NotUsed" ;
VAL_ 2499801341 EngineTimer_stat_Timer1Recurr_IS 15 "HeaterTimerRecurrence_NotAvailable" 14 "HeaterTimerRecurrence_Error" 13 "HeaterTimerRecurrence_Spare_3" 12 "HeaterTimerRecurrence_Spare_2" 11 "HeaterTimerRecurrence_Spare_1" 10 "HeaterTimerRecurrence_Sundays" 9 "HeaterTimerRecurrence_Saturdays" 8 "HeaterTimerRecurrence_Fridays" 7 "HeaterTimerRecurrence_Thursdays" 6 "HeaterTimerRecurrence_Wednesdays" 5 "HeaterTimerRecurrence_Tuesdays" 4 "HeaterTimerRecurrence_Mondays" 3 "HeaterTimerRecurrence_Weekends" 2 "HeaterTimerRecurrence_AllWeekdays" 1 "HeaterTimerRecurrence_Daily" 0 "HeaterTimerRecurrence_None" ;
VAL_ 2499801341 EngineTimer_stat_Timer2Recurr_IS 15 "HeaterTimerRecurrence_NotAvailable" 14 "HeaterTimerRecurrence_Error" 13 "HeaterTimerRecurrence_Spare_3" 12 "HeaterTimerRecurrence_Spare_2" 11 "HeaterTimerRecurrence_Spare_1" 10 "HeaterTimerRecurrence_Sundays" 9 "HeaterTimerRecurrence_Saturdays" 8 "HeaterTimerRecurrence_Fridays" 7 "HeaterTimerRecurrence_Thursdays" 6 "HeaterTimerRecurrence_Wednesdays" 5 "HeaterTimerRecurrence_Tuesdays" 4 "HeaterTimerRecurrence_Mondays" 3 "HeaterTimerRecurrence_Weekends" 2 "HeaterTimerRecurrence_AllWeekdays" 1 "HeaterTimerRecurrence_Daily" 0 "HeaterTimerRecurrence_None" ;
VAL_ 2499801341 EngineTimer_stat_Timer1StartDay_ 15 "HeaterTimerStartDay_NotAvailable" 14 "HeaterTimerStartDay_Error" 13 "HeaterTimerStartDay_Spare_05" 12 "HeaterTimerStartDay_Spare_04" 11 "HeaterTimerStartDay_Spare_03" 10 "HeaterTimerStartDay_Spare_02" 9 "HeaterTimerStartDay_Spare_01" 8 "HeaterTimerStartDay_Spare" 7 "HeaterTimerStartDay_Sunday" 6 "HeaterTimerStartDay_Saturday" 5 "HeaterTimerStartDay_Friday" 4 "HeaterTimerStartDay_Thursday" 3 "HeaterTimerStartDay_Wednesday" 2 "HeaterTimerStartDay_Tuesday" 1 "HeaterTimerStartDay_Monday" 0 "HeaterTimerStartDay_NotUsed" ;
VAL_ 2499801341 EngineTimer_stat_Timer2_Status_I 3 "ParkHeaterTimer_Status_NotAvailable" 2 "ParkHeaterTimer_Status_TimerDeleted" 1 "ParkHeaterTimer_Status_TimerNotActivated" 0 "ParkHeaterTimer_Status_TimerActivated" ;
VAL_ 2499801341 EngineTimer_stat_Timer1_Status_I 3 "ParkHeaterTimer_Status_NotAvailable" 2 "ParkHeaterTimer_Status_TimerDeleted" 1 "ParkHeaterTimer_Status_TimerNotActivated" 0 "ParkHeaterTimer_Status_TimerActivated" ;
VAL_ 2499801330 PHTimer_rqst_SetAlarmOper_ISig_4 7 "SetAlarmOperation_NotAvailable" 6 "SetAlarmOperation_Error" 5 "SetAlarmOperation_Spare_02" 4 "SetAlarmOperation_Spare_01" 3 "SetAlarmOperation_Reset" 2 "SetAlarmOperation_Continue" 1 "SetAlarmOperation_Stop" 0 "SetAlarmOperation_Start" ;
VAL_ 2499801330 PHTimer_rqst_DayOfWeekRq_ISig_4 15 "DayOfWeekRq_NotAvailable" 14 "DayOfWeekRq_Error" 13 "DayOfWeekRq_Spare_7" 12 "DayOfWeekRq_Spare_6" 11 "DayOfWeekRq_Spare_5" 10 "DayOfWeekRq_Spare_4" 9 "DayOfWeekRq_Spare_3" 8 "DayOfWeekRq_Spare_2" 7 "DayOfWeekRq_NoDay" 6 "DayOfWeekRq_Sunday" 5 "DayOfWeekRq_Saturday" 4 "DayOfWeekRq_Friday" 3 "DayOfWeekRq_Thursday" 2 "DayOfWeekRq_Wednesday" 1 "DayOfWeekRq_Tuesday" 0 "DayOfWeekRq_Monday" ;
VAL_ 2498741568 WindscreenDefrostInd_cmd_ISig_4 1 "IndicationCmd_ONLEDActivated" 0 "IndicationCmd_OFFLEDNotActivated" ;
VAL_ 2498741568 AutoMode_IndicationCmd_ISig_4 1 "IndicationCmd_ONLEDActivated" 0 "IndicationCmd_OFFLEDNotActivated" ;
VAL_ 2498741568 CabTilt_rqst 3 "InactiveActive_NotAvailable" 2 "InactiveActive_Error" 1 "InactiveActive_Active" 0 "InactiveActive_Inactive" ;
VAL_ 2498741568 ACdisplayIndication_Cmd_ISig_4 7 "ACMode_NotAvailable" 6 "ACMode_Error" 5 "ACMode_Spare_01" 4 "ACMode_Spare" 3 "ACMode_ExtraDryCabAir" 2 "ACMode_HumidCabAir" 1 "ACMode_Standard" 0 "ACMode_Economy" ;
VAL_ 2498741568 TemperatureRqstIndication_cmd_IS 31 "TemperatureRqstIndication_cmd_NotAvailable" 30 "TemperatureRqstIndication_cmd_Error" 29 "TemperatureRqstIndication_cmd_Spare_01" 28 "TemperatureRqstIndication_cmd_Spare" 27 "TemperatureRqstIndication_cmd_Max" 26 "TemperatureRqstIndication_cmd_29C" 25 "TemperatureRqstIndication_cmd_28C" 24 "TemperatureRqstIndication_cmd_27C" 23 "TemperatureRqstIndication_cmd_26C" 22 "TemperatureRqstIndication_cmd_25_5C" 21 "TemperatureRqstIndication_cmd_25C" 20 "TemperatureRqstIndication_cmd_24_5C" 19 "TemperatureRqstIndication_cmd_24C" 18 "TemperatureRqstIndication_cmd_23_5C" 17 "TemperatureRqstIndication_cmd_23C" 16 "TemperatureRqstIndication_cmd_22_5C" 15 "TemperatureRqstIndication_cmd_22C" 14 "TemperatureRqstIndication_cmd_21_5C" 13 "TemperatureRqstIndication_cmd_21C" 12 "TemperatureRqstIndication_cmd_20_5C" 11 "TemperatureRqstIndication_cmd_20C" 10 "TemperatureRqstIndication_cmd_19_5C" 9 "TemperatureRqstIndication_cmd_19C" 8 "TemperatureRqstIndication_cmd_18_5C" 7 "TemperatureRqstIndication_cmd_18C" 6 "TemperatureRqstIndication_cmd_17_5C" 5 "TemperatureRqstIndication_cmd_17C" 4 "TemperatureRqstIndication_cmd_16_5C" 3 "TemperatureRqstIndication_cmd_16C" 2 "TemperatureRqstIndication_cmd_15C" 1 "TemperatureRqstIndication_cmd_Min" 0 "TemperatureRqstIndication_cmd_NoTempDisplayed" ;
VAL_ 2498741568 Pto3CabRequest 3 "OffOn_NotAvailable" 2 "OffOn_Error" 1 "OffOn_On" 0 "OffOn_Off" ;
VAL_ 2498741568 Pto4CabRequest 3 "OffOn_NotAvailable" 2 "OffOn_Error" 1 "OffOn_On" 0 "OffOn_Off" ;
VAL_ 2498741568 SRSAirbagStatus_ISig_4 3 "SRSAirbagStatus_NotAvailable" 2 "SRSAirbagStatus_ErrorIndicator" 1 "SRSAirbagStatus_DriverAirbagDeployed" 0 "SRSAirbagStatus_NoAirbagDeployed" ;
VAL_ 2498741568 Area_9level_Indication_cmd_ISig_ 15 "Area_9Level_NotAvailable" 14 "Area_9Level_Error" 13 "Area_9Level_Spare_3" 12 "Area_9Level_Spare_2" 11 "Area_9Level_NoAirDistibutionSegmentDisplayed" 10 "Area_9Level_AllClosed" 9 "Area_9Level_UP1_FRONT1_DOWN1" 8 "Area_9Level_UP0_FRONT1_DOWN2" 7 "Area_9Level_UP0_FRONT2_DOWN1" 6 "Area_9Level_UP2_FRONT0_DOWN1" 5 "Area_9Level_UP2_FRONT1_DOWN0" 4 "Area_9Level_UP1_FRONT0_DOWN2" 3 "Area_9Level_UP1_FRONT2_DOWN0" 2 "Area_9Level_UP0_FRONT0_DOWN3" 1 "Area_9Level_UP0_FRONT3_DOWN0" 0 "Area_9Level_UP3_FRONT0_DOWN0" ;
VAL_ 2498741568 AutoDefogIndication_Cmd_ISig_4 7 "AutoDefogmode_NotAvailable" 6 "AutoDefogmode_Error" 5 "AutoDefogmode_Spare_01" 4 "AutoDefogmode_Spare" 3 "AutoDefogmode_Moderate" 2 "AutoDefogmode_Normal" 1 "AutoDefogmode_Sensitive" 0 "AutoDefogmode_OFF" ;
VAL_ 2498741568 FrontLidAjar_Stat 3 "ClosedOpen_NotAvailable" 2 "ClosedOpen_Error" 1 "ClosedOpen_Open" 0 "ClosedOpen_Closed" ;
VAL_ 2498741568 ParkingHeaterCleaning_Rqst_ISig_ 3 "Request_NotAvailable" 2 "Request_Error" 1 "Request_RequestActive" 0 "Request_NotRequested" ;
VAL_ 2498741568 Pto2CabRequest 3 "OffOn_NotAvailable" 2 "OffOn_Error" 1 "OffOn_On" 0 "OffOn_Off" ;
VAL_ 2498741568 AutoBlowerLevelIndication_Cmd_IS 7 "AutoBlowerLevel_NotAvailable" 6 "AutoBlowerLevel_Error" 5 "AutoBlowerLevel_Spare_02" 4 "AutoBlowerLevel_Spare_01" 3 "AutoBlowerLevel_Spare" 2 "AutoBlowerLevel_Low" 1 "AutoBlowerLevel_Normal" 0 "AutoBlowerLevel_High" ;
VAL_ 2498741568 SeatSwivelWarning_rqst 3 "InactiveActive_NotAvailable" 2 "InactiveActive_Error" 1 "InactiveActive_Active" 0 "InactiveActive_Inactive" ;
VAL_ 2498741568 AQSmodeIndication_Cmd_ISig_4 3 "AQSMode_NotAvailable" 2 "AQSMode_Error" 1 "AQSMode_Auto" 0 "AQSMode_OFF" ;
VAL_ 2498741568 TemporaryRSLDriverRequest 3 "OffOn_NotAvailable" 2 "OffOn_Error" 1 "OffOn_On" 0 "OffOn_Off" ;
VAL_ 2498741568 Pto1CabRequest 3 "OffOn_NotAvailable" 2 "OffOn_Error" 1 "OffOn_On" 0 "OffOn_Off" ;
VAL_ 2483023936 LCS_EnableSwitch_rqst 3 "OffOn_NotAvailable" 2 "OffOn_Error" 1 "OffOn_On" 0 "OffOn_Off" ;
VAL_ 2483023936 PH_Activation_cmd_ISig_4 7 "PH_Activation_cmd_NotAvailable" 6 "PH_Activation_cmd_Error" 5 "PH_Activation_cmd_Spare_01" 4 "PH_Activation_cmd_Spare" 3 "PH_Activation_cmd_ParkingHeaterONForced" 2 "PH_Activation_cmd_ParkingHeaterON" 1 "PH_Activation_cmd_ParkingHeaterOFFShortStop" 0 "PH_Activation_cmd_ParkingHeaterOFF" ;
VAL_ 2483023936 EscCrossCountryActivation_rqst 3 "DisableEnable_NotAvailable" 2 "DisableEnable_Error" 1 "DisableEnable_Enable" 0 "DisableEnable_Disable" ;
VAL_ 2483023936 StaticCornerLightMode 3 "DisableEnable_NotAvailable" 2 "DisableEnable_Error" 1 "DisableEnable_Enable" 0 "DisableEnable_Disable" ;
VAL_ 2483023936 SplitBoxDifflockActvnDrvrRqst_IS 3 "DisengageEngage_NotAvailable" 2 "DisengageEngage_Error" 1 "DisengageEngage_Engage" 0 "DisengageEngage_Disengage" ;
VAL_ 2483023936 ConstructionSwitch_stat 3 "OffOn_NotAvailable" 2 "OffOn_Error" 1 "OffOn_On" 0 "OffOn_Off" ;
VAL_ 2483023936 ATCFrontWheelDriveRequest 3 "AutomaticOffOn_NotAvailable" 2 "AutomaticOffOn_Error" 1 "AutomaticOffOn_AutomaticOn" 0 "AutomaticOffOn_AutomaticOff" ;
VAL_ 2483023936 EscCabActionRequest 7 "EscActionRequest_NotAvailable" 6 "EscActionRequest_Error" 5 "EscActionRequest_Spare" 4 "EscActionRequest_Set" 3 "EscActionRequest_Decrease" 2 "EscActionRequest_Increase" 1 "EscActionRequest_Resume" 0 "EscActionRequest_NoRequest" ;
VAL_ 2483023936 AdjustRequestForIdle 7 "EngineSpeedRequest_NotAvailable" 6 "EngineSpeedRequest_Error" 5 "EngineSpeedRequest_Spare" 4 "EngineSpeedRequest_Decrease" 3 "EngineSpeedRequest_Increase" 2 "EngineSpeedRequest_Activate" 1 "EngineSpeedRequest_Off" 0 "EngineSpeedRequest_NoRequest" ;
VAL_ 2483023936 SCL_LogicPowerOutput_stat 3 "SCL_PowerOutput_stat_NotAvailable" 2 "SCL_PowerOutput_stat_Error" 1 "SCL_PowerOutput_stat_FaultDetected" 0 "SCL_PowerOutput_stat_NoFaultDetected" ;
VAL_ 2483023936 StatTrailerBrakeSwitchStatus 3 "PushButtonStatus_NotAvailable" 2 "PushButtonStatus_Error" 1 "PushButtonStatus_Pushed" 0 "PushButtonStatus_Neutral" ;
VAL_ 2483023936 RoofHatch_HMI_rqst 7 "RoofHatch_HMI_rqst_NotAvailable" 6 "RoofHatch_HMI_rqst_ErrorIndicator" 5 "RoofHatch_HMI_rqst_SpareValue_02" 4 "RoofHatch_HMI_rqst_SpareValue_01" 3 "RoofHatch_HMI_rqst_SpareValue" 2 "RoofHatch_HMI_rqst_Open" 1 "RoofHatch_HMI_rqst_Close" 0 "RoofHatch_HMI_rqst_NoAction" ;
VAL_ 2483023936 EscCabEnable 3 "DisableEnable_NotAvailable" 2 "DisableEnable_Error" 1 "DisableEnable_Enable" 0 "DisableEnable_Disable" ;
VAL_ 2483023936 ExtraSideMarkers_Rqst 3 "NeutralPushed_NotAvailable" 2 "NeutralPushed_Error" 1 "NeutralPushed_Pushed" 0 "NeutralPushed_Neutral" ;
VAL_ 2483023936 LevelingThumbwheel_stat 31 "Thumbwheel_stat_NotAvaliable" 30 "Thumbwheel_stat_Error" 29 "Thumbwheel_stat_Spare_12" 28 "Thumbwheel_stat_Spare_11" 27 "Thumbwheel_stat_Spare_10" 26 "Thumbwheel_stat_Spare_09" 25 "Thumbwheel_stat_Spare_08" 24 "Thumbwheel_stat_Spare_07" 23 "Thumbwheel_stat_Spare_06" 22 "Thumbwheel_stat_Spare_05" 21 "Thumbwheel_stat_Spare_04" 20 "Thumbwheel_stat_Spare_03" 19 "Thumbwheel_stat_Spare_02" 18 "Thumbwheel_stat_Spare_01" 17 "Thumbwheel_stat_Spare" 16 "Thumbwheel_stat_ThumbWheelPos16" 15 "Thumbwheel_stat_ThumbWheelPos15" 14 "Thumbwheel_stat_ThumbWheelPos14" 13 "Thumbwheel_stat_ThumbWheelPos13" 12 "Thumbwheel_stat_ThumbWheelPos12" 11 "Thumbwheel_stat_ThumbWheelPos11" 10 "Thumbwheel_stat_ThumbWheelPos10" 9 "Thumbwheel_stat_ThumbWheelPos9" 8 "Thumbwheel_stat_ThumbWheelPos8" 7 "Thumbwheel_stat_ThumbWheelPos7" 6 "Thumbwheel_stat_ThumbWheelPos6" 5 "Thumbwheel_stat_ThumbWheelPos5" 4 "Thumbwheel_stat_ThumbWheelPos4" 3 "Thumbwheel_stat_ThumbWheelPos3" 2 "Thumbwheel_stat_ThumbWheelPos2" 1 "Thumbwheel_stat_ThumbWheelPos1" 0 "Thumbwheel_stat_ThumbWheelPos0" ;
VAL_ 2483023936 MemoDisplayIndication_Cmd_ISig_4 7 "Memo_Status_NotAvailable" 6 "Memo_Status_Error" 5 "Memo_Status_Spare_01" 4 "Memo_Status_Spare" 3 "Memo_Status_AirDistributionRecall" 2 "Memo_Status_AirDistributionMemorized" 1 "Memo_Status_NoAirDistributionMemorized" 0 "Memo_Status_OFF" ;
VAL_ 2483023936 FCW_Enable 3 "DisableEnable_NotAvailable" 2 "DisableEnable_Error" 1 "DisableEnable_Enable" 0 "DisableEnable_Disable" ;
VAL_ 2483023936 DASActivation_rqst 3 "OffOn_NotAvailable" 2 "OffOn_Error" 1 "OffOn_On" 0 "OffOn_Off" ;
VAL_ 2483023936 DriverSeatBeltSwitch_ISig_4 3 "DriverSeatBeltSwitch_NotAvailable" 2 "DriverSeatBeltSwitch_Error" 1 "DriverSeatBeltSwitch_SeatBeltBuckledFastened" 0 "DriverSeatBeltSwitch_SeatBeltUnbuckledUnfastened" ;
VAL_ 2483023936 PinCode_stat 7 "PinCode_stat_NotAvailable" 6 "PinCode_stat_Error" 3 "PinCode_stat_GoodPinCode" 2 "PinCode_stat_WrongPinCode" 1 "PinCode_stat_NoPinCodeEntered" 0 "PinCode_stat_Idle" ;
VAL_ 2483023936 WarmUp_Request 3 "DisableEnable_NotAvailable" 2 "DisableEnable_Error" 1 "DisableEnable_Enable" 0 "DisableEnable_Disable" ;
VAL_ 2483023936 LKSEnableSwitch_rqst 3 "OffOn_NotAvailable" 2 "OffOn_Error" 1 "OffOn_On" 0 "OffOn_Off" ;
VAL_ 2515579712 AlmClkSnze_LECM_rqst_ID_ISig_4 127 "AlarmClkID_NotAvailable" 126 "AlarmClkID_Error" 10 "AlarmClkID_Alarm10" 9 "AlarmClkID_Alarm9" 8 "AlarmClkID_Alarm8" 7 "AlarmClkID_Alarm7" 6 "AlarmClkID_Alarm6" 5 "AlarmClkID_Alarm5" 4 "AlarmClkID_Alarm4" 3 "AlarmClkID_Alarm3" 2 "AlarmClkID_Alarm2" 1 "AlarmClkID_Alarm1" 0 "AlarmClkID_NotUsed" ;
VAL_ 2515579712 AlmClkSetCurAlm_rqst_ID 127 "AlarmClkID_NotAvailable" 126 "AlarmClkID_Error" 10 "AlarmClkID_Alarm10" 9 "AlarmClkID_Alarm9" 8 "AlarmClkID_Alarm8" 7 "AlarmClkID_Alarm7" 6 "AlarmClkID_Alarm6" 5 "AlarmClkID_Alarm5" 4 "AlarmClkID_Alarm4" 3 "AlarmClkID_Alarm3" 2 "AlarmClkID_Alarm2" 1 "AlarmClkID_Alarm1" 0 "AlarmClkID_NotUsed" ;
VAL_ 2515579712 AlmClkSnze_LECM_rqst_Action_ISig 7 "AlmClkSnzeAction_NotAvailable" 6 "AlmClkSnzeAction_Error" 5 "AlmClkSnzeAction_Spare02" 4 "AlmClkSnzeAction_Spare01" 3 "AlmClkSnzeAction_Spare" 2 "AlmClkSnzeAction_RequestToTurnAlarmOff" 1 "AlmClkSnzeAction_RequestToSnoozeAlarm" 0 "AlmClkSnzeAction_NoRequest" ;
VAL_ 2515579712 AlmClkSetCurAlm_rqst_Stat 3 "AlarmClkStat_Spare" 2 "AlarmClkStat_NoUsed" 1 "AlarmClkStat_Active" 0 "AlarmClkStat_Inactive" ;
VAL_ 2515579712 CollSituationHMICtrlRequestVM_IS 7 "CollSituationHMICtrlRequestVM_NotAvailable" 6 "CollSituationHMICtrlRequestVM_Spare4" 5 "CollSituationHMICtrlRequestVM_Spare3" 4 "CollSituationHMICtrlRequestVM_Spare2" 3 "CollSituationHMICtrlRequestVM_Spare1" 2 "CollSituationHMICtrlRequestVM_FCWdisabledOnAftermarket" 1 "CollSituationHMICtrlRequestVM_CM_FCWdisabledOnAftermarket" 0 "CollSituationHMICtrlRequestVM_NoIndication" ;
VAL_ 2515579712 AlmClkSetCurAlm_rqst_Type 7 "AlarmClkType_NotAvailable" 6 "AlarmClkType_Error" 5 "AlarmClkType_Reserved_02" 4 "AlarmClkType_Reserved_01" 3 "AlarmClkType_Reserved" 2 "AlarmClkType_Radio" 1 "AlarmClkType_Buzzer" 0 "AlarmClkType_NoAudibleNotification" ;
VAL_ 2515579712 WRC_Docking_stat_ISig_4 3 "Docking_stat_NotAvailable" 2 "Docking_stat_Error" 1 "Docking_stat_Docked" 0 "Docking_stat_Undocked" ;
VAL_ 2482995008 Regeneration2PosSwitchStatus 3 "A2PosSwitchStatus_NotAvailable" 2 "A2PosSwitchStatus_Error" 1 "A2PosSwitchStatus_On" 0 "A2PosSwitchStatus_Off" ;
VAL_ 2482995008 WRCEngineStopRequest_ISig_4 3 "PushButtonStatus_NotAvailable" 2 "PushButtonStatus_Error" 1 "PushButtonStatus_Pushed" 0 "PushButtonStatus_Neutral" ;
VAL_ 2482995008 LiftAxle1DirectControl_ISig_4 7 "LiftAxleLiftPositionRequest_NotAvailable" 6 "LiftAxleLiftPositionRequest_Error" 5 "LiftAxleLiftPositionRequest_Reserved_02" 4 "LiftAxleLiftPositionRequest_Reserved_01" 3 "LiftAxleLiftPositionRequest_Reserved" 2 "LiftAxleLiftPositionRequest_Up" 1 "LiftAxleLiftPositionRequest_Down" 0 "LiftAxleLiftPositionRequest_Idle" ;
VAL_ 2482995008 PanicAlarmFromKeyfob_rqst 3 "Request_NotAvailable" 2 "Request_Error" 1 "Request_RequestActive" 0 "Request_NotRequested" ;
VAL_ 2482995008 InhibRegenerationSwitch_stat 3 "A2PosSwitchStatus_NotAvailable" 2 "A2PosSwitchStatus_Error" 1 "A2PosSwitchStatus_On" 0 "A2PosSwitchStatus_Off" ;
VAL_ 2482995008 ParkingClimate_IndicationCmd_ISi 7 "ParkingClimate_IndicationCmd_NotAvailable" 6 "ParkingClimate_IndicationCmd_Error" 5 "ParkingClimate_IndicationCmd_Spare_01" 4 "ParkingClimate_IndicationCmd_ShortStopHeaterActivated" 3 "ParkingClimate_IndicationCmd_ParkCoolWithoutCompActivReducedMode" 2 "ParkingClimate_IndicationCmd_ParkCoolWithCompActivFullMode" 1 "ParkingClimate_IndicationCmd_ParkingHeaterActivated" 0 "ParkingClimate_IndicationCmd_NoSystemActivated" ;
VAL_ 2482995008 DriverDoorAjar_stat_ISig_4 7 "DoorAjar_stat_NotAvailable" 6 "DoorAjar_stat_Error" 2 "DoorAjar_stat_DoorOpen" 1 "DoorAjar_stat_DoorClosed" 0 "DoorAjar_stat_Idle" ;
VAL_ 2482995008 WRCEngineStartRequest_ISig_4 3 "PushButtonStatus_NotAvailable" 2 "PushButtonStatus_Error" 1 "PushButtonStatus_Pushed" 0 "PushButtonStatus_Neutral" ;
VAL_ 2482995008 RegenerationPushButtonStatus_ISi 3 "PushButtonStatus_NotAvailable" 2 "PushButtonStatus_Error" 1 "PushButtonStatus_Pushed" 0 "PushButtonStatus_Neutral" ;
VAL_ 2482995008 RegenerationSwitchStatus_ISig_4 7 "A3PosSwitchStatus_NotAvailable" 6 "A3PosSwitchStatus_Error" 5 "A3PosSwitchStatus_Spare_02" 4 "A3PosSwitchStatus_Spare_01" 3 "A3PosSwitchStatus_Spare" 2 "A3PosSwitchStatus_Upper" 1 "A3PosSwitchStatus_Lower" 0 "A3PosSwitchStatus_Middle" ;
VAL_ 2482995008 DoorLock_stat_ISig_4 15 "DoorLock_stat_NotAvailable" 14 "DoorLock_stat_Error" 4 "DoorLock_stat_BothDoorsAreLocked" 3 "DoorLock_stat_PassengerDoorIsUnlocked" 2 "DoorLock_stat_DriverDoorIsUnlocked" 1 "DoorLock_stat_BothDoorsAreUnlocked" 0 "DoorLock_stat_Idle" ;
VAL_ 2482995008 LuggageAjar_stat_ISig_4 7 "DoorAjar_stat_NotAvailable" 6 "DoorAjar_stat_Error" 2 "DoorAjar_stat_DoorOpen" 1 "DoorAjar_stat_DoorClosed" 0 "DoorAjar_stat_Idle" ;
VAL_ 2482995008 AlarmStatus_stat_ISig_4 15 "AlarmStatus_stat_NotAvailable" 14 "AlarmStatus_stat_Error" 13 "AlarmStatus_stat_Spare_06" 12 "AlarmStatus_stat_Spare_05" 11 "AlarmStatus_stat_Spare_04" 10 "AlarmStatus_stat_Spare_03" 9 "AlarmStatus_stat_Spare_02" 8 "AlarmStatus_stat_Spare_01" 7 "AlarmStatus_stat_TamperMode" 6 "AlarmStatus_stat_ServiceMode" 5 "AlarmStatus_stat_AlarmMode" 4 "AlarmStatus_stat_PanicMode" 3 "AlarmStatus_stat_UnsetMode" 2 "AlarmStatus_stat_ReduceSetMode" 1 "AlarmStatus_stat_SetMode" 0 "AlarmStatus_stat_Idle" ;
VAL_ 2482995008 AlarmTriggeringCause_stat_ISig_4 15 "AlarmTriggeringCause_stat_NotAvailable" 14 "AlarmTriggeringCause_stat_Error" 10 "AlarmTriggeringCause_stat_OtherTamperIssues" 9 "AlarmTriggeringCause_stat_DoorsConnectionTampered" 8 "AlarmTriggeringCause_stat_SirenConnectionTampered" 7 "AlarmTriggeringCause_stat_TrailerAlarmTriggered" 6 "AlarmTriggeringCause_stat_FrontHatchOpened" 5 "AlarmTriggeringCause_stat_LuggageCompartementOpened" 4 "AlarmTriggeringCause_stat_CabTilted" 3 "AlarmTriggeringCause_stat_MotionSensorTriggered" 2 "AlarmTriggeringCause_stat_PassengerDoorOpened" 1 "AlarmTriggeringCause_stat_DriverDoorOpened" 0 "AlarmTriggeringCause_stat_Idle" ;
VAL_ 2482995008 DoorsAjar_stat_ISig_4 7 "DoorsAjar_stat_NotAvailable" 6 "DoorsAjar_stat_Error" 5 "DoorsAjar_stat_Spare" 4 "DoorsAjar_stat_BothDoorsAreOpen" 3 "DoorsAjar_stat_PassengerDoorIsOpen" 2 "DoorsAjar_stat_DriverDoorIsOpen" 1 "DoorsAjar_stat_BothDoorsAreClosed" 0 "DoorsAjar_stat_Idle" ;
VAL_ 2482995008 DoorAutoFunction_rqst 3 "OffOn_NotAvailable" 2 "OffOn_Error" 1 "OffOn_On" 0 "OffOn_Off" ;
SIG_GROUP_ 2432640336 GlareFreeArea02_sg_ISig_4 1 : GlareFreeArea02_LeftAngle_ISig_4 GlareFreeArea02_RightAngle_ISig_ GlareFreeArea02_Distance_ISig_4;
SIG_GROUP_ 2432639568 GlareFreeArea03_sg_ISig_4 1 : GlareFreeArea03_Distance_ISig_4 GlareFreeArea03_LeftAngle_ISig_4 GlareFreeArea03_RightAngle_ISig_;
SIG_GROUP_ 2432639568 GlareFreeArea01_sg_ISig_4 1 : GlareFreeArea01_LeftAngle_ISig_4 GlareFreeArea01_Distance_ISig_4 GlareFreeArea01_RightAngle_ISig_;
SIG_GROUP_ 2466246992 XARDACU_sg 1 : XARDACU_ControlMode XARDACU_AccelDemand;
SIG_GROUP_ 2432690512 ACC_SGOFaultCondStat_sg_ISig_4 1 : ACC_SGOFaultCondStat_SeatBelt_IS ACC_SGOFaultCondStat_SigStat_ISi ACC_SGOFaultCondStat_Target_ISig ACC_SGOFaultCondStat_Door_ISig_4 ACC_SGOFaultCondStat_Other_ISig_ ACC_SGOFaultCondStat_Speed_ISig_;
SIG_GROUP_ 2490646336 MediaSourcesListReq_sg_ISig_4 1 : MediaSourcesListReq_SInfo_ISig_4 MediaSourcesListReq_Items_ISig_4 MediaSourcesListReq_ItemID_ISig_;
SIG_GROUP_ 2499780850 AlmClkSetAlm_LECM_rq_sg_ISig_4 1 : AlmClkSetAlm_LECM_rq_Type_ISig_4 AlmClkSetAlm_LECM_rq_ID_ISig_4 AlmClkSetAlm_LECM_rq_SetHr_ISig_ AlmClkSetAlm_LECM_rq_Stat_ISig_4 AlmClkSetAlm_LECM_rq_SetMin_ISig AlmClkSetAlm_LECM_rq_DaySet_ISig AlmClkSetAlm_LECM_rq_Mode_ISig_4;
SIG_GROUP_ 2499804480 PHTimer3_stat_sg_ISig_4 1 : PHTimer3_stat_Recurrence_ISig_4 PHTimer3_stat_StartDay_ISig_4 PHTimer3_stat_Hours_ISig_4 PHTimer3_stat_Status_ISig_4 PHTimer3_stat_Minutes_ISig_4 PHTimer3_stat_Temp_ISig_4;
SIG_GROUP_ 2499804480 PHTimer2_stat_sg_ISig_4 1 : PHTimer2_stat_Hours_ISig_4 PHTimer2_stat_Status_ISig_4 PHTimer2_stat_Temp_ISig_4 PHTimer2_stat_Recurrence_ISig_4 PHTimer2_stat_StartDay_ISig_4 PHTimer2_stat_Minutes_ISig_4;
SIG_GROUP_ 2499803968 PHTimer1_stat_sg_ISig_4 1 : PHTimer1_stat_Minutes_ISig_4 PHTimer1_stat_Status_ISig_4 PHTimer1_stat_Temp_ISig_4 PHTimer1_stat_Hours_ISig_4 PHTimer1_stat_StartDay_ISig_4 PHTimer1_stat_Duration_ISig_4 PHTimer1_stat_Recurrence_ISig_4;
SIG_GROUP_ 2499801341 EngineTimer_stat_sg_ISig_4 1 : EngineTimer_stat_Timer3StartDay_ EngineTimer_stat_Timer3_Status_I EngineTimer_stat_Timer3Minutes_I EngineTimer_stat_Timer3Hours_ISi EngineTimer_stat_Timer3Recurr_IS EngineTimer_stat_Timer1Hours_ISi EngineTimer_stat_Timer2Hours_ISi EngineTimer_stat_Timer2StartDay_ EngineTimer_stat_Timer1Recurr_IS EngineTimer_stat_Timer2Recurr_IS EngineTimer_stat_Timer1Minutes_I EngineTimer_stat_Timer1StartDay_ EngineTimer_stat_Timer2_Status_I EngineTimer_stat_Timer2Minutes_I EngineTimer_stat_Timer1_Status_I;
SIG_GROUP_ 2499801330 PHTimer_rqst_sg_ISig_4 1 : PHTimer_rqst_Hours_ISig_4 PHTimer_rqst_Minutes_ISig_4 PHTimer_rqst_SetAlarmOper_ISig_4 PHTimer_rqst_DayOfWeekRq_ISig_4;
SIG_GROUP_ 2515579712 AlmClkSnze_LECM_rqst_sg_ISig_4 1 : AlmClkSnze_LECM_rqst_ID_ISig_4 AlmClkSnze_LECM_rqst_Action_ISig;
SIG_GROUP_ 2515579712 AlmClkSetCurAlm_rqst_sg 1 : AlmClkSetCurAlm_rqst_ID AlmClkSetCurAlm_rqst_Stat AlmClkSetCurAlm_rqst_SetMin AlmClkSetCurAlm_rqst_SetHr AlmClkSetCurAlm_rqst_Type;
